VERSION "eCMP INFO-DIV vehicle review 2026-11-03; 125000 bit/s; PSA-RE 67f7581e7622410efdbb29c7eda3b86982b9b450; Apache-2.0"

NS_ :

BS_:

BU_: AAS AMPLI AVP BCM BGP BSG BSI BTA BTEL BTT CDC CMB CRT DIAG_TOOL EDP_C EMF FMUX IC ICSV IDVR IVC_D MATT MDS OVIP PDS_C RAD RBG SDCM VTH WLC

BO_ 0 ICSV_SeatClimateModuleSta_196f6d: 8 ICSV
 SG_ RawByte8 : 63|8@0+ (1,0) [0|255] "raw" Vector__XXX
 SG_ EspDisconnectRequest : 48|1@0+ (1,0) [0|1] ""  AAS,AVP,BTEL,CMB,MDS,OVIP
 SG_ BrakeAssistFaultLampRequest : 49|1@0+ (1,0) [0|1] ""  AAS,AVP,BTEL,CMB,MDS,OVIP
 SG_ StaticSlopeState : 51|2@0+ (1,0) [0|3] ""  AAS,AVP,BTEL,CMB,MDS,OVIP
 SG_ BrakeFunctionNeedForStartStop : 53|2@0+ (1,0) [0|3] ""  AAS,AVP,BTEL,CMB,MDS,OVIP
 SG_ BrakeEcuPowerManagementFault : 54|1@0+ (1,0) [0|1] ""  AAS,AVP,BTEL,CMB,MDS,OVIP
 SG_ EmergencyBrakingSignaliza_517ee3 : 55|1@0+ (1,0) [0|1] ""  AAS,AVP,BTEL,CMB,MDS,OVIP
 SG_ BatteryVoltageUcBrake : 47|8@0+ (0.057,0) [7|18.5] "V"  AAS,AVP,BTEL,CMB,MDS,OVIP
 SG_ RearRightWheelSpinCounter : 30|15@0+ (1,0) [0|32767] ""  AAS,AVP,BTEL,CMB,MDS,OVIP
 SG_ RearRightWheelSpeedSensorFault : 31|1@0+ (1,0) [0|1] ""  AAS,AVP,BTEL,CMB,MDS,OVIP
 SG_ RearLeftWheelSpinCounter : 14|15@0+ (1,0) [0|32767] ""  AAS,AVP,BTEL,CMB,MDS,OVIP
 SG_ RearLeftWheelSpeedSensorFault : 15|1@0+ (1,0) [0|1] ""  AAS,AVP,BTEL,CMB,MDS,OVIP
 SG_ AbsFaultLampRequest : 0|1@0+ (1,0) [0|1] ""  AAS,AVP,BTEL,CMB,MDS,OVIP
 SG_ BrakeFluidLevelAlert : 1|1@0+ (1,0) [0|1] ""  AAS,AVP,BTEL,CMB,MDS,OVIP
 SG_ WornBrakePadsIndicator : 2|1@0+ (1,0) [0|1] ""  AAS,AVP,BTEL,CMB,MDS,OVIP
 SG_ RefInProgress : 3|1@0+ (1,0) [0|1] ""  AAS,AVP,BTEL,CMB,MDS,OVIP
 SG_ AutomaticHazardLightsByUcBrake : 4|1@0+ (1,0) [0|1] ""  AAS,AVP,BTEL,CMB,MDS,OVIP
 SG_ AbsInProgress : 5|1@0+ (1,0) [0|1] ""  AAS,AVP,BTEL,CMB,MDS,OVIP
 SG_ RawBits1_1 : 6|1@0+ (1,0) [0|1] "raw" Vector__XXX
 SG_ RefFaultLamp : 7|1@0+ (1,0) [0|1] ""  AAS,AVP,BTEL,CMB,MDS,OVIP

BO_ 1 BSI_RapidCommand: 1 BSI
 SG_ Unused1 : 6|7@0+ (1,0) [0|127] ""  SDCM
 SG_ UidTableLearnRequestToBsi : 7|1@0+ (1,0) [0|1] ""  SDCM

BO_ 2 BSI_AdditivePumpStatus: 7 BSI
 SG_ AcPrecondSchedule2StartTime : 42|11@0+ (1,0) [0|1440] "min"  BTEL,MDS,OVIP
 SG_ RawBits40_44 : 47|5@0+ (1,0) [0|31] "raw" Vector__XXX
 SG_ AcPrecondSundaySchedule2Active : 32|1@0+ (1,0) [0|1] ""  BTEL,MDS,OVIP
 SG_ AcPrecondSaturdaySchedule2Active : 33|1@0+ (1,0) [0|1] ""  BTEL,MDS,OVIP
 SG_ AcPrecondFridaySchedule2Active : 34|1@0+ (1,0) [0|1] ""  BTEL,MDS,OVIP
 SG_ AcPrecondThursdaySchedule2Active : 35|1@0+ (1,0) [0|1] ""  BTEL,MDS,OVIP
 SG_ AcPrecondWednesdaySchedul_14303b : 36|1@0+ (1,0) [0|1] ""  BTEL,MDS,OVIP
 SG_ AcPrecondTuesdaySchedule2Active : 37|1@0+ (1,0) [0|1] ""  BTEL,MDS,OVIP
 SG_ AcPrecondMondaySchedule2Active : 38|1@0+ (1,0) [0|1] ""  BTEL,MDS,OVIP
 SG_ AcPrecondSchedule2Enabled : 39|1@0+ (1,0) [0|1] ""  BTEL,MDS,OVIP
 SG_ AcPrecondSchedule1StartTime : 18|11@0+ (1,0) [0|1440] "min"  BTEL,MDS,OVIP
 SG_ RawBits16_20 : 23|5@0+ (1,0) [0|31] "raw" Vector__XXX
 SG_ AcPrecondSundaySchedule1Active : 8|1@0+ (1,0) [0|1] ""  BTEL,MDS,OVIP
 SG_ AcPrecondSaturdaySchedule1Active : 9|1@0+ (1,0) [0|1] ""  BTEL,MDS,OVIP
 SG_ AcPrecondFridaySchedule1Active : 10|1@0+ (1,0) [0|1] ""  BTEL,MDS,OVIP
 SG_ AcPrecondThursdaySchedule1Active : 11|1@0+ (1,0) [0|1] ""  BTEL,MDS,OVIP
 SG_ AcPrecondWednesdaySchedul_0079d6 : 12|1@0+ (1,0) [0|1] ""  BTEL,MDS,OVIP
 SG_ AcPrecondTuesdaySchedule1Active : 13|1@0+ (1,0) [0|1] ""  BTEL,MDS,OVIP
 SG_ AcPrecondMondaySchedule1Active : 14|1@0+ (1,0) [0|1] ""  BTEL,MDS,OVIP
 SG_ AcPrecondSchedule1Enabled : 15|1@0+ (1,0) [0|1] ""  BTEL,MDS,OVIP
 SG_ RawBits6_7 : 1|2@0+ (1,0) [0|3] "raw" Vector__XXX
 SG_ AcPrecondAsapModeActive : 2|1@0+ (1,0) [0|1] ""  BTEL,MDS,OVIP
 SG_ AcPrecondStatusFeedback : 6|4@0+ (1,0) [0|15] ""  BTEL,MDS,OVIP
 SG_ AcPrecondStatusAvailability : 7|1@0+ (1,0) [0|1] ""  BTEL,MDS,OVIP

BO_ 24 BSI_AirIntakeMotorCommand3: 5 BSI
 SG_ Unused4 : 39|8@0+ (1,0) [0|255] ""  RAD,MDS,IDVR,BTEL
 SG_ Unused3 : 30|7@0+ (1,0) [0|127] ""  RAD,MDS,IDVR,BTEL
 SG_ Unused2 : 31|1@0+ (1,0) [0|1] ""  RAD,MDS,IDVR,BTEL
 SG_ PedestrianCrashInfo : 16|1@0+ (1,0) [0|1] ""  RAD,MDS,IDVR,BTEL
 SG_ AutomaticEcallTrigger : 18|2@0+ (1,0) [0|3] ""  RAD,MDS,IDVR,BTEL
 SG_ Unused1 : 22|4@0+ (1,0) [0|15] ""  RAD,MDS,IDVR,BTEL
 SG_ CrashUnlockRequest : 23|1@0+ (1,0) [0|1] ""  RAD,MDS,IDVR,BTEL
 SG_ CrashDetectedSinceLastPowerUp : 8|1@0+ (1,0) [0|1] ""  RAD,MDS,IDVR,BTEL
 SG_ RolloverCrash : 9|1@0+ (1,0) [0|1] ""  RAD,MDS,IDVR,BTEL
 SG_ HighSpeedRearCrash : 10|1@0+ (1,0) [0|1] ""  RAD,MDS,IDVR,BTEL
 SG_ AverageSpeedRearCrash : 11|1@0+ (1,0) [0|1] ""  RAD,MDS,IDVR,BTEL
 SG_ LowSpeedRearCrash : 12|1@0+ (1,0) [0|1] ""  RAD,MDS,IDVR,BTEL
 SG_ PossibleRearCrash : 13|1@0+ (1,0) [0|1] ""  RAD,MDS,IDVR,BTEL
 SG_ HighSpeedSideCrash : 14|1@0+ (1,0) [0|1] ""  RAD,MDS,IDVR,BTEL
 SG_ AverageSpeedSideCrash : 15|1@0+ (1,0) [0|1] ""  RAD,MDS,IDVR,BTEL
 SG_ LowSpeedSideCrash : 0|1@0+ (1,0) [0|1] ""  RAD,MDS,IDVR,BTEL
 SG_ PossibleSideCrash : 1|1@0+ (1,0) [0|1] ""  RAD,MDS,IDVR,BTEL
 SG_ HighSpeedFrontalCrash : 2|1@0+ (1,0) [0|1] ""  RAD,MDS,IDVR,BTEL
 SG_ AverageSpeedFrontalCrashN2 : 3|1@0+ (1,0) [0|1] ""  RAD,MDS,IDVR,BTEL
 SG_ AverageSpeedFrontalCrashN1 : 4|1@0+ (1,0) [0|1] ""  RAD,MDS,IDVR,BTEL
 SG_ LowSpeedFrontalCrash : 5|1@0+ (1,0) [0|1] ""  RAD,MDS,IDVR,BTEL
 SG_ PossibleFrontalCrash : 6|1@0+ (1,0) [0|1] ""  RAD,MDS,IDVR,BTEL
 SG_ PassengerAirbagInhibitionStatus : 7|1@0+ (1,0) [0|1] ""  RAD,MDS,IDVR,BTEL

BO_ 28 ICSV_MotionSensorCommandRight: 8 ICSV
 SG_ SpeedLimitZone5Speed : 63|8@0+ (1,0) [0|254] "km/h"  BSI
 SG_ SpeedLimitZone4Speed : 55|8@0+ (1,0) [0|254] "km/h"  BSI
 SG_ SpeedLimitZone3Speed : 47|8@0+ (1,0) [0|254] "km/h"  BSI
 SG_ SpeedLimitZone2Speed : 39|8@0+ (1,0) [0|254] "km/h"  BSI
 SG_ SpeedLimitZone1Speed : 31|8@0+ (1,0) [0|254] "km/h"  BSI
 SG_ SpeedLimitZone5State : 16|1@0+ (1,0) [0|1] ""  BSI
 SG_ SpeedLimitZone4State : 17|1@0+ (1,0) [0|1] ""  BSI
 SG_ SpeedLimitZone3State : 18|1@0+ (1,0) [0|1] ""  BSI
 SG_ SpeedLimitZone2State : 19|1@0+ (1,0) [0|1] ""  BSI
 SG_ SpeedLimitZone1State : 20|1@0+ (1,0) [0|1] ""  BSI
 SG_ Unused2 : 21|1@0+ (1,0) [0|1] ""  BSI
 SG_ SpeedLimitMainState : 22|1@0+ (1,0) [0|1] ""  BSI
 SG_ CruiseMenuInfoAvailability : 23|1@0+ (1,0) [0|1] ""  BSI
 SG_ PreconditioningClockSelection : 3|12@0+ (1,0) [0|1439] "min"  BSI
 SG_ PreconditioningActivationRequest : 4|1@0+ (1,0) [0|1] ""  BSI
 SG_ PreconditioningTypeRequest : 5|1@0+ (1,0) [0|1] ""  BSI
 SG_ PreconditioningDataValidity : 6|1@0+ (1,0) [0|1] ""  BSI
 SG_ Unused1 : 7|1@0+ (1,0) [0|1] ""  BSI

BO_ 29 SDCM_WakeupMus: 1 SDCM
 SG_ Unused1 : 6|7@0+ (1,0) [0|127] ""  BSI
 SG_ HandshakeSdcmToBsi : 7|1@0+ (1,0) [0|1] ""  BSI

BO_ 30 BSI_WakeupSir: 1 BSI
 SG_ Unused1 : 6|7@0+ (1,0) [0|127] ""  SDCM
 SG_ HandshakeBsiToSdcm : 7|1@0+ (1,0) [0|1] ""  SDCM

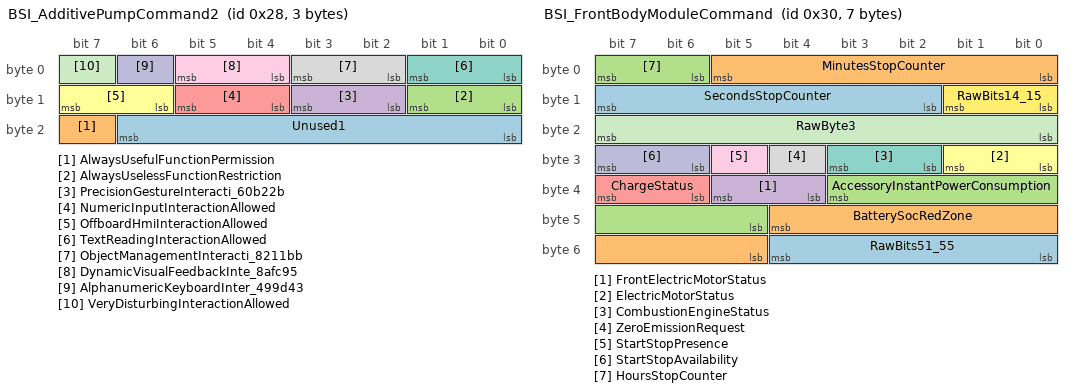
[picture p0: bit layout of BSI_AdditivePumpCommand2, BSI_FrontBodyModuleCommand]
BO_ 40 BSI_AdditivePumpCommand2: 3 BSI
 SG_ Unused1 : 22|7@0+ (1,0) [0|127] ""  BTEL,OVIP,RAD
 SG_ AlwaysUsefulFunctionPermission : 23|1@0+ (1,0) [0|1] ""  BTEL,OVIP,RAD
 SG_ AlwaysUselessFunctionRestriction : 9|2@0+ (1,0) [0|3] ""  BTEL,OVIP,RAD
 SG_ PrecisionGestureInteracti_60b22b : 11|2@0+ (1,0) [0|3] ""  BTEL,OVIP,RAD
 SG_ NumericInputInteractionAllowed : 13|2@0+ (1,0) [0|3] ""  BTEL,OVIP,RAD
 SG_ OffboardHmiInteractionAllowed : 15|2@0+ (1,0) [0|3] ""  BTEL,OVIP,RAD
 SG_ TextReadingInteractionAllowed : 1|2@0+ (1,0) [0|3] ""  BTEL,OVIP,RAD
 SG_ ObjectManagementInteracti_8211bb : 3|2@0+ (1,0) [0|3] ""  BTEL,OVIP,RAD
 SG_ DynamicVisualFeedbackInte_8afc95 : 5|2@0+ (1,0) [0|3] ""  BTEL,OVIP,RAD
 SG_ AlphanumericKeyboardInter_499d43 : 6|1@0+ (1,0) [0|1] ""  BTEL,OVIP,RAD
 SG_ VeryDisturbingInteractionAllowed : 7|1@0+ (1,0) [0|1] ""  BTEL,OVIP,RAD

BO_ 48 BSI_FrontBodyModuleCommand: 7 BSI
 SG_ RawBits51_55 : 52|5@0+ (1,0) [0|31] "raw" Vector__XXX
 SG_ BatterySocRedZone : 44|8@0+ (1,0) [0|100] "%"  BTEL,CMB,EMF,MATT,OVIP,ICSV
 SG_ AccessoryInstantPowerConsumption : 35|7@0+ (1,0) [0|100] "%"  BTEL,CMB,EMF,MATT,OVIP,ICSV
 SG_ FrontElectricMotorStatus : 37|2@0+ (1,0) [0|3] ""  BTEL,CMB,EMF,MATT,OVIP,ICSV
 SG_ ChargeStatus : 39|2@0+ (1,0) [0|3] ""  BTEL,CMB,EMF,MATT,OVIP,ICSV
 SG_ ElectricMotorStatus : 25|2@0+ (1,0) [0|3] ""  BTEL,CMB,EMF,MATT,OVIP,ICSV
 SG_ CombustionEngineStatus : 27|2@0+ (1,0) [0|3] ""  BTEL,CMB,EMF,MATT,OVIP,ICSV
 SG_ ZeroEmissionRequest : 28|1@0+ (1,0) [0|1] ""  BTEL,CMB,EMF,MATT,OVIP,ICSV
 SG_ StartStopPresence : 29|1@0+ (1,0) [0|1] ""  BTEL,CMB,EMF,MATT,OVIP,ICSV
 SG_ StartStopAvailability : 31|2@0+ (1,0) [0|3] ""  BTEL,CMB,EMF,MATT,OVIP,ICSV
 SG_ RawByte3 : 23|8@0+ (1,0) [0|255] "raw" Vector__XXX
 SG_ RawBits14_15 : 9|2@0+ (1,0) [0|3] "raw" Vector__XXX
 SG_ SecondsStopCounter : 15|6@0+ (1,0) [0|59] "s"  BTEL,CMB,EMF,MATT,OVIP,ICSV
 SG_ MinutesStopCounter : 5|6@0+ (1,0) [0|59] "min"  BTEL,CMB,EMF,MATT,OVIP,ICSV
 SG_ HoursStopCounter : 7|2@0+ (1,0) [0|3] "h"  BTEL,CMB,EMF,MATT,OVIP,ICSV

BO_ 54 BSI_RadioCommands: 8 BSI
 SG_ TePosition : 56|1@0+ (1,0) [0|1] ""  SDCM,CRT,ICSV,AAS,CMB,EMF,RAD,VTH,CDC,AMPLI,BTEL,MDS,MATT,FMUX,AVP,RBG,OVIP,IDVR
 SG_ AudioInviolability : 57|1@0+ (1,0) [0|1] ""  SDCM,CRT,ICSV,AAS,CMB,EMF,RAD,VTH,CDC,AMPLI,BTEL,MDS,MATT,FMUX,AVP,RBG,OVIP,IDVR
 SG_ EngineBayAccPowerCommand : 59|2@0+ (1,0) [0|3] ""  SDCM,CRT,ICSV,AAS,CMB,EMF,RAD,VTH,CDC,AMPLI,BTEL,MDS,MATT,FMUX,AVP,RBG,OVIP,IDVR
 SG_ SecureInfo : 63|4@0+ (1,0) [0|15] ""  SDCM,CRT,ICSV,AAS,CMB,EMF,RAD,VTH,CDC,AMPLI,BTEL,MDS,MATT,FMUX,AVP,RBG,OVIP,IDVR
 SG_ RadioOnOffSync : 48|1@0+ (1,0) [0|1] ""  SDCM,CRT,ICSV,AAS,CMB,EMF,RAD,VTH,CDC,AMPLI,BTEL,MDS,MATT,FMUX,AVP,RBG,OVIP,IDVR
 SG_ RadioOnOffToggle : 49|1@0+ (1,0) [0|1] ""  SDCM,CRT,ICSV,AAS,CMB,EMF,RAD,VTH,CDC,AMPLI,BTEL,MDS,MATT,FMUX,AVP,RBG,OVIP,IDVR
 SG_ PreconditioningMenuPresence : 50|1@0+ (1,0) [0|1] ""  SDCM,CRT,ICSV,AAS,CMB,EMF,RAD,VTH,CDC,AMPLI,BTEL,MDS,MATT,FMUX,AVP,RBG,OVIP,IDVR
 SG_ AvrActivationStatus : 51|1@0+ (1,0) [0|1] ""  SDCM,CRT,ICSV,AAS,CMB,EMF,RAD,VTH,CDC,AMPLI,BTEL,MDS,MATT,FMUX,AVP,RBG,OVIP,IDVR
 SG_ CafrValidationCommand : 52|1@0+ (1,0) [0|1] ""  SDCM,CRT,ICSV,AAS,CMB,EMF,RAD,VTH,CDC,AMPLI,BTEL,MDS,MATT,FMUX,AVP,RBG,OVIP,IDVR
 SG_ Unused2 : 53|1@0+ (1,0) [0|1] ""  SDCM,CRT,ICSV,AAS,CMB,EMF,RAD,VTH,CDC,AMPLI,BTEL,MDS,MATT,FMUX,AVP,RBG,OVIP,IDVR
 SG_ SpeedDisplayOffset : 54|1@0+ (1,0) [0|1] ""  SDCM,CRT,ICSV,AAS,CMB,EMF,RAD,VTH,CDC,AMPLI,BTEL,MDS,MATT,FMUX,AVP,RBG,OVIP,IDVR
 SG_ MediaShutdownRequest : 55|1@0+ (1,0) [0|1] ""  SDCM,CRT,ICSV,AAS,CMB,EMF,RAD,VTH,CDC,AMPLI,BTEL,MDS,MATT,FMUX,AVP,RBG,OVIP,IDVR
 SG_ HybridModeUpdated : 40|1@0+ (1,0) [0|1] ""  SDCM,CRT,ICSV,AAS,CMB,EMF,RAD,VTH,CDC,AMPLI,BTEL,MDS,MATT,FMUX,AVP,RBG,OVIP,IDVR
 SG_ HybridMode : 43|3@0+ (1,0) [0|7] ""  SDCM,CRT,ICSV,AAS,CMB,EMF,RAD,VTH,CDC,AMPLI,BTEL,MDS,MATT,FMUX,AVP,RBG,OVIP,IDVR
 SG_ HybridStatusUpdated : 44|1@0+ (1,0) [0|1] ""  SDCM,CRT,ICSV,AAS,CMB,EMF,RAD,VTH,CDC,AMPLI,BTEL,MDS,MATT,FMUX,AVP,RBG,OVIP,IDVR
 SG_ HybridStatus : 47|3@0+ (1,0) [0|7] ""  SDCM,CRT,ICSV,AAS,CMB,EMF,RAD,VTH,CDC,AMPLI,BTEL,MDS,MATT,FMUX,AVP,RBG,OVIP,IDVR
 SG_ PowerManagement : 34|3@0+ (1,0) [0|7] ""  SDCM,CRT,ICSV,AAS,CMB,EMF,RAD,VTH,CDC,AMPLI,BTEL,MDS,MATT,FMUX,AVP,RBG,OVIP,IDVR
 SG_ LogFaults : 35|1@0+ (1,0) [0|1] ""  SDCM,CRT,ICSV,AAS,CMB,EMF,RAD,VTH,CDC,AMPLI,BTEL,MDS,MATT,FMUX,AVP,RBG,OVIP,IDVR
 SG_ DiagToolNetworkAuthorization : 36|1@0+ (1,0) [0|1] ""  SDCM,CRT,ICSV,AAS,CMB,EMF,RAD,VTH,CDC,AMPLI,BTEL,MDS,MATT,FMUX,AVP,RBG,OVIP,IDVR
 SG_ DiagStatus : 37|1@0+ (1,0) [0|1] ""  SDCM,CRT,ICSV,AAS,CMB,EMF,RAD,VTH,CDC,AMPLI,BTEL,MDS,MATT,FMUX,AVP,RBG,OVIP,IDVR
 SG_ ClearFaults : 38|1@0+ (1,0) [0|1] ""  SDCM,CRT,ICSV,AAS,CMB,EMF,RAD,VTH,CDC,AMPLI,BTEL,MDS,MATT,FMUX,AVP,RBG,OVIP,IDVR
 SG_ DynamicPackActivation : 39|1@0+ (1,0) [0|1] ""  SDCM,CRT,ICSV,AAS,CMB,EMF,RAD,VTH,CDC,AMPLI,BTEL,MDS,MATT,FMUX,AVP,RBG,OVIP,IDVR
 SG_ Brightness : 27|4@0+ (1,0) [0|15] ""  SDCM,CRT,ICSV,AAS,CMB,EMF,RAD,VTH,CDC,AMPLI,BTEL,MDS,MATT,FMUX,AVP,RBG,OVIP,IDVR
 SG_ DarkMode : 28|1@0+ (1,0) [0|1] ""  SDCM,CRT,ICSV,AAS,CMB,EMF,RAD,VTH,CDC,AMPLI,BTEL,MDS,MATT,FMUX,AVP,RBG,OVIP,IDVR
 SG_ DaynightStatus : 29|1@0+ (1,0) [0|1] ""  SDCM,CRT,ICSV,AAS,CMB,EMF,RAD,VTH,CDC,AMPLI,BTEL,MDS,MATT,FMUX,AVP,RBG,OVIP,IDVR
 SG_ RheostatType : 30|1@0+ (1,0) [0|1] ""  SDCM,CRT,ICSV,AAS,CMB,EMF,RAD,VTH,CDC,AMPLI,BTEL,MDS,MATT,FMUX,AVP,RBG,OVIP,IDVR
 SG_ Resynchronization : 31|1@0+ (1,0) [0|1] ""  SDCM,CRT,ICSV,AAS,CMB,EMF,RAD,VTH,CDC,AMPLI,BTEL,MDS,MATT,FMUX,AVP,RBG,OVIP,IDVR
 SG_ AmbientLightLevelFmux : 22|7@0+ (1,0) [0|100] "%"  SDCM,CRT,ICSV,AAS,CMB,EMF,RAD,VTH,CDC,AMPLI,BTEL,MDS,MATT,FMUX,AVP,RBG,OVIP,IDVR
 SG_ EcoMode : 23|1@0+ (1,0) [0|1] ""  SDCM,CRT,ICSV,AAS,CMB,EMF,RAD,VTH,CDC,AMPLI,BTEL,MDS,MATT,FMUX,AVP,RBG,OVIP,IDVR
 SG_ Unused1 : 15|8@0+ (1,0) [0|255] ""  SDCM,CRT,ICSV,AAS,CMB,EMF,RAD,VTH,CDC,AMPLI,BTEL,MDS,MATT,FMUX,AVP,RBG,OVIP,IDVR
 SG_ DriverMemoryCount : 3|4@0+ (1,0) [1|14] ""  SDCM,CRT,ICSV,AAS,CMB,EMF,RAD,VTH,CDC,AMPLI,BTEL,MDS,MATT,FMUX,AVP,RBG,OVIP,IDVR
 SG_ DriverMemorySave : 4|1@0+ (1,0) [0|1] ""  SDCM,CRT,ICSV,AAS,CMB,EMF,RAD,VTH,CDC,AMPLI,BTEL,MDS,MATT,FMUX,AVP,RBG,OVIP,IDVR
 SG_ DriverMemory : 5|1@0+ (1,0) [0|1] ""  SDCM,CRT,ICSV,AAS,CMB,EMF,RAD,VTH,CDC,AMPLI,BTEL,MDS,MATT,FMUX,AVP,RBG,OVIP,IDVR
 SG_ VehicleDirection : 7|2@0+ (1,0) [0|3] ""  SDCM,CRT,ICSV,AAS,CMB,EMF,RAD,VTH,CDC,AMPLI,BTEL,MDS,MATT,FMUX,AVP,RBG,OVIP,IDVR

BO_ 65 SDCM_UidTableLearnRequestToSdcm: 1 SDCM
 SG_ Unused1 : 6|7@0+ (1,0) [0|127] ""  BSI
 SG_ UidTableLearnRequestToSdcm : 7|1@0+ (1,0) [0|1] ""  BSI

BO_ 77 SDCM_UncipheredDataSdcmToBsi: 8 SDCM
 SG_ SmartDeviceCommandToBsi : 63|8@0+ (1,0) [0|255] "raw"  BSI
 SG_ Unused1 : 55|8@0+ (1,0) [0|255] ""  BSI
 SG_ Cid5Status : 40|1@0+ (1,0) [0|1] ""  BSI
 SG_ Cid4Status : 41|1@0+ (1,0) [0|1] ""  BSI
 SG_ Cid3Status : 42|1@0+ (1,0) [0|1] ""  BSI
 SG_ Cid2Status : 43|1@0+ (1,0) [0|1] ""  BSI
 SG_ BlacklistingTaskStatus : 45|2@0+ (1,0) [0|3] ""  BSI
 SG_ NfcIdentifiedOutside : 47|2@0+ (1,0) [0|3] ""  BSI
 SG_ Cid1Status : 32|1@0+ (1,0) [0|1] ""  BSI
 SG_ AuthenticatedDeviceNumber : 36|4@0+ (1,0) [0|15] ""  BSI
 SG_ NfcCardNumber : 39|3@0+ (1,0) [0|7] ""  BSI
 SG_ SmartDeviceNumber : 26|3@0+ (1,0) [0|7] ""  BSI
 SG_ HandsfreeCidNumber : 29|3@0+ (1,0) [0|7] ""  BSI
 SG_ SmartDeviceBtAuthenticati_9fe3dd : 31|2@0+ (1,0) [0|3] ""  BSI
 SG_ SmartDeviceNfcAuthenticat_6dabc9 : 17|2@0+ (1,0) [0|3] ""  BSI
 SG_ NfcCardAuthenticationResult : 19|2@0+ (1,0) [0|3] ""  BSI
 SG_ CidAuthenticationResult : 21|2@0+ (1,0) [0|3] ""  BSI
 SG_ CidFoundInLockArea : 23|2@0+ (1,0) [0|3] ""  BSI
 SG_ CidSearchAnswer : 9|2@0+ (1,0) [0|3] ""  BSI
 SG_ CidOutsideSearchStatus : 11|2@0+ (1,0) [0|3] ""  BSI
 SG_ CidFoundInside : 13|2@0+ (1,0) [0|3] ""  BSI
 SG_ CidInsideSearchStatus : 15|2@0+ (1,0) [0|3] ""  BSI
 SG_ HandsfreeClosureButtonAction : 1|2@0+ (1,0) [0|3] ""  BSI
 SG_ HandsfreeClosureButton : 3|2@0+ (1,0) [0|3] ""  BSI
 SG_ HandsfreeAreaTransition : 7|4@0+ (1,0) [0|15] ""  BSI

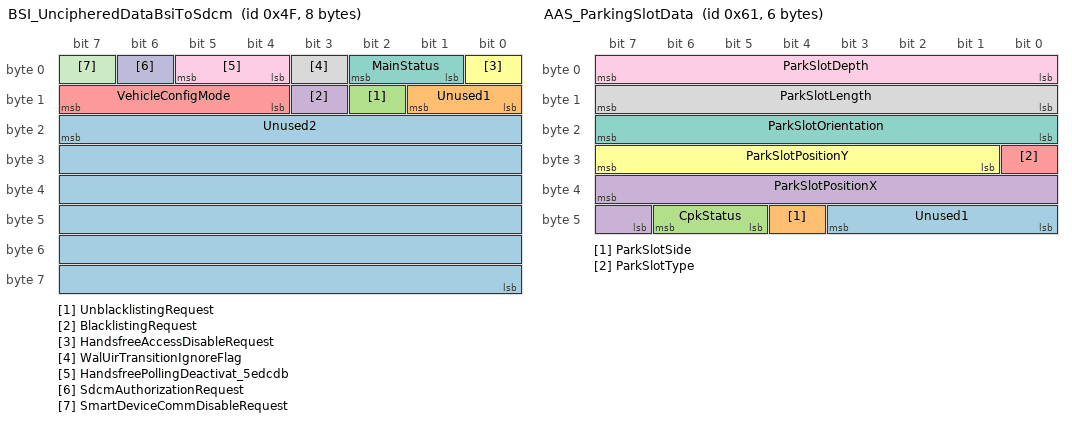
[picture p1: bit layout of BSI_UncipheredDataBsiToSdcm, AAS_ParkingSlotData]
BO_ 79 BSI_UncipheredDataBsiToSdcm: 8 BSI
 SG_ Unused2 : 23|48@0+ (1,0) [0|281474976710655] ""  SDCM
 SG_ Unused1 : 9|2@0+ (1,0) [0|3] ""  SDCM
 SG_ UnblacklistingRequest : 10|1@0+ (1,0) [0|1] ""  SDCM
 SG_ BlacklistingRequest : 11|1@0+ (1,0) [0|1] ""  SDCM
 SG_ VehicleConfigMode : 15|4@0+ (1,0) [0|15] ""  SDCM
 SG_ HandsfreeAccessDisableRequest : 0|1@0+ (1,0) [0|1] ""  SDCM
 SG_ MainStatus : 2|2@0+ (1,0) [0|3] ""  SDCM
 SG_ WalUirTransitionIgnoreFlag : 3|1@0+ (1,0) [0|1] ""  SDCM
 SG_ HandsfreePollingDeactivat_5edcdb : 5|2@0+ (1,0) [0|3] ""  SDCM
 SG_ SdcmAuthorizationRequest : 6|1@0+ (1,0) [0|1] ""  SDCM
 SG_ SmartDeviceCommDisableRequest : 7|1@0+ (1,0) [0|1] ""  SDCM

BO_ 97 AAS_ParkingSlotData: 6 AAS
 SG_ Unused1 : 43|4@0+ (1,0) [0|15] ""  AVP
 SG_ ParkSlotSide : 44|1@0+ (1,0) [0|1] ""  AVP
 SG_ CpkStatus : 46|2@0+ (1,0) [0|3] ""  AVP
 SG_ ParkSlotPositionX : 39|9@0+ (4,-1020) [-1020|1024] "cm"  AVP
 SG_ ParkSlotType : 24|1@0+ (1,0) [0|1] ""  AVP
 SG_ ParkSlotPositionY : 31|7@0+ (4,-252) [-252|252] "cm"  AVP
 SG_ ParkSlotOrientation : 23|8@0+ (1,0) [0|255] "°"  AVP
 SG_ ParkSlotLength : 15|8@0+ (4,0) [0|1020] "cm"  AVP
 SG_ ParkSlotDepth : 7|8@0+ (4,0) [0|1020] "cm"  AVP

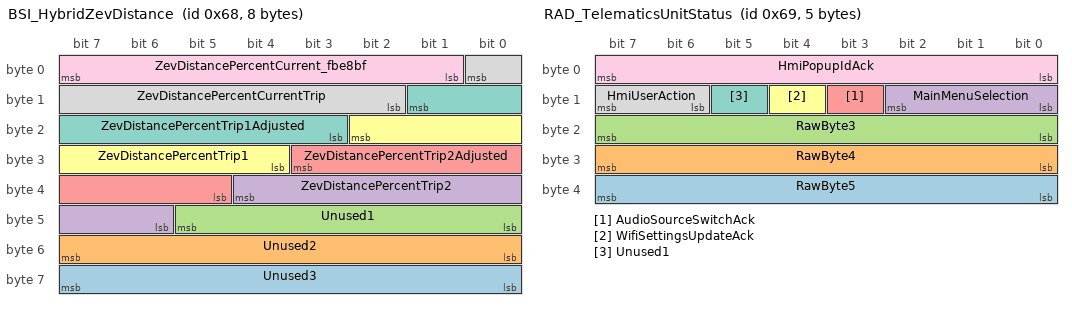
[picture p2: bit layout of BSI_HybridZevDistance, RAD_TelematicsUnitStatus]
BO_ 104 BSI_HybridZevDistance: 8 BSI
 SG_ Unused3 : 63|8@0+ (1,0) [0|255] ""  OVIP,RAD
 SG_ Unused2 : 55|8@0+ (1,0) [0|255] ""  OVIP,RAD
 SG_ Unused1 : 45|6@0+ (1,0) [0|63] ""  OVIP,RAD
 SG_ ZevDistancePercentTrip2 : 36|7@0+ (1,0) [0|100] "%"  OVIP,RAD
 SG_ ZevDistancePercentTrip2Adjusted : 27|7@0+ (1,0) [0|100] "%"  OVIP,RAD
 SG_ ZevDistancePercentTrip1 : 18|7@0+ (1,0) [0|100] "%"  OVIP,RAD
 SG_ ZevDistancePercentTrip1Adjusted : 9|7@0+ (1,0) [0|100] "%"  OVIP,RAD
 SG_ ZevDistancePercentCurrentTrip : 0|7@0+ (1,0) [0|100] "%"  OVIP,RAD
 SG_ ZevDistancePercentCurrent_fbe8bf : 7|7@0+ (1,0) [0|100] "%"  OVIP,RAD

BO_ 105 RAD_TelematicsUnitStatus: 5 RAD
 SG_ RawByte5 : 39|8@0+ (1,0) [0|255] "raw" Vector__XXX
 SG_ RawByte4 : 31|8@0+ (1,0) [0|255] "raw" Vector__XXX
 SG_ RawByte3 : 23|8@0+ (1,0) [0|255] "raw" Vector__XXX
 SG_ MainMenuSelection : 10|3@0+ (1,0) [0|7] ""  MDS
 SG_ AudioSourceSwitchAck : 11|1@0+ (1,0) [0|1] ""  MDS
 SG_ WifiSettingsUpdateAck : 12|1@0+ (1,0) [0|1] ""  MDS
 SG_ Unused1 : 13|1@0+ (1,0) [0|1] ""  MDS
 SG_ HmiUserAction : 15|2@0+ (1,0) [0|3] ""  MDS
 SG_ HmiPopupIdAck : 7|8@0+ (1,0) [0|255] ""  MDS

BO_ 112 SDCM_EncryptedDataDown: 8 SDCM
 SG_ SdcmToBsiCipheredOrder : 7|64@0+ (1,0) [0|18446744073709551615] "raw"  BSI

BO_ 115 BSI_SdcmEncryptedDataUp: 8 BSI
 SG_ CipheredOrderBsiToSdcm : 7|64@0+ (1,0) [0|18446744073709551615] "raw"  SDCM

BO_ 125 SDCM_RandomBUplinkSdcmBsi: 8 SDCM
 SG_ SdcmToBsiCipherSyncB : 7|64@0+ (1,0) [0|18446744073709551615] ""  BSI

BO_ 127 BSI_RandomBDownlinkBsiSdcm: 8 BSI
 SG_ BsiToSdcmCipherSyncB : 7|64@0+ (1,0) [0|18446744073709551615] ""  SDCM

BO_ 141 SDCM_AuthChallengeDown: 8 SDCM
 SG_ SdcmToBsiCipherSync : 7|64@0+ (1,0) [0|18446744073709551615] "raw"  BSI

BO_ 143 BSI_SdcmAuthChallengeUp: 8 BSI
 SG_ BsiToSdcmCipherSync : 7|64@0+ (1,0) [0|18446744073709551615] "raw"  SDCM

BO_ 159 EMF_RadioTextReplyFlowControl: 8 EMF
 SG_ FlowPadding5 m3 : 63|8@0+ (1,0) [0|255] "raw"  RAD
 SG_ FirstData6 m1 : 63|8@0+ (1,0) [0|255] "raw"  RAD
 SG_ UnknownData7 m4 : 63|8@0+ (1,0) [0|255] "raw"  RAD
 SG_ ConsecutiveData7 m2 : 63|8@0+ (1,0) [0|255] "raw"  RAD
 SG_ SingleData7 m0 : 63|8@0+ (1,0) [0|255] "raw"  RAD
 SG_ FlowPadding4 m3 : 55|8@0+ (1,0) [0|255] "raw"  RAD
 SG_ FirstData5 m1 : 55|8@0+ (1,0) [0|255] "raw"  RAD
 SG_ UnknownData6 m4 : 55|8@0+ (1,0) [0|255] "raw"  RAD
 SG_ ConsecutiveData6 m2 : 55|8@0+ (1,0) [0|255] "raw"  RAD
 SG_ SingleData6 m0 : 55|8@0+ (1,0) [0|255] "raw"  RAD
 SG_ FlowPadding3 m3 : 47|8@0+ (1,0) [0|255] "raw"  RAD
 SG_ FirstData4 m1 : 47|8@0+ (1,0) [0|255] "raw"  RAD
 SG_ UnknownData5 m4 : 47|8@0+ (1,0) [0|255] "raw"  RAD
 SG_ ConsecutiveData5 m2 : 47|8@0+ (1,0) [0|255] "raw"  RAD
 SG_ SingleData5 m0 : 47|8@0+ (1,0) [0|255] "raw"  RAD
 SG_ FlowPadding2 m3 : 39|8@0+ (1,0) [0|255] "raw"  RAD
 SG_ FirstData3 m1 : 39|8@0+ (1,0) [0|255] "raw"  RAD
 SG_ UnknownData4 m4 : 39|8@0+ (1,0) [0|255] "raw"  RAD
 SG_ ConsecutiveData4 m2 : 39|8@0+ (1,0) [0|255] "raw"  RAD
 SG_ SingleData4 m0 : 39|8@0+ (1,0) [0|255] "raw"  RAD
 SG_ FlowPadding1 m3 : 31|8@0+ (1,0) [0|255] "raw"  RAD
 SG_ FirstData2 m1 : 31|8@0+ (1,0) [0|255] "raw"  RAD
 SG_ UnknownData3 m4 : 31|8@0+ (1,0) [0|255] "raw"  RAD
 SG_ ConsecutiveData3 m2 : 31|8@0+ (1,0) [0|255] "raw"  RAD
 SG_ SingleData3 m0 : 31|8@0+ (1,0) [0|255] "raw"  RAD
 SG_ FirstData1 m1 : 23|8@0+ (1,0) [0|255] "raw"  RAD
 SG_ UnknownData2 m4 : 23|8@0+ (1,0) [0|255] "raw"  RAD
 SG_ ConsecutiveData2 m2 : 23|8@0+ (1,0) [0|255] "raw"  RAD
 SG_ SingleData2 m0 : 23|8@0+ (1,0) [0|255] "raw"  RAD
 SG_ SeparationTimeRaw m3 : 23|8@0+ (1,0) [0|255] "raw"  RAD
 SG_ UnknownData1 m4 : 15|8@0+ (1,0) [0|255] "raw"  RAD
 SG_ ConsecutiveData1 m2 : 15|8@0+ (1,0) [0|255] "raw"  RAD
 SG_ SingleData1 m0 : 15|8@0+ (1,0) [0|255] "raw"  RAD
 SG_ BlockSize m3 : 15|8@0+ (1,0) [0|255] "raw"  RAD
 SG_ UnknownPciLow m4 : 3|4@0+ (1,0) [0|15] "raw"  RAD
 SG_ FlowStatus m3 : 3|4@0+ (1,0) [0|15] "raw"  RAD
 SG_ ConsecutiveSequence m2 : 3|4@0+ (1,0) [0|15] "raw"  RAD
 SG_ FirstFrameLength m1 : 3|12@0+ (1,0) [0|4095] "raw"  RAD
 SG_ SingleFrameLength m0 : 3|4@0+ (1,0) [0|15] "raw"  RAD
 SG_ IsoTpFrameType M : 7|4@0+ (1,0) [0|15] ""  RAD

BO_ 161 AAS_AutomatedParkingStatus: 8 AAS
 SG_ Unused4 : 56|1@0+ (1,0) [0|1] ""  ICSV,AVP,CMB,BSI,BTEL,OVIP,RAD
 SG_ AcpkVehicleTooFast : 57|1@0+ (1,0) [0|1] ""  ICSV,AVP,CMB,BSI,BTEL,OVIP,RAD
 SG_ AcpkGearboxNeutralStatus : 58|1@0+ (1,0) [0|1] ""  ICSV,AVP,CMB,BSI,BTEL,OVIP,RAD
 SG_ AcpkManeuverSide : 59|1@0+ (1,0) [0|1] ""  ICSV,AVP,CMB,BSI,BTEL,OVIP,RAD
 SG_ AcpkManeuverState : 63|4@0+ (1,0) [0|15] ""  ICSV,AVP,CMB,BSI,BTEL,OVIP,RAD
 SG_ AcpkPreparationProgress : 51|4@0+ (10,0) [0|100] "%"  ICSV,AVP,CMB,BSI,BTEL,OVIP,RAD
 SG_ AcpkPreparationState : 55|4@0+ (1,0) [0|15] ""  ICSV,AVP,CMB,BSI,BTEL,OVIP,RAD
 SG_ AcpkBrakePedalStatus : 40|1@0+ (1,0) [0|1] ""  ICSV,AVP,CMB,BSI,BTEL,OVIP,RAD
 SG_ AcpkManeuverDirection : 42|2@0+ (1,0) [0|3] ""  ICSV,AVP,CMB,BSI,BTEL,OVIP,RAD
 SG_ AcpkManeuverType : 44|2@0+ (1,0) [0|3] ""  ICSV,AVP,CMB,BSI,BTEL,OVIP,RAD
 SG_ FrontLeftCenterObstacleDistance : 47|3@0+ (1,0) [0|7] ""  ICSV,AVP,CMB,BSI,BTEL,OVIP,RAD
 SG_ Unused3 : 32|1@0+ (1,0) [0|1] ""  ICSV,AVP,CMB,BSI,BTEL,OVIP,RAD
 SG_ FrontRightCenterObstacleDistance : 35|3@0+ (1,0) [0|7] ""  ICSV,AVP,CMB,BSI,BTEL,OVIP,RAD
 SG_ RearLeftCenterObstacleDistance : 39|4@0+ (1,0) [0|15] ""  ICSV,AVP,CMB,BSI,BTEL,OVIP,RAD
 SG_ RearRightCenterObstacleDistance : 27|4@0+ (1,0) [0|15] ""  ICSV,AVP,CMB,BSI,BTEL,OVIP,RAD
 SG_ FrontRightLateralObstacle_ef9eb7 : 29|2@0+ (1,0) [0|3] ""  ICSV,AVP,CMB,BSI,BTEL,OVIP,RAD
 SG_ CenterRightLateralObstacl_127351 : 31|2@0+ (1,0) [0|3] ""  ICSV,AVP,CMB,BSI,BTEL,OVIP,RAD
 SG_ RearRightLateralObstacleDistance : 17|2@0+ (1,0) [0|3] ""  ICSV,AVP,CMB,BSI,BTEL,OVIP,RAD
 SG_ FrontLeftLateralObstacleDistance : 19|2@0+ (1,0) [0|3] ""  ICSV,AVP,CMB,BSI,BTEL,OVIP,RAD
 SG_ CenterLeftLateralObstacle_db978a : 21|2@0+ (1,0) [0|3] ""  ICSV,AVP,CMB,BSI,BTEL,OVIP,RAD
 SG_ RearLeftLateralObstacleDistance : 23|2@0+ (1,0) [0|3] ""  ICSV,AVP,CMB,BSI,BTEL,OVIP,RAD
 SG_ SamActivityStatus : 10|3@0+ (1,0) [0|7] ""  ICSV,AVP,CMB,BSI,BTEL,OVIP,RAD
 SG_ SamLedRequest : 12|2@0+ (1,0) [0|3] ""  ICSV,AVP,CMB,BSI,BTEL,OVIP,RAD
 SG_ SamRightObjectPresent : 13|1@0+ (1,0) [0|1] ""  ICSV,AVP,CMB,BSI,BTEL,OVIP,RAD
 SG_ SamLeftObjectPresent : 14|1@0+ (1,0) [0|1] ""  ICSV,AVP,CMB,BSI,BTEL,OVIP,RAD
 SG_ Unused2 : 15|1@0+ (1,0) [0|1] ""  ICSV,AVP,CMB,BSI,BTEL,OVIP,RAD
 SG_ Unused1 : 3|4@0+ (1,0) [0|15] ""  ICSV,AVP,CMB,BSI,BTEL,OVIP,RAD
 SG_ CityParkHmiRequest : 7|4@0+ (1,0) [0|15] ""  ICSV,AVP,CMB,BSI,BTEL,OVIP,RAD

BO_ 162 BSI_SteeringWheelCommands: 6 BSI
 SG_ SteeringWheelVolumeCounter : 47|8@0- (1,0) [-128|127] ""  RAD,EMF,CMB,BTEL,MDS,MATT,FMUX,EDP_C,OVIP
 SG_ VolumeKnobScrollUnderflow : 32|1@0+ (1,0) [0|1] ""  RAD,EMF,CMB,BTEL,MDS,MATT,FMUX,EDP_C,OVIP
 SG_ VolumeKnobScrollOverflow : 33|1@0+ (1,0) [0|1] ""  RAD,EMF,CMB,BTEL,MDS,MATT,FMUX,EDP_C,OVIP
 SG_ Unused2 : 34|1@0+ (1,0) [0|1] ""  RAD,EMF,CMB,BTEL,MDS,MATT,FMUX,EDP_C,OVIP
 SG_ RecyclAirEtVmf : 35|1@0+ (1,0) [0|1] ""  RAD,EMF,CMB,BTEL,MDS,MATT,FMUX,EDP_C,OVIP
 SG_ CmbEscapeButton : 36|1@0+ (1,0) [0|1] ""  RAD,EMF,CMB,BTEL,MDS,MATT,FMUX,EDP_C,OVIP
 SG_ CmbValidationButton : 37|1@0+ (1,0) [0|1] ""  RAD,EMF,CMB,BTEL,MDS,MATT,FMUX,EDP_C,OVIP
 SG_ CmbNavMenuScrollUnderflow : 38|1@0+ (1,0) [0|1] ""  RAD,EMF,CMB,BTEL,MDS,MATT,FMUX,EDP_C,OVIP
 SG_ CmbNavMenuScrollOverflow : 39|1@0+ (1,0) [0|1] ""  RAD,EMF,CMB,BTEL,MDS,MATT,FMUX,EDP_C,OVIP
 SG_ CmbNavMenuCounter : 31|8@0- (1,0) [-128|127] ""  RAD,EMF,CMB,BTEL,MDS,MATT,FMUX,EDP_C,OVIP
 SG_ Unused1 : 22|7@0+ (1,0) [0|127] ""  RAD,EMF,CMB,BTEL,MDS,MATT,FMUX,EDP_C,OVIP
 SG_ SteeringWheelTelephoneCommand : 23|1@0+ (1,0) [0|1] ""  RAD,EMF,CMB,BTEL,MDS,MATT,FMUX,EDP_C,OVIP
 SG_ SteeringWheelVoiceCommand : 8|1@0+ (1,0) [0|1] ""  RAD,EMF,CMB,BTEL,MDS,MATT,FMUX,EDP_C,OVIP
 SG_ SteeringWheelLeftPush : 9|1@0+ (1,0) [0|1] ""  RAD,EMF,CMB,BTEL,MDS,MATT,FMUX,EDP_C,OVIP
 SG_ SteeringWheelModeButton : 10|1@0+ (1,0) [0|1] ""  RAD,EMF,CMB,BTEL,MDS,MATT,FMUX,EDP_C,OVIP
 SG_ SteeringWheelMenuButton : 11|1@0+ (1,0) [0|1] ""  RAD,EMF,CMB,BTEL,MDS,MATT,FMUX,EDP_C,OVIP
 SG_ SteeringWheelEscapeButton : 12|1@0+ (1,0) [0|1] ""  RAD,EMF,CMB,BTEL,MDS,MATT,FMUX,EDP_C,OVIP
 SG_ SteeringWheelValidationButton : 13|1@0+ (1,0) [0|1] ""  RAD,EMF,CMB,BTEL,MDS,MATT,FMUX,EDP_C,OVIP
 SG_ SteeringWheelNavMenuScrol_49cbf8 : 14|1@0+ (1,0) [0|1] ""  RAD,EMF,CMB,BTEL,MDS,MATT,FMUX,EDP_C,OVIP
 SG_ SteeringWheelNavMenuScrol_3fd970 : 15|1@0+ (1,0) [0|1] ""  RAD,EMF,CMB,BTEL,MDS,MATT,FMUX,EDP_C,OVIP
 SG_ SteeringWheelNavMenuScroll : 7|8@0- (1,0) [-128|127] ""  RAD,EMF,CMB,BTEL,MDS,MATT,FMUX,EDP_C,OVIP

BO_ 164 RAD_RadioTextReplyPayload: 8 RAD
 SG_ FlowPadding5 m3 : 63|8@0+ (1,0) [0|255] "raw"  FMUX,EMF
 SG_ FirstData6 m1 : 63|8@0+ (1,0) [0|255] "raw"  FMUX,EMF
 SG_ UnknownData7 m4 : 63|8@0+ (1,0) [0|255] "raw"  FMUX,EMF
 SG_ ConsecutiveData7 m2 : 63|8@0+ (1,0) [0|255] "raw"  FMUX,EMF
 SG_ SingleData7 m0 : 63|8@0+ (1,0) [0|255] "raw"  FMUX,EMF
 SG_ FlowPadding4 m3 : 55|8@0+ (1,0) [0|255] "raw"  FMUX,EMF
 SG_ FirstData5 m1 : 55|8@0+ (1,0) [0|255] "raw"  FMUX,EMF
 SG_ UnknownData6 m4 : 55|8@0+ (1,0) [0|255] "raw"  FMUX,EMF
 SG_ ConsecutiveData6 m2 : 55|8@0+ (1,0) [0|255] "raw"  FMUX,EMF
 SG_ SingleData6 m0 : 55|8@0+ (1,0) [0|255] "raw"  FMUX,EMF
 SG_ FlowPadding3 m3 : 47|8@0+ (1,0) [0|255] "raw"  FMUX,EMF
 SG_ FirstData4 m1 : 47|8@0+ (1,0) [0|255] "raw"  FMUX,EMF
 SG_ UnknownData5 m4 : 47|8@0+ (1,0) [0|255] "raw"  FMUX,EMF
 SG_ ConsecutiveData5 m2 : 47|8@0+ (1,0) [0|255] "raw"  FMUX,EMF
 SG_ SingleData5 m0 : 47|8@0+ (1,0) [0|255] "raw"  FMUX,EMF
 SG_ FlowPadding2 m3 : 39|8@0+ (1,0) [0|255] "raw"  FMUX,EMF
 SG_ FirstData3 m1 : 39|8@0+ (1,0) [0|255] "raw"  FMUX,EMF
 SG_ UnknownData4 m4 : 39|8@0+ (1,0) [0|255] "raw"  FMUX,EMF
 SG_ ConsecutiveData4 m2 : 39|8@0+ (1,0) [0|255] "raw"  FMUX,EMF
 SG_ SingleData4 m0 : 39|8@0+ (1,0) [0|255] "raw"  FMUX,EMF
 SG_ FlowPadding1 m3 : 31|8@0+ (1,0) [0|255] "raw"  FMUX,EMF
 SG_ FirstData2 m1 : 31|8@0+ (1,0) [0|255] "raw"  FMUX,EMF
 SG_ UnknownData3 m4 : 31|8@0+ (1,0) [0|255] "raw"  FMUX,EMF
 SG_ ConsecutiveData3 m2 : 31|8@0+ (1,0) [0|255] "raw"  FMUX,EMF
 SG_ SingleData3 m0 : 31|8@0+ (1,0) [0|255] "raw"  FMUX,EMF
 SG_ FirstData1 m1 : 23|8@0+ (1,0) [0|255] "raw"  FMUX,EMF
 SG_ UnknownData2 m4 : 23|8@0+ (1,0) [0|255] "raw"  FMUX,EMF
 SG_ ConsecutiveData2 m2 : 23|8@0+ (1,0) [0|255] "raw"  FMUX,EMF
 SG_ SingleData2 m0 : 23|8@0+ (1,0) [0|255] "raw"  FMUX,EMF
 SG_ SeparationTimeRaw m3 : 23|8@0+ (1,0) [0|255] "raw"  FMUX,EMF
 SG_ UnknownData1 m4 : 15|8@0+ (1,0) [0|255] "raw"  FMUX,EMF
 SG_ ConsecutiveData1 m2 : 15|8@0+ (1,0) [0|255] "raw"  FMUX,EMF
 SG_ SingleData1 m0 : 15|8@0+ (1,0) [0|255] "raw"  FMUX,EMF
 SG_ BlockSize m3 : 15|8@0+ (1,0) [0|255] "raw"  FMUX,EMF
 SG_ UnknownPciLow m4 : 3|4@0+ (1,0) [0|15] "raw"  FMUX,EMF
 SG_ FlowStatus m3 : 3|4@0+ (1,0) [0|15] "raw"  FMUX,EMF
 SG_ ConsecutiveSequence m2 : 3|4@0+ (1,0) [0|15] "raw"  FMUX,EMF
 SG_ FirstFrameLength m1 : 3|12@0+ (1,0) [0|4095] "raw"  FMUX,EMF
 SG_ SingleFrameLength m0 : 3|4@0+ (1,0) [0|15] "raw"  FMUX,EMF
 SG_ IsoTpFrameType M : 7|4@0+ (1,0) [0|15] ""  FMUX,EMF

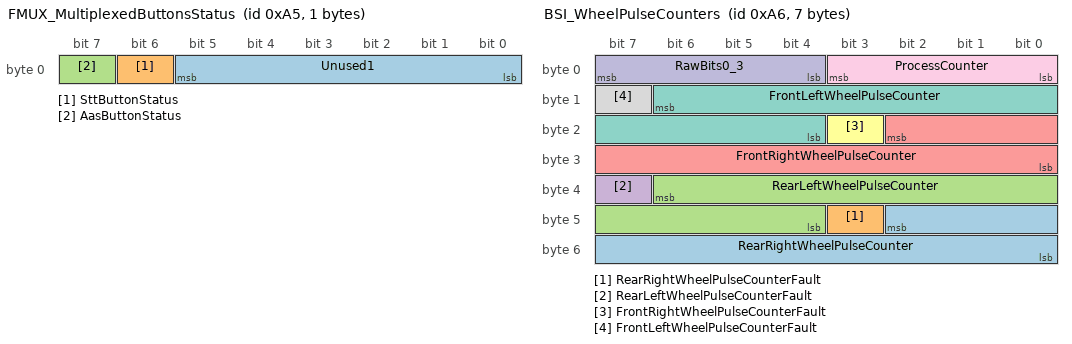
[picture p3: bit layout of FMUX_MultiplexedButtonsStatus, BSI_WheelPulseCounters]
BO_ 165 FMUX_MultiplexedButtonsStatus: 1 FMUX
 SG_ Unused1 : 5|6@0+ (1,0) [0|63] ""  BSI
 SG_ SttButtonStatus : 6|1@0+ (1,0) [0|1] ""  BSI
 SG_ AasButtonStatus : 7|1@0+ (1,0) [0|1] ""  BSI

BO_ 166 BSI_WheelPulseCounters: 7 BSI
 SG_ RearRightWheelPulseCounter : 42|11@0+ (1,0) [0|2047] ""  BTEL
 SG_ RearRightWheelPulseCounterFault : 43|1@0+ (1,0) [0|1] ""  BTEL
 SG_ RearLeftWheelPulseCounter : 38|11@0+ (1,0) [0|2047] ""  BTEL
 SG_ RearLeftWheelPulseCounterFault : 39|1@0+ (1,0) [0|1] ""  BTEL
 SG_ FrontRightWheelPulseCounter : 18|11@0+ (1,0) [0|2047] ""  BTEL
 SG_ FrontRightWheelPulseCounterFault : 19|1@0+ (1,0) [0|1] ""  BTEL
 SG_ FrontLeftWheelPulseCounter : 14|11@0+ (1,0) [0|2047] ""  BTEL
 SG_ FrontLeftWheelPulseCounterFault : 15|1@0+ (1,0) [0|1] ""  BTEL
 SG_ ProcessCounter : 3|4@0+ (1,0) [0|15] ""  BTEL
 SG_ RawBits0_3 : 7|4@0+ (1,0) [0|15] "raw" Vector__XXX

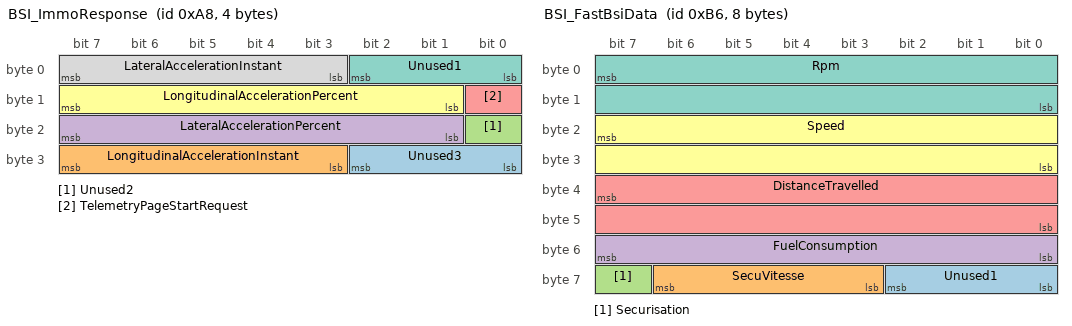
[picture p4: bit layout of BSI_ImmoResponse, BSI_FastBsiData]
BO_ 168 BSI_ImmoResponse: 4 BSI
 SG_ Unused3 : 26|3@0+ (1,0) [0|7] ""  CMB,MATT
 SG_ LongitudinalAccelerationInstant : 31|5@0+ (0.1,0) [0|2] "g"  CMB,MATT
 SG_ Unused2 : 16|1@0+ (1,0) [0|1] ""  CMB,MATT
 SG_ LateralAccelerationPercent : 23|7@0+ (1,0) [0|100] "%"  CMB,MATT
 SG_ TelemetryPageStartRequest : 8|1@0+ (1,0) [0|1] ""  CMB,MATT
 SG_ LongitudinalAccelerationPercent : 15|7@0+ (1,0) [0|100] "%"  CMB,MATT
 SG_ Unused1 : 2|3@0+ (1,0) [0|7] ""  CMB,MATT
 SG_ LateralAccelerationInstant : 7|5@0+ (0.1,0) [0|2] "g"  CMB,MATT

BO_ 169 BTEL_ImmobilizerSeedGearboxBsi: 8 BTEL
 SG_ FlowPadding5 m3 : 63|8@0+ (1,0) [0|255] "raw"  ICSV,CMB
 SG_ FirstData6 m1 : 63|8@0+ (1,0) [0|255] "raw"  ICSV,CMB
 SG_ UnknownData7 m4 : 63|8@0+ (1,0) [0|255] "raw"  ICSV,CMB
 SG_ ConsecutiveData7 m2 : 63|8@0+ (1,0) [0|255] "raw"  ICSV,CMB
 SG_ SingleData7 m0 : 63|8@0+ (1,0) [0|255] "raw"  ICSV,CMB
 SG_ FlowPadding4 m3 : 55|8@0+ (1,0) [0|255] "raw"  ICSV,CMB
 SG_ FirstData5 m1 : 55|8@0+ (1,0) [0|255] "raw"  ICSV,CMB
 SG_ UnknownData6 m4 : 55|8@0+ (1,0) [0|255] "raw"  ICSV,CMB
 SG_ ConsecutiveData6 m2 : 55|8@0+ (1,0) [0|255] "raw"  ICSV,CMB
 SG_ SingleData6 m0 : 55|8@0+ (1,0) [0|255] "raw"  ICSV,CMB
 SG_ FlowPadding3 m3 : 47|8@0+ (1,0) [0|255] "raw"  ICSV,CMB
 SG_ FirstData4 m1 : 47|8@0+ (1,0) [0|255] "raw"  ICSV,CMB
 SG_ UnknownData5 m4 : 47|8@0+ (1,0) [0|255] "raw"  ICSV,CMB
 SG_ ConsecutiveData5 m2 : 47|8@0+ (1,0) [0|255] "raw"  ICSV,CMB
 SG_ SingleData5 m0 : 47|8@0+ (1,0) [0|255] "raw"  ICSV,CMB
 SG_ FlowPadding2 m3 : 39|8@0+ (1,0) [0|255] "raw"  ICSV,CMB
 SG_ FirstData3 m1 : 39|8@0+ (1,0) [0|255] "raw"  ICSV,CMB
 SG_ UnknownData4 m4 : 39|8@0+ (1,0) [0|255] "raw"  ICSV,CMB
 SG_ ConsecutiveData4 m2 : 39|8@0+ (1,0) [0|255] "raw"  ICSV,CMB
 SG_ SingleData4 m0 : 39|8@0+ (1,0) [0|255] "raw"  ICSV,CMB
 SG_ FlowPadding1 m3 : 31|8@0+ (1,0) [0|255] "raw"  ICSV,CMB
 SG_ FirstData2 m1 : 31|8@0+ (1,0) [0|255] "raw"  ICSV,CMB
 SG_ UnknownData3 m4 : 31|8@0+ (1,0) [0|255] "raw"  ICSV,CMB
 SG_ ConsecutiveData3 m2 : 31|8@0+ (1,0) [0|255] "raw"  ICSV,CMB
 SG_ SingleData3 m0 : 31|8@0+ (1,0) [0|255] "raw"  ICSV,CMB
 SG_ FirstData1 m1 : 23|8@0+ (1,0) [0|255] "raw"  ICSV,CMB
 SG_ UnknownData2 m4 : 23|8@0+ (1,0) [0|255] "raw"  ICSV,CMB
 SG_ ConsecutiveData2 m2 : 23|8@0+ (1,0) [0|255] "raw"  ICSV,CMB
 SG_ SingleData2 m0 : 23|8@0+ (1,0) [0|255] "raw"  ICSV,CMB
 SG_ SeparationTimeRaw m3 : 23|8@0+ (1,0) [0|255] "raw"  ICSV,CMB
 SG_ UnknownData1 m4 : 15|8@0+ (1,0) [0|255] "raw"  ICSV,CMB
 SG_ ConsecutiveData1 m2 : 15|8@0+ (1,0) [0|255] "raw"  ICSV,CMB
 SG_ SingleData1 m0 : 15|8@0+ (1,0) [0|255] "raw"  ICSV,CMB
 SG_ BlockSize m3 : 15|8@0+ (1,0) [0|255] "raw"  ICSV,CMB
 SG_ UnknownPciLow m4 : 3|4@0+ (1,0) [0|15] "raw"  ICSV,CMB
 SG_ FlowStatus m3 : 3|4@0+ (1,0) [0|15] "raw"  ICSV,CMB
 SG_ ConsecutiveSequence m2 : 3|4@0+ (1,0) [0|15] "raw"  ICSV,CMB
 SG_ FirstFrameLength m1 : 3|12@0+ (1,0) [0|4095] "raw"  ICSV,CMB
 SG_ SingleFrameLength m0 : 3|4@0+ (1,0) [0|15] "raw"  ICSV,CMB
 SG_ IsoTpFrameType M : 7|4@0+ (1,0) [0|15] ""  ICSV,CMB

BO_ 182 BSI_FastBsiData: 8 BSI
 SG_ Unused1 : 58|3@0+ (1,0) [0|7] ""  BTEL,EMF,RAD,CMB,VTH,AAS,AMPLI,MDS,MATT,AVP,OVIP,IDVR,FMUX
 SG_ SecuVitesse : 62|4@0+ (1,0) [0|15] ""  BTEL,EMF,RAD,CMB,VTH,AAS,AMPLI,MDS,MATT,AVP,OVIP,IDVR,FMUX
 SG_ Securisation : 63|1@0+ (1,0) [0|1] ""  BTEL,EMF,RAD,CMB,VTH,AAS,AMPLI,MDS,MATT,AVP,OVIP,IDVR,FMUX
 SG_ FuelConsumption : 55|8@0+ (80,0) [0|20400] "mm3"  BTEL,EMF,RAD,CMB,VTH,AAS,AMPLI,MDS,MATT,AVP,OVIP,IDVR,FMUX
 SG_ DistanceTravelled : 39|16@0+ (0.1,0) [0|6553.5] "m"  BTEL,EMF,RAD,CMB,VTH,AAS,AMPLI,MDS,MATT,AVP,OVIP,IDVR,FMUX
 SG_ Speed : 23|16@0+ (0.01,0) [0|655.34] "km/h"  BTEL,EMF,RAD,CMB,VTH,AAS,AMPLI,MDS,MATT,AVP,OVIP,IDVR,FMUX
 SG_ Rpm : 7|16@0+ (0.125,0) [0|8191.75] "rpm"  BTEL,EMF,RAD,CMB,VTH,AAS,AMPLI,MDS,MATT,AVP,OVIP,IDVR,FMUX

BO_ 189 SDCM_Status: 5 SDCM
 SG_ RawByte5 : 39|8@0+ (1,0) [0|255] "raw" Vector__XXX
 SG_ Unused1 : 25|2@0+ (1,0) [0|3] ""  BSI
 SG_ SmartDevice5Enabled : 26|1@0+ (1,0) [0|1] ""  BSI
 SG_ SmartDevice4Enabled : 27|1@0+ (1,0) [0|1] ""  BSI
 SG_ SmartDevice3Enabled : 28|1@0+ (1,0) [0|1] ""  BSI
 SG_ SmartDevice2Enabled : 29|1@0+ (1,0) [0|1] ""  BSI
 SG_ SmartDevice1Enabled : 30|1@0+ (1,0) [0|1] ""  BSI
 SG_ SmartDevice5Zone : 17|3@0+ (1,0) [0|7] ""  BSI
 SG_ SmartDevice4Zone : 20|3@0+ (1,0) [0|7] ""  BSI
 SG_ SmartDevice3Zone : 23|3@0+ (1,0) [0|7] ""  BSI
 SG_ SmartDevice2Zone : 10|3@0+ (1,0) [0|7] ""  BSI
 SG_ SmartDevice1Zone : 13|3@0+ (1,0) [0|7] ""  BSI
 SG_ HfaPollingStatus : 14|1@0+ (1,0) [0|1] ""  BSI
 SG_ HfaFeatureStatus : 15|1@0+ (1,0) [0|1] ""  BSI
 SG_ SmartDeviceFeatureStatus : 0|1@0+ (1,0) [0|1] ""  BSI
 SG_ SdcmAuthorizationStatus : 1|1@0+ (1,0) [0|1] ""  BSI
 SG_ WalUirFeatureStatus : 2|1@0+ (1,0) [0|1] ""  BSI
 SG_ CidLowEnergyAlert : 3|1@0+ (1,0) [0|1] ""  BSI
 SG_ HfaPollingType : 7|4@0+ (1,0) [0|15] ""  BSI

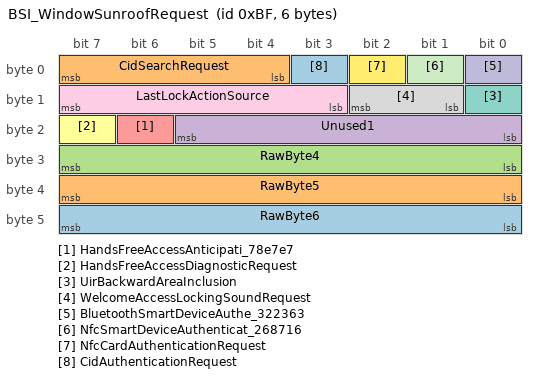
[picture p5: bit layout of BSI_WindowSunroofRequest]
BO_ 191 BSI_WindowSunroofRequest: 6 BSI
 SG_ RawByte6 : 47|8@0+ (1,0) [0|255] "raw" Vector__XXX
 SG_ RawByte5 : 39|8@0+ (1,0) [0|255] "raw" Vector__XXX
 SG_ RawByte4 : 31|8@0+ (1,0) [0|255] "raw" Vector__XXX
 SG_ Unused1 : 21|6@0+ (1,0) [0|63] ""  SDCM
 SG_ HandsFreeAccessAnticipati_78e7e7 : 22|1@0+ (1,0) [0|1] ""  SDCM
 SG_ HandsFreeAccessDiagnosticRequest : 23|1@0+ (1,0) [0|1] ""  SDCM
 SG_ UirBackwardAreaInclusion : 8|1@0+ (1,0) [0|1] ""  SDCM
 SG_ WelcomeAccessLockingSoundRequest : 10|2@0+ (1,0) [0|3] ""  SDCM
 SG_ LastLockActionSource : 15|5@0+ (1,0) [0|31] ""  SDCM
 SG_ BluetoothSmartDeviceAuthe_322363 : 0|1@0+ (1,0) [0|1] ""  SDCM
 SG_ NfcSmartDeviceAuthenticat_268716 : 1|1@0+ (1,0) [0|1] ""  SDCM
 SG_ NfcCardAuthenticationRequest : 2|1@0+ (1,0) [0|1] ""  SDCM
 SG_ CidAuthenticationRequest : 3|1@0+ (1,0) [0|1] ""  SDCM
 SG_ CidSearchRequest : 7|4@0+ (1,0) [0|15] ""  SDCM

BO_ 193 SDCM_ApduTransmit: 8 SDCM
 SG_ FlowPadding5 m3 : 63|8@0+ (1,0) [0|255] "raw"  WLC
 SG_ FirstData6 m1 : 63|8@0+ (1,0) [0|255] "raw"  WLC
 SG_ UnknownData7 m4 : 63|8@0+ (1,0) [0|255] "raw"  WLC
 SG_ ConsecutiveData7 m2 : 63|8@0+ (1,0) [0|255] "raw"  WLC
 SG_ SingleData7 m0 : 63|8@0+ (1,0) [0|255] "raw"  WLC
 SG_ FlowPadding4 m3 : 55|8@0+ (1,0) [0|255] "raw"  WLC
 SG_ FirstData5 m1 : 55|8@0+ (1,0) [0|255] "raw"  WLC
 SG_ UnknownData6 m4 : 55|8@0+ (1,0) [0|255] "raw"  WLC
 SG_ ConsecutiveData6 m2 : 55|8@0+ (1,0) [0|255] "raw"  WLC
 SG_ SingleData6 m0 : 55|8@0+ (1,0) [0|255] "raw"  WLC
 SG_ FlowPadding3 m3 : 47|8@0+ (1,0) [0|255] "raw"  WLC
 SG_ FirstData4 m1 : 47|8@0+ (1,0) [0|255] "raw"  WLC
 SG_ UnknownData5 m4 : 47|8@0+ (1,0) [0|255] "raw"  WLC
 SG_ ConsecutiveData5 m2 : 47|8@0+ (1,0) [0|255] "raw"  WLC
 SG_ SingleData5 m0 : 47|8@0+ (1,0) [0|255] "raw"  WLC
 SG_ FlowPadding2 m3 : 39|8@0+ (1,0) [0|255] "raw"  WLC
 SG_ FirstData3 m1 : 39|8@0+ (1,0) [0|255] "raw"  WLC
 SG_ UnknownData4 m4 : 39|8@0+ (1,0) [0|255] "raw"  WLC
 SG_ ConsecutiveData4 m2 : 39|8@0+ (1,0) [0|255] "raw"  WLC
 SG_ SingleData4 m0 : 39|8@0+ (1,0) [0|255] "raw"  WLC
 SG_ FlowPadding1 m3 : 31|8@0+ (1,0) [0|255] "raw"  WLC
 SG_ FirstData2 m1 : 31|8@0+ (1,0) [0|255] "raw"  WLC
 SG_ UnknownData3 m4 : 31|8@0+ (1,0) [0|255] "raw"  WLC
 SG_ ConsecutiveData3 m2 : 31|8@0+ (1,0) [0|255] "raw"  WLC
 SG_ SingleData3 m0 : 31|8@0+ (1,0) [0|255] "raw"  WLC
 SG_ FirstData1 m1 : 23|8@0+ (1,0) [0|255] "raw"  WLC
 SG_ UnknownData2 m4 : 23|8@0+ (1,0) [0|255] "raw"  WLC
 SG_ ConsecutiveData2 m2 : 23|8@0+ (1,0) [0|255] "raw"  WLC
 SG_ SingleData2 m0 : 23|8@0+ (1,0) [0|255] "raw"  WLC
 SG_ SeparationTimeRaw m3 : 23|8@0+ (1,0) [0|255] "raw"  WLC
 SG_ UnknownData1 m4 : 15|8@0+ (1,0) [0|255] "raw"  WLC
 SG_ ConsecutiveData1 m2 : 15|8@0+ (1,0) [0|255] "raw"  WLC
 SG_ SingleData1 m0 : 15|8@0+ (1,0) [0|255] "raw"  WLC
 SG_ BlockSize m3 : 15|8@0+ (1,0) [0|255] "raw"  WLC
 SG_ UnknownPciLow m4 : 3|4@0+ (1,0) [0|15] "raw"  WLC
 SG_ FlowStatus m3 : 3|4@0+ (1,0) [0|15] "raw"  WLC
 SG_ ConsecutiveSequence m2 : 3|4@0+ (1,0) [0|15] "raw"  WLC
 SG_ FirstFrameLength m1 : 3|12@0+ (1,0) [0|4095] "raw"  WLC
 SG_ SingleFrameLength m0 : 3|4@0+ (1,0) [0|15] "raw"  WLC
 SG_ IsoTpFrameType M : 7|4@0+ (1,0) [0|15] ""  WLC

BO_TX_BU_ 0 : ICSV,BSI;
BO_TX_BU_ 24 : BSI,ICSV;
BO_TX_BU_ 28 : ICSV,BTEL,MATT,EMF,OVIP,CMB;
BO_TX_BU_ 105 : RAD,BTEL,OVIP,EMF;
BO_TX_BU_ 159 : EMF,ICSV;
BO_TX_BU_ 162 : BSI,ICSV;
BO_TX_BU_ 164 : RAD,ICSV;
BO_TX_BU_ 169 : BTEL,OVIP;
BO_TX_BU_ 182 : BSI,ICSV;

CM_ BU_ AAS "PSA-RE alias; physical transmitter identity unverified.";
CM_ BU_ AMPLI "PSA-RE alias; physical transmitter identity unverified.";
CM_ BU_ AVP "PSA-RE alias; physical transmitter identity unverified.";
CM_ BU_ BCM "PSA-RE alias; physical transmitter identity unverified.";
CM_ BU_ BGP "PSA-RE alias; physical transmitter identity unverified.";
CM_ BU_ BSG "PSA-RE alias; physical transmitter identity unverified.";
CM_ BU_ BSI "PSA-RE alias; physical transmitter identity unverified.";
CM_ BU_ BTA "PSA-RE alias; physical transmitter identity unverified.";
CM_ BU_ BTEL "PSA-RE alias; physical transmitter identity unverified.";
CM_ BU_ BTT "PSA-RE alias; physical transmitter identity unverified.";
CM_ BU_ CDC "PSA-RE alias; physical transmitter identity unverified.";
CM_ BU_ CMB "PSA-RE alias; physical transmitter identity unverified.";
CM_ BU_ CRT "PSA-RE alias; physical transmitter identity unverified.";
CM_ BU_ DIAG_TOOL "PSA-RE alias; physical transmitter identity unverified.";
CM_ BU_ EDP_C "PSA-RE alias; physical transmitter identity unverified.";
CM_ BU_ EMF "PSA-RE alias; physical transmitter identity unverified.";
CM_ BU_ FMUX "PSA-RE alias; physical transmitter identity unverified.";
CM_ BU_ IC "Vehicle unit004 instrument cluster; see per-message capture attribution.";
CM_ BU_ ICSV "PSA-RE alias; physical transmitter identity unverified.";
CM_ BU_ IDVR "PSA-RE alias; physical transmitter identity unverified.";
CM_ BU_ IVC_D "PSA-RE alias; physical transmitter identity unverified.";
CM_ BU_ MATT "PSA-RE alias; physical transmitter identity unverified.";
CM_ BU_ MDS "PSA-RE alias; physical transmitter identity unverified.";
CM_ BU_ OVIP "PSA-RE alias; physical transmitter identity unverified.";
CM_ BU_ PDS_C "PSA-RE alias; physical transmitter identity unverified.";
CM_ BU_ RAD "PSA-RE alias; physical transmitter identity unverified.";
CM_ BU_ RBG "PSA-RE alias; physical transmitter identity unverified.";
CM_ BU_ SDCM "PSA-RE alias; physical transmitter identity unverified.";
CM_ BU_ VTH "PSA-RE alias; physical transmitter identity unverified.";
CM_ BU_ WLC "PSA-RE alias; physical transmitter identity unverified.";
CM_ BO_ 0 "DATABASE_CANDIDATE: physical interpretation unverified; capture/layout evidence reported separately. INFO-DIV CAN, 125000 bit/s; CAN ID 0x000. PSA-RE title: SEAT_CLIMATE_MODULE_STATUS_REAR_RIGHT. Brake unit status relayed by the body computer: brake fluid alert, hill-hold request, wheel pulse counters and start&stop brake demand. Source: https://github.com/prototux/PSA-RE/blob/67f7581e7622410efdbb29c7eda3b86982b9b450/buses/AEE2010.ev/LS.INFO-DIV/000.yml. Source sender alternatives: ICSV,BSI; physical TX/gateway forwarding not verified. Unresolved alternative source layouts preserved in source JSON. ";
CM_ SG_ 0 RawByte8 "RAW. PSA-RE bits 8.7-8.0. Unmapped/padding bits, no physical interpretation.";
CM_ SG_ 0 EspDisconnectRequest "DATABASE_CANDIDATE: physical interpretation unverified; capture/layout evidence reported separately. PSA-RE bits 7.0. ESP disconnection status requested by a diagnostic tool";
CM_ SG_ 0 BrakeAssistFaultLampRequest "DATABASE_CANDIDATE: physical interpretation unverified; capture/layout evidence reported separately. PSA-RE bits 7.1. Brake assist fault warning lamp activation request";
CM_ SG_ 0 StaticSlopeState "DATABASE_CANDIDATE: physical interpretation unverified; capture/layout evidence reported separately. PSA-RE bits 7.3-7.2. Static road slope state (uphill/downhill)";
CM_ SG_ 0 BrakeFunctionNeedForStartStop "DATABASE_CANDIDATE: physical interpretation unverified; capture/layout evidence reported separately. PSA-RE bits 7.5-7.4. Brake function requirement for the stop-start (STT) system";
CM_ SG_ 0 BrakeEcuPowerManagementFault "DATABASE_CANDIDATE: physical interpretation unverified; capture/layout evidence reported separately. PSA-RE bits 7.6. Electrical power management fault detected by the brake ECU";
CM_ SG_ 0 EmergencyBrakingSignaliza_517ee3 "DATABASE_CANDIDATE: physical interpretation unverified; capture/layout evidence reported separately. PSA-RE bits 7.7. Indicates whether the emergency braking signal function is implemented in the brake ECU";
CM_ SG_ 0 BatteryVoltageUcBrake "DATABASE_CANDIDATE: physical interpretation unverified; capture/layout evidence reported separately. PSA-RE bits 6.7-6.0. Battery voltage measured by the brake ECU Raw invalid=255; numeric DBC decoders may still scale it: check raw before use.";
CM_ SG_ 0 RearRightWheelSpinCounter "DATABASE_CANDIDATE: physical interpretation unverified; capture/layout evidence reported separately. PSA-RE bits 4.6-5.0. Free-running rear right wheel speed sensor pulse counter";
CM_ SG_ 0 RearRightWheelSpeedSensorFault "DATABASE_CANDIDATE: physical interpretation unverified; capture/layout evidence reported separately. PSA-RE bits 4.7. Rear right wheel-speed pulse counter malfunction";
CM_ SG_ 0 RearLeftWheelSpinCounter "DATABASE_CANDIDATE: physical interpretation unverified; capture/layout evidence reported separately. PSA-RE bits 2.6-3.0. Free-running rear left wheel speed sensor pulse counter";
CM_ SG_ 0 RearLeftWheelSpeedSensorFault "DATABASE_CANDIDATE: physical interpretation unverified; capture/layout evidence reported separately. PSA-RE bits 2.7. Rear left wheel-speed pulse counter malfunction";
CM_ SG_ 0 AbsFaultLampRequest "DATABASE_CANDIDATE: physical interpretation unverified; capture/layout evidence reported separately. PSA-RE bits 1.0. ABS fault warning lamp activation request";
CM_ SG_ 0 BrakeFluidLevelAlert "DATABASE_CANDIDATE: physical interpretation unverified; capture/layout evidence reported separately. PSA-RE bits 1.1. Brake fluid level alert";
CM_ SG_ 0 WornBrakePadsIndicator "DATABASE_CANDIDATE: physical interpretation unverified; capture/layout evidence reported separately. PSA-RE bits 1.2. Brake pad wear indicator";
CM_ SG_ 0 RefInProgress "DATABASE_CANDIDATE: physical interpretation unverified; capture/layout evidence reported separately. PSA-RE bits 1.3. Electronic brake force distribution (REF) regulation in progress";
CM_ SG_ 0 AutomaticHazardLightsByUcBrake "DATABASE_CANDIDATE: physical interpretation unverified; capture/layout evidence reported separately. PSA-RE bits 1.4. Indicates whether the automatic hazard warning lights function is implemented in the brake ECU";
CM_ SG_ 0 AbsInProgress "DATABASE_CANDIDATE: physical interpretation unverified; capture/layout evidence reported separately. PSA-RE bits 1.5. ABS regulation in progress";
CM_ SG_ 0 RawBits1_1 "RAW. PSA-RE bits 1.6-1.6. Unmapped/padding bits, no physical interpretation.";
CM_ SG_ 0 RefFaultLamp "DATABASE_CANDIDATE: physical interpretation unverified; capture/layout evidence reported separately. PSA-RE bits 1.7. Electronic brake force distribution (REF) fault warning lamp activation request";
CM_ BO_ 1 "DATABASE_CANDIDATE: physical interpretation unverified; capture/layout evidence reported separately. INFO-DIV CAN, 125000 bit/s; CAN ID 0x001. PSA-RE title: BSI_RAPID_COMMAND. Request to learn the identifier table sent to the BSI Source: https://github.com/prototux/PSA-RE/blob/67f7581e7622410efdbb29c7eda3b86982b9b450/buses/AEE2010.full/LS.INFO-DIV/001.yml. Source sender alternatives: BSI; physical TX/gateway forwarding not verified. ";
CM_ SG_ 1 Unused1 "DATABASE_CANDIDATE: physical interpretation unverified; capture/layout evidence reported separately. PSA-RE bits 1.6-1.0. ";
CM_ SG_ 1 UidTableLearnRequestToBsi "DATABASE_CANDIDATE: physical interpretation unverified; capture/layout evidence reported separately. PSA-RE bits 1.7. Encrypted request to learn the UID table, sent to the BSI";
CM_ BO_ 2 "DATABASE_CANDIDATE: physical interpretation unverified; capture/layout evidence reported separately. INFO-DIV CAN, 125000 bit/s; CAN ID 0x002. PSA-RE title: ADDITIVE_PUMP_STATUS. Preconditioning (cabin climate scheduling) profile information, defined by the profile message structure. Source: https://github.com/prototux/PSA-RE/blob/67f7581e7622410efdbb29c7eda3b86982b9b450/buses/AEE2010.full/LS.INFO-DIV/002.yml. Source sender alternatives: BSI; physical TX/gateway forwarding not verified. ";
CM_ SG_ 2 AcPrecondSchedule2StartTime "DATABASE_CANDIDATE: physical interpretation unverified; capture/layout evidence reported separately. PSA-RE bits 6.2-7.0. Memorized start time of climate preconditioning schedule 2, in minutes since midnight";
CM_ SG_ 2 RawBits40_44 "RAW. PSA-RE bits 6.7-6.3. Unmapped/padding bits, no physical interpretation.";
CM_ SG_ 2 AcPrecondSundaySchedule2Active "DATABASE_CANDIDATE: physical interpretation unverified; capture/layout evidence reported separately. PSA-RE bits 5.0. Memorized activation status of climate preconditioning schedule 2 for Sunday";
CM_ SG_ 2 AcPrecondSaturdaySchedule2Active "DATABASE_CANDIDATE: physical interpretation unverified; capture/layout evidence reported separately. PSA-RE bits 5.1. Memorized activation status of climate preconditioning schedule 2 for Saturday";
CM_ SG_ 2 AcPrecondFridaySchedule2Active "DATABASE_CANDIDATE: physical interpretation unverified; capture/layout evidence reported separately. PSA-RE bits 5.2. Memorized activation status of climate preconditioning schedule 2 for Friday";
CM_ SG_ 2 AcPrecondThursdaySchedule2Active "DATABASE_CANDIDATE: physical interpretation unverified; capture/layout evidence reported separately. PSA-RE bits 5.3. Memorized activation status of climate preconditioning schedule 2 for Thursday";
CM_ SG_ 2 AcPrecondWednesdaySchedul_14303b "DATABASE_CANDIDATE: physical interpretation unverified; capture/layout evidence reported separately. PSA-RE bits 5.4. Memorized activation status of climate preconditioning schedule 2 for Wednesday";
CM_ SG_ 2 AcPrecondTuesdaySchedule2Active "DATABASE_CANDIDATE: physical interpretation unverified; capture/layout evidence reported separately. PSA-RE bits 5.5. Memorized activation status of climate preconditioning schedule 2 for Tuesday";
CM_ SG_ 2 AcPrecondMondaySchedule2Active "DATABASE_CANDIDATE: physical interpretation unverified; capture/layout evidence reported separately. PSA-RE bits 5.6. Memorized activation status of climate preconditioning schedule 2 for Monday";
CM_ SG_ 2 AcPrecondSchedule2Enabled "DATABASE_CANDIDATE: physical interpretation unverified; capture/layout evidence reported separately. PSA-RE bits 5.7. Memorized global activation status of climate preconditioning schedule 2";
CM_ SG_ 2 AcPrecondSchedule1StartTime "DATABASE_CANDIDATE: physical interpretation unverified; capture/layout evidence reported separately. PSA-RE bits 3.2-4.0. Memorized start time of climate preconditioning schedule 1, in minutes since midnight";
CM_ SG_ 2 RawBits16_20 "RAW. PSA-RE bits 3.7-3.3. Unmapped/padding bits, no physical interpretation.";
CM_ SG_ 2 AcPrecondSundaySchedule1Active "DATABASE_CANDIDATE: physical interpretation unverified; capture/layout evidence reported separately. PSA-RE bits 2.0. Memorized activation status of climate preconditioning schedule 1 for Sunday";
CM_ SG_ 2 AcPrecondSaturdaySchedule1Active "DATABASE_CANDIDATE: physical interpretation unverified; capture/layout evidence reported separately. PSA-RE bits 2.1. Memorized activation status of climate preconditioning schedule 1 for Saturday";
CM_ SG_ 2 AcPrecondFridaySchedule1Active "DATABASE_CANDIDATE: physical interpretation unverified; capture/layout evidence reported separately. PSA-RE bits 2.2. Memorized activation status of climate preconditioning schedule 1 for Friday";
CM_ SG_ 2 AcPrecondThursdaySchedule1Active "DATABASE_CANDIDATE: physical interpretation unverified; capture/layout evidence reported separately. PSA-RE bits 2.3. Memorized activation status of climate preconditioning schedule 1 for Thursday";
CM_ SG_ 2 AcPrecondWednesdaySchedul_0079d6 "DATABASE_CANDIDATE: physical interpretation unverified; capture/layout evidence reported separately. PSA-RE bits 2.4. Memorized activation status of climate preconditioning schedule 1 for Wednesday";
CM_ SG_ 2 AcPrecondTuesdaySchedule1Active "DATABASE_CANDIDATE: physical interpretation unverified; capture/layout evidence reported separately. PSA-RE bits 2.5. Memorized activation status of climate preconditioning schedule 1 for Tuesday";
CM_ SG_ 2 AcPrecondMondaySchedule1Active "DATABASE_CANDIDATE: physical interpretation unverified; capture/layout evidence reported separately. PSA-RE bits 2.6. Memorized activation status of climate preconditioning schedule 1 for Monday";
CM_ SG_ 2 AcPrecondSchedule1Enabled "DATABASE_CANDIDATE: physical interpretation unverified; capture/layout evidence reported separately. PSA-RE bits 2.7. Memorized global activation status of climate preconditioning schedule 1";
CM_ SG_ 2 RawBits6_7 "RAW. PSA-RE bits 1.1-1.0. Unmapped/padding bits, no physical interpretation.";
CM_ SG_ 2 AcPrecondAsapModeActive "DATABASE_CANDIDATE: physical interpretation unverified; capture/layout evidence reported separately. PSA-RE bits 1.2. Memorized activation status of the \"as soon as possible\" climate preconditioning mode";
CM_ SG_ 2 AcPrecondStatusFeedback "DATABASE_CANDIDATE: physical interpretation unverified; capture/layout evidence reported separately. PSA-RE bits 1.6-1.3. Status feedback of the climate preconditioning function";
CM_ SG_ 2 AcPrecondStatusAvailability "DATABASE_CANDIDATE: physical interpretation unverified; capture/layout evidence reported separately. PSA-RE bits 1.7. Availability of the climate preconditioning schedule status information";
CM_ BO_ 24 "DATABASE_CANDIDATE: physical interpretation unverified; capture/layout evidence reported separately. INFO-DIV CAN, 125000 bit/s; CAN ID 0x018. PSA-RE title: AIR_INTAKE_MOTOR_COMMAND_3. Airbag system status: passenger airbag inhibition, rollover and rear impact detection, fired pyrotechnic igniters and crash detected flag. Also used by the body computer as the presence-monitoring frame for the airbag ECU. Source: https://github.com/prototux/PSA-RE/blob/67f7581e7622410efdbb29c7eda3b86982b9b450/buses/AEE2010.full/LS.INFO-DIV/018.yml. Source sender alternatives: BSI,ICSV; physical TX/gateway forwarding not verified. Observed 2936 frames in info_apka.csv,info_buzeni_obc.csv,info_charging.csv,info_standby.csv,info_start_jizda.csv,infocan.csv; DLCs [5]. ";
CM_ SG_ 24 Unused4 "DATABASE_CANDIDATE: physical interpretation unverified; capture/layout evidence reported separately. PSA-RE bits 5.7-5.0. ";
CM_ SG_ 24 Unused3 "DATABASE_CANDIDATE: physical interpretation unverified; capture/layout evidence reported separately. PSA-RE bits 4.6-4.0. ";
CM_ SG_ 24 Unused2 "DATABASE_CANDIDATE: physical interpretation unverified; capture/layout evidence reported separately. PSA-RE bits 4.7. ";
CM_ SG_ 24 PedestrianCrashInfo "DATABASE_CANDIDATE: physical interpretation unverified; capture/layout evidence reported separately. PSA-RE bits 3.0. Pedestrian impact info Upstream default raw=0 (not necessarily valid data).";
CM_ SG_ 24 AutomaticEcallTrigger "DATABASE_CANDIDATE: physical interpretation unverified; capture/layout evidence reported separately. PSA-RE bits 3.2-3.1. Sending an automatic eCall after a detected impact Upstream default raw=1 (not necessarily valid data).";
CM_ SG_ 24 Unused1 "DATABASE_CANDIDATE: physical interpretation unverified; capture/layout evidence reported separately. PSA-RE bits 3.6-3.3. ";
CM_ SG_ 24 CrashUnlockRequest "DATABASE_CANDIDATE: physical interpretation unverified; capture/layout evidence reported separately. PSA-RE bits 3.7. Unlock request during crash Upstream default raw=0 (not necessarily valid data). Unresolved source alternatives: [{\"note\": \"Also observed at bits 4.7\", \"bits\": \"4.7\"}]";
CM_ SG_ 24 CrashDetectedSinceLastPowerUp "DATABASE_CANDIDATE: physical interpretation unverified; capture/layout evidence reported separately. PSA-RE bits 2.0. Crash detected since the last power-up Upstream default raw=0 (not necessarily valid data).";
CM_ SG_ 24 RolloverCrash "DATABASE_CANDIDATE: physical interpretation unverified; capture/layout evidence reported separately. PSA-RE bits 2.1. Rollover crash info Upstream default raw=0 (not necessarily valid data).";
CM_ SG_ 24 HighSpeedRearCrash "DATABASE_CANDIDATE: physical interpretation unverified; capture/layout evidence reported separately. PSA-RE bits 2.2. High speed rear crash info Upstream default raw=0 (not necessarily valid data).";
CM_ SG_ 24 AverageSpeedRearCrash "DATABASE_CANDIDATE: physical interpretation unverified; capture/layout evidence reported separately. PSA-RE bits 2.3. Average speed rear crash info Upstream default raw=0 (not necessarily valid data).";
CM_ SG_ 24 LowSpeedRearCrash "DATABASE_CANDIDATE: physical interpretation unverified; capture/layout evidence reported separately. PSA-RE bits 2.4. Low speed rear crash info Upstream default raw=0 (not necessarily valid data).";
CM_ SG_ 24 PossibleRearCrash "DATABASE_CANDIDATE: physical interpretation unverified; capture/layout evidence reported separately. PSA-RE bits 2.5. Possibility of repairing after rear crash Upstream default raw=0 (not necessarily valid data).";
CM_ SG_ 24 HighSpeedSideCrash "DATABASE_CANDIDATE: physical interpretation unverified; capture/layout evidence reported separately. PSA-RE bits 2.6. High speed side crash info Upstream default raw=0 (not necessarily valid data).";
CM_ SG_ 24 AverageSpeedSideCrash "DATABASE_CANDIDATE: physical interpretation unverified; capture/layout evidence reported separately. PSA-RE bits 2.7. Average speed side crash info Upstream default raw=0 (not necessarily valid data).";
CM_ SG_ 24 LowSpeedSideCrash "DATABASE_CANDIDATE: physical interpretation unverified; capture/layout evidence reported separately. PSA-RE bits 1.0. Low speed side crash info Upstream default raw=0 (not necessarily valid data).";
CM_ SG_ 24 PossibleSideCrash "DATABASE_CANDIDATE: physical interpretation unverified; capture/layout evidence reported separately. PSA-RE bits 1.1. Possibility of repairing after side crash Upstream default raw=0 (not necessarily valid data).";
CM_ SG_ 24 HighSpeedFrontalCrash "DATABASE_CANDIDATE: physical interpretation unverified; capture/layout evidence reported separately. PSA-RE bits 1.2. High speed front crash info Upstream default raw=0 (not necessarily valid data).";
CM_ SG_ 24 AverageSpeedFrontalCrashN2 "DATABASE_CANDIDATE: physical interpretation unverified; capture/layout evidence reported separately. PSA-RE bits 1.3. N2 average speed front crash info Upstream default raw=0 (not necessarily valid data).";
CM_ SG_ 24 AverageSpeedFrontalCrashN1 "DATABASE_CANDIDATE: physical interpretation unverified; capture/layout evidence reported separately. PSA-RE bits 1.4. N1 average speed front crash info Upstream default raw=0 (not necessarily valid data).";
CM_ SG_ 24 LowSpeedFrontalCrash "DATABASE_CANDIDATE: physical interpretation unverified; capture/layout evidence reported separately. PSA-RE bits 1.5. Low speed front crash info Upstream default raw=0 (not necessarily valid data).";
CM_ SG_ 24 PossibleFrontalCrash "DATABASE_CANDIDATE: physical interpretation unverified; capture/layout evidence reported separately. PSA-RE bits 1.6. Possibility of repairing after front crash Upstream default raw=0 (not necessarily valid data).";
CM_ SG_ 24 PassengerAirbagInhibitionStatus "DATABASE_CANDIDATE: physical interpretation unverified; capture/layout evidence reported separately. PSA-RE bits 1.7. Passenger airbag real inhibition state Upstream default raw=0 (not necessarily valid data).";
CM_ BO_ 28 "DATABASE_CANDIDATE: physical interpretation unverified; capture/layout evidence reported separately. INFO-DIV CAN, 125000 bit/s; CAN ID 0x01C. PSA-RE title: MOTION_SENSOR_COMMAND_RIGHT. Preconditioning and cruise control menu commands: button presses, cruise info availability, preconditioning activation and type request. Source: https://github.com/prototux/PSA-RE/blob/67f7581e7622410efdbb29c7eda3b86982b9b450/buses/AEE2010.full/LS.INFO-DIV/01C.yml. Source sender alternatives: ICSV,BTEL,MATT,EMF,OVIP,CMB; physical TX/gateway forwarding not verified. Observed 6 frames in info_apka.csv,info_buzeni_obc.csv,info_charging.csv,infocan.csv; DLCs [8]. ";
CM_ SG_ 28 SpeedLimitZone5Speed "DATABASE_CANDIDATE: physical interpretation unverified; capture/layout evidence reported separately. PSA-RE bits 8.7-8.0. Speed limiter zone 5 speed value Upstream default raw=0 (not necessarily valid data).";
CM_ SG_ 28 SpeedLimitZone4Speed "DATABASE_CANDIDATE: physical interpretation unverified; capture/layout evidence reported separately. PSA-RE bits 7.7-7.0. Speed limiter zone 4 speed value Upstream default raw=0 (not necessarily valid data).";
CM_ SG_ 28 SpeedLimitZone3Speed "DATABASE_CANDIDATE: physical interpretation unverified; capture/layout evidence reported separately. PSA-RE bits 6.7-6.0. Speed limiter zone 3 speed value Upstream default raw=0 (not necessarily valid data).";
CM_ SG_ 28 SpeedLimitZone2Speed "DATABASE_CANDIDATE: physical interpretation unverified; capture/layout evidence reported separately. PSA-RE bits 5.7-5.0. Speed limiter zone 2 speed value Upstream default raw=0 (not necessarily valid data).";
CM_ SG_ 28 SpeedLimitZone1Speed "DATABASE_CANDIDATE: physical interpretation unverified; capture/layout evidence reported separately. PSA-RE bits 4.7-4.0. Speed limiter zone 1 speed value Upstream default raw=0 (not necessarily valid data).";
CM_ SG_ 28 SpeedLimitZone5State "DATABASE_CANDIDATE: physical interpretation unverified; capture/layout evidence reported separately. PSA-RE bits 3.0. Speed limiter zone 5 function state Upstream default raw=0 (not necessarily valid data).";
CM_ SG_ 28 SpeedLimitZone4State "DATABASE_CANDIDATE: physical interpretation unverified; capture/layout evidence reported separately. PSA-RE bits 3.1. Speed limiter zone 4 function state Upstream default raw=0 (not necessarily valid data).";
CM_ SG_ 28 SpeedLimitZone3State "DATABASE_CANDIDATE: physical interpretation unverified; capture/layout evidence reported separately. PSA-RE bits 3.2. Speed limiter zone 3 function state Upstream default raw=0 (not necessarily valid data).";
CM_ SG_ 28 SpeedLimitZone2State "DATABASE_CANDIDATE: physical interpretation unverified; capture/layout evidence reported separately. PSA-RE bits 3.3. Speed limiter zone 2 function state Upstream default raw=0 (not necessarily valid data).";
CM_ SG_ 28 SpeedLimitZone1State "DATABASE_CANDIDATE: physical interpretation unverified; capture/layout evidence reported separately. PSA-RE bits 3.4. Speed limiter zone 1 function state Upstream default raw=0 (not necessarily valid data).";
CM_ SG_ 28 Unused2 "DATABASE_CANDIDATE: physical interpretation unverified; capture/layout evidence reported separately. PSA-RE bits 3.5. ";
CM_ SG_ 28 SpeedLimitMainState "DATABASE_CANDIDATE: physical interpretation unverified; capture/layout evidence reported separately. PSA-RE bits 3.6. Speed limiter main function state Upstream default raw=0 (not necessarily valid data).";
CM_ SG_ 28 CruiseMenuInfoAvailability "DATABASE_CANDIDATE: physical interpretation unverified; capture/layout evidence reported separately. PSA-RE bits 3.7. Cruise control menu information availability Upstream default raw=0 (not necessarily valid data).";
CM_ SG_ 28 PreconditioningClockSelection "DATABASE_CANDIDATE: physical interpretation unverified; capture/layout evidence reported separately. PSA-RE bits 1.3-2.0. Thermal preconditioning clock selection Raw invalid=2047; numeric DBC decoders may still scale it: check raw before use.";
CM_ SG_ 28 PreconditioningActivationRequest "DATABASE_CANDIDATE: physical interpretation unverified; capture/layout evidence reported separately. PSA-RE bits 1.4. Thermal preconditioning activation request";
CM_ SG_ 28 PreconditioningTypeRequest "DATABASE_CANDIDATE: physical interpretation unverified; capture/layout evidence reported separately. PSA-RE bits 1.5. Thermal preconditioning type request (ventilation/preheating)";
CM_ SG_ 28 PreconditioningDataValidity "DATABASE_CANDIDATE: physical interpretation unverified; capture/layout evidence reported separately. PSA-RE bits 1.6. Thermal preconditioning data validity";
CM_ SG_ 28 Unused1 "DATABASE_CANDIDATE: physical interpretation unverified; capture/layout evidence reported separately. PSA-RE bits 1.7. ";
CM_ BO_ 29 "DATABASE_CANDIDATE: physical interpretation unverified; capture/layout evidence reported separately. INFO-DIV CAN, 125000 bit/s; CAN ID 0x01D. PSA-RE title: WAKEUP_MUS. Handshake frame sent by the steering column lock module (SDCM) back to the body computer (BSI) during the pairing sequence. Source: https://github.com/prototux/PSA-RE/blob/67f7581e7622410efdbb29c7eda3b86982b9b450/buses/AEE2010.full/LS.INFO-DIV/01D.yml. Source sender alternatives: SDCM; physical TX/gateway forwarding not verified. Observed 5 frames in info_apka.csv,info_start_jizda.csv,infocan.csv; DLCs [1]. ";
CM_ SG_ 29 Unused1 "DATABASE_CANDIDATE: physical interpretation unverified; capture/layout evidence reported separately. PSA-RE bits 1.6-1.0. ";
CM_ SG_ 29 HandshakeSdcmToBsi "DATABASE_CANDIDATE: physical interpretation unverified; capture/layout evidence reported separately. PSA-RE bits 1.7. Handshake for the communication frame sent by the SDCM to the BSI";
CM_ BO_ 30 "DATABASE_CANDIDATE: physical interpretation unverified; capture/layout evidence reported separately. INFO-DIV CAN, 125000 bit/s; CAN ID 0x01E. PSA-RE title: WAKEUP_SIR. Handshake frame sent by the body computer (BSI) to the steering column lock module (SDCM) during the pairing sequence. Source: https://github.com/prototux/PSA-RE/blob/67f7581e7622410efdbb29c7eda3b86982b9b450/buses/AEE2010.full/LS.INFO-DIV/01E.yml. Source sender alternatives: BSI; physical TX/gateway forwarding not verified. Observed 14 frames in info_standby.csv,info_start_jizda.csv,infocan.csv; DLCs [1]. ";
CM_ SG_ 30 Unused1 "DATABASE_CANDIDATE: physical interpretation unverified; capture/layout evidence reported separately. PSA-RE bits 1.6-1.0. ";
CM_ SG_ 30 HandshakeBsiToSdcm "DATABASE_CANDIDATE: physical interpretation unverified; capture/layout evidence reported separately. PSA-RE bits 1.7. Handshake for the communication frame sent by the BSI to the SDCM";
CM_ BO_ 40 "DATABASE_CANDIDATE: physical interpretation unverified; capture/layout evidence reported separately. INFO-DIV CAN, 125000 bit/s; CAN ID 0x028. PSA-RE title: ADDITIVE_PUMP_COMMAND_2. Allowed levels of driver-vehicle interaction (voice, touch, text, gestures) sent by the BSI to restrict distraction. Source: https://github.com/prototux/PSA-RE/blob/67f7581e7622410efdbb29c7eda3b86982b9b450/buses/AEE2010.full/LS.INFO-DIV/028.yml. Source sender alternatives: BSI; physical TX/gateway forwarding not verified. Observed 586 frames in info_apka.csv,info_buzeni_obc.csv,info_charging.csv,info_standby.csv,info_start_jizda.csv,infocan.csv; DLCs [3]. ";
CM_ SG_ 40 Unused1 "DATABASE_CANDIDATE: physical interpretation unverified; capture/layout evidence reported separately. PSA-RE bits 3.6-3.0. ";
CM_ SG_ 40 AlwaysUsefulFunctionPermission "DATABASE_CANDIDATE: physical interpretation unverified; capture/layout evidence reported separately. PSA-RE bits 3.7. Permission of an always-useful function use case Upstream default raw=0 (not necessarily valid data).";
CM_ SG_ 40 AlwaysUselessFunctionRestriction "DATABASE_CANDIDATE: physical interpretation unverified; capture/layout evidence reported separately. PSA-RE bits 2.1-2.0. Restriction of an always-useless function use case Upstream default raw=0 (not necessarily valid data).";
CM_ SG_ 40 PrecisionGestureInteracti_60b22b "DATABASE_CANDIDATE: physical interpretation unverified; capture/layout evidence reported separately. PSA-RE bits 2.3-2.2. Allowed precision gesture interaction task Upstream default raw=0 (not necessarily valid data).";
CM_ SG_ 40 NumericInputInteractionAllowed "DATABASE_CANDIDATE: physical interpretation unverified; capture/layout evidence reported separately. PSA-RE bits 2.5-2.4. Allowed numerical input interaction task Upstream default raw=0 (not necessarily valid data).";
CM_ SG_ 40 OffboardHmiInteractionAllowed "DATABASE_CANDIDATE: physical interpretation unverified; capture/layout evidence reported separately. PSA-RE bits 2.7-2.6. Allowed offboard HMI interaction task Upstream default raw=0 (not necessarily valid data).";
CM_ SG_ 40 TextReadingInteractionAllowed "DATABASE_CANDIDATE: physical interpretation unverified; capture/layout evidence reported separately. PSA-RE bits 1.1-1.0. Allowed text reading interaction task Upstream default raw=0 (not necessarily valid data).";
CM_ SG_ 40 ObjectManagementInteracti_8211bb "DATABASE_CANDIDATE: physical interpretation unverified; capture/layout evidence reported separately. PSA-RE bits 1.3-1.2. Allowed object managing interaction task Upstream default raw=0 (not necessarily valid data).";
CM_ SG_ 40 DynamicVisualFeedbackInte_8afc95 "DATABASE_CANDIDATE: physical interpretation unverified; capture/layout evidence reported separately. PSA-RE bits 1.5-1.4. Allowed dynamic visual feedback interaction task Upstream default raw=0 (not necessarily valid data).";
CM_ SG_ 40 AlphanumericKeyboardInter_499d43 "DATABASE_CANDIDATE: physical interpretation unverified; capture/layout evidence reported separately. PSA-RE bits 1.6. Allowed keyboard alphanumeric input interaction task Upstream default raw=0 (not necessarily valid data).";
CM_ SG_ 40 VeryDisturbingInteractionAllowed "DATABASE_CANDIDATE: physical interpretation unverified; capture/layout evidence reported separately. PSA-RE bits 1.7. Allowed very disturbing interaction task Upstream default raw=0 (not necessarily valid data).";
CM_ BO_ 48 "DATABASE_CANDIDATE: physical interpretation unverified; capture/layout evidence reported separately. INFO-DIV CAN, 125000 bit/s; CAN ID 0x030. PSA-RE title: FRONT_BODY_MODULE_COMMAND. Hybrid stop&start information: elapsed stop time, zero-emission request, engine/electric-machine state and recharge status. Source: https://github.com/prototux/PSA-RE/blob/67f7581e7622410efdbb29c7eda3b86982b9b450/buses/AEE2010.full/LS.INFO-DIV/030.yml. Source sender alternatives: BSI; physical TX/gateway forwarding not verified. ";
CM_ SG_ 48 RawBits51_55 "RAW. PSA-RE bits 7.4-7.0. Unmapped/padding bits, no physical interpretation.";
CM_ SG_ 48 BatterySocRedZone "DATABASE_CANDIDATE: physical interpretation unverified; capture/layout evidence reported separately. PSA-RE bits 6.4-7.5. Battery state of charge in the red (critical) zone Raw invalid=127; numeric DBC decoders may still scale it: check raw before use.";
CM_ SG_ 48 AccessoryInstantPowerConsumption "DATABASE_CANDIDATE: physical interpretation unverified; capture/layout evidence reported separately. PSA-RE bits 5.3-6.5. Instantaneous electric power consumption of the accessories Raw invalid=63; numeric DBC decoders may still scale it: check raw before use.";
CM_ SG_ 48 FrontElectricMotorStatus "DATABASE_CANDIDATE: physical interpretation unverified; capture/layout evidence reported separately. PSA-RE bits 5.5-5.4. Front electric motor status";
CM_ SG_ 48 ChargeStatus "DATABASE_CANDIDATE: physical interpretation unverified; capture/layout evidence reported separately. PSA-RE bits 5.7-5.6. Current charge/discharge status";
CM_ SG_ 48 ElectricMotorStatus "DATABASE_CANDIDATE: physical interpretation unverified; capture/layout evidence reported separately. PSA-RE bits 4.1-4.0. Electric motor status";
CM_ SG_ 48 CombustionEngineStatus "DATABASE_CANDIDATE: physical interpretation unverified; capture/layout evidence reported separately. PSA-RE bits 4.3-4.2. Combustion engine status";
CM_ SG_ 48 ZeroEmissionRequest "DATABASE_CANDIDATE: physical interpretation unverified; capture/layout evidence reported separately. PSA-RE bits 4.4. Zero-emission request";
CM_ SG_ 48 StartStopPresence "DATABASE_CANDIDATE: physical interpretation unverified; capture/layout evidence reported separately. PSA-RE bits 4.5. Presence of the Stop & Start function";
CM_ SG_ 48 StartStopAvailability "DATABASE_CANDIDATE: physical interpretation unverified; capture/layout evidence reported separately. PSA-RE bits 4.7-4.6. Stop & Start function availability";
CM_ SG_ 48 RawByte3 "RAW. PSA-RE bits 3.7-3.0. Unmapped/padding bits, no physical interpretation.";
CM_ SG_ 48 RawBits14_15 "RAW. PSA-RE bits 2.1-2.0. Unmapped/padding bits, no physical interpretation.";
CM_ SG_ 48 SecondsStopCounter "DATABASE_CANDIDATE: physical interpretation unverified; capture/layout evidence reported separately. PSA-RE bits 2.7-2.2. Seconds at STOP Raw invalid=63; numeric DBC decoders may still scale it: check raw before use.";
CM_ SG_ 48 MinutesStopCounter "DATABASE_CANDIDATE: physical interpretation unverified; capture/layout evidence reported separately. PSA-RE bits 1.5-1.0. Minutes at STOP Raw invalid=63; numeric DBC decoders may still scale it: check raw before use.";
CM_ SG_ 48 HoursStopCounter "DATABASE_CANDIDATE: physical interpretation unverified; capture/layout evidence reported separately. PSA-RE bits 1.7-1.6. Hour at STOP";
CM_ BO_ 54 "DATABASE_CANDIDATE: physical interpretation unverified; capture/layout evidence reported separately. INFO-DIV CAN, 125000 bit/s; CAN ID 0x036. PSA-RE title: RADIO_COMMANDS. Audio remote control commands from the steering column switch unit (under-wheel radio controls, excluding stalk end pushes), relayed by the BSI. Source: https://github.com/prototux/PSA-RE/blob/67f7581e7622410efdbb29c7eda3b86982b9b450/buses/AEE2010.full/LS.INFO-DIV/036.yml. Source sender alternatives: BSI; physical TX/gateway forwarding not verified. Observed 6874 frames in info_apka.csv,info_buzeni_obc.csv,info_charging.csv,info_standby.csv,info_start_jizda.csv,infocan.csv; DLCs [8]. ";
CM_ SG_ 54 TePosition "DATABASE_CANDIDATE: physical interpretation unverified; capture/layout evidence reported separately. PSA-RE bits 8.0. Retractable hardtop position (coupe or convertible) Upstream default raw=0 (not necessarily valid data).";
CM_ SG_ 54 AudioInviolability "DATABASE_CANDIDATE: physical interpretation unverified; capture/layout evidence reported separately. PSA-RE bits 8.1. Audio system inviolability (anti-theft protection) requested Upstream default raw=0 (not necessarily valid data).";
CM_ SG_ 54 EngineBayAccPowerCommand "DATABASE_CANDIDATE: physical interpretation unverified; capture/layout evidence reported separately. PSA-RE bits 8.3-8.2. Accessory power (+APC) control under the engine bonnet Upstream default raw=0 (not necessarily valid data).";
CM_ SG_ 54 SecureInfo "DATABASE_CANDIDATE: physical interpretation unverified; capture/layout evidence reported separately. PSA-RE bits 8.7-8.4. Redundant/secured main electrical system (SEV) state information Upstream default raw=5 (not necessarily valid data).";
CM_ SG_ 54 RadioOnOffSync "DATABASE_CANDIDATE: physical interpretation unverified; capture/layout evidence reported separately. PSA-RE bits 7.0. Radio ON/OFF button synchronization Upstream default raw=1 (not necessarily valid data).";
CM_ SG_ 54 RadioOnOffToggle "DATABASE_CANDIDATE: physical interpretation unverified; capture/layout evidence reported separately. PSA-RE bits 7.1. Radio ON/OFF toggle button Upstream default raw=0 (not necessarily valid data).";
CM_ SG_ 54 PreconditioningMenuPresence "DATABASE_CANDIDATE: physical interpretation unverified; capture/layout evidence reported separately. PSA-RE bits 7.2. Presence of the thermal preconditioning menu Upstream default raw=0 (not necessarily valid data).";
CM_ SG_ 54 AvrActivationStatus "DATABASE_CANDIDATE: physical interpretation unverified; capture/layout evidence reported separately. PSA-RE bits 7.3. Rear-view camera (AVR) activation status Upstream default raw=0 (not necessarily valid data).";
CM_ SG_ 54 CafrValidationCommand "DATABASE_CANDIDATE: physical interpretation unverified; capture/layout evidence reported separately. PSA-RE bits 7.4. CAFR validation command Upstream default raw=0 (not necessarily valid data).";
CM_ SG_ 54 Unused2 "DATABASE_CANDIDATE: physical interpretation unverified; capture/layout evidence reported separately. PSA-RE bits 7.5. ";
CM_ SG_ 54 SpeedDisplayOffset "DATABASE_CANDIDATE: physical interpretation unverified; capture/layout evidence reported separately. PSA-RE bits 7.6. Additional speed offset applied to the speed display Upstream default raw=0 (not necessarily valid data).";
CM_ SG_ 54 MediaShutdownRequest "DATABASE_CANDIDATE: physical interpretation unverified; capture/layout evidence reported separately. PSA-RE bits 7.7. Request to switch off the media system Upstream default raw=0 (not necessarily valid data).";
CM_ SG_ 54 HybridModeUpdated "DATABASE_CANDIDATE: physical interpretation unverified; capture/layout evidence reported separately. PSA-RE bits 6.0. Update flag for the hybrid powertrain mode signal Upstream default raw=0 (not necessarily valid data).";
CM_ SG_ 54 HybridMode "DATABASE_CANDIDATE: physical interpretation unverified; capture/layout evidence reported separately. PSA-RE bits 6.3-6.1. Hybrid powertrain usage mode (4x4, Sport, Hybrid, Zero-emission) Upstream default raw=2 (not necessarily valid data).";
CM_ SG_ 54 HybridStatusUpdated "DATABASE_CANDIDATE: physical interpretation unverified; capture/layout evidence reported separately. PSA-RE bits 6.4. Update flag for the hybrid powertrain status signal Upstream default raw=0 (not necessarily valid data).";
CM_ SG_ 54 HybridStatus "DATABASE_CANDIDATE: physical interpretation unverified; capture/layout evidence reported separately. PSA-RE bits 6.7-6.5. Hybrid powertrain (GMP) status (idle, stopped, in traction, in propulsion) Upstream default raw=0 (not necessarily valid data).";
CM_ SG_ 54 PowerManagement "DATABASE_CANDIDATE: physical interpretation unverified; capture/layout evidence reported separately. PSA-RE bits 5.2-5.0. Network power management phase (sleep, normal, going to sleep, wake-up, COM off) Upstream default raw=3 (not necessarily valid data).";
CM_ SG_ 54 LogFaults "DATABASE_CANDIDATE: physical interpretation unverified; capture/layout evidence reported separately. PSA-RE bits 5.3. Fault storage locking (fault memory logging disabled) Upstream default raw=0 (not necessarily valid data).";
CM_ SG_ 54 DiagToolNetworkAuthorization "DATABASE_CANDIDATE: physical interpretation unverified; capture/layout evidence reported separately. PSA-RE bits 5.4. Internal diagnostic tool authorized to communicate on the networks Upstream default raw=1 (not necessarily valid data).";
CM_ SG_ 54 DiagStatus "DATABASE_CANDIDATE: physical interpretation unverified; capture/layout evidence reported separately. PSA-RE bits 5.5. Multiplexed communication diagnostic status Upstream default raw=0 (not necessarily valid data).";
CM_ SG_ 54 ClearFaults "DATABASE_CANDIDATE: physical interpretation unverified; capture/layout evidence reported separately. PSA-RE bits 5.6. Global fault memory erase request Upstream default raw=0 (not necessarily valid data).";
CM_ SG_ 54 DynamicPackActivation "DATABASE_CANDIDATE: physical interpretation unverified; capture/layout evidence reported separately. PSA-RE bits 5.7. Dynamic driving pack activation request Upstream default raw=0 (not necessarily valid data).";
CM_ SG_ 54 Brightness "DATABASE_CANDIDATE: physical interpretation unverified; capture/layout evidence reported separately. PSA-RE bits 4.3-4.0. Brightness level to apply (0 = minimum, 15 = maximum) Upstream default raw=8 (not necessarily valid data).";
CM_ SG_ 54 DarkMode "DATABASE_CANDIDATE: physical interpretation unverified; capture/layout evidence reported separately. PSA-RE bits 4.4. Instrument cluster brightness in Black Panel (dark) mode Upstream default raw=0 (not necessarily valid data).";
CM_ SG_ 54 DaynightStatus "DATABASE_CANDIDATE: physical interpretation unverified; capture/layout evidence reported separately. PSA-RE bits 4.5. Day/night state Upstream default raw=0 (not necessarily valid data).";
CM_ SG_ 54 RheostatType "DATABASE_CANDIDATE: physical interpretation unverified; capture/layout evidence reported separately. PSA-RE bits 4.6. Rheostat type (manual or automatic) Upstream default raw=0 (not necessarily valid data).";
CM_ SG_ 54 Resynchronization "DATABASE_CANDIDATE: physical interpretation unverified; capture/layout evidence reported separately. PSA-RE bits 4.7. Reference level resynchronization request Upstream default raw=0 (not necessarily valid data).";
CM_ SG_ 54 AmbientLightLevelFmux "DATABASE_CANDIDATE: physical interpretation unverified; capture/layout evidence reported separately. PSA-RE bits 3.6-3.0. Ambient lighting rheostat level (FMUX) Raw invalid=127; numeric DBC decoders may still scale it: check raw before use. Upstream default raw=80 (not necessarily valid data).";
CM_ SG_ 54 EcoMode "DATABASE_CANDIDATE: physical interpretation unverified; capture/layout evidence reported separately. PSA-RE bits 3.7. Eco driving mode status Upstream default raw=0 (not necessarily valid data).";
CM_ SG_ 54 Unused1 "DATABASE_CANDIDATE: physical interpretation unverified; capture/layout evidence reported separately. PSA-RE bits 2.7-2.0. ";
CM_ SG_ 54 DriverMemoryCount "DATABASE_CANDIDATE: physical interpretation unverified; capture/layout evidence reported separately. PSA-RE bits 1.3-1.0. Driver memory slot number to use Upstream default raw=14 (not necessarily valid data).";
CM_ SG_ 54 DriverMemorySave "DATABASE_CANDIDATE: physical interpretation unverified; capture/layout evidence reported separately. PSA-RE bits 1.4. Driver seat position memory save command Upstream default raw=0 (not necessarily valid data).";
CM_ SG_ 54 DriverMemory "DATABASE_CANDIDATE: physical interpretation unverified; capture/layout evidence reported separately. PSA-RE bits 1.5. Driver seat position memory recall command Upstream default raw=0 (not necessarily valid data).";
CM_ SG_ 54 VehicleDirection "DATABASE_CANDIDATE: physical interpretation unverified; capture/layout evidence reported separately. PSA-RE bits 1.7-1.6. Vehicle direction of travel Upstream default raw=0 (not necessarily valid data).";
CM_ BO_ 65 "DATABASE_CANDIDATE: physical interpretation unverified; capture/layout evidence reported separately. INFO-DIV CAN, 125000 bit/s; CAN ID 0x041. PSA-RE title: UID_TABLE_LEARN_REQUEST_TO_SDCM. Request to learn the identifier table sent to the SDCM Source: https://github.com/prototux/PSA-RE/blob/67f7581e7622410efdbb29c7eda3b86982b9b450/buses/AEE2010.full/LS.INFO-DIV/041.yml. Source sender alternatives: SDCM; physical TX/gateway forwarding not verified. ";
CM_ SG_ 65 Unused1 "DATABASE_CANDIDATE: physical interpretation unverified; capture/layout evidence reported separately. PSA-RE bits 1.6-1.0. ";
CM_ SG_ 65 UidTableLearnRequestToSdcm "DATABASE_CANDIDATE: physical interpretation unverified; capture/layout evidence reported separately. PSA-RE bits 1.7. Encrypted request to learn the UID table, sent to the smart device module (SDCM)";
CM_ BO_ 77 "DATABASE_CANDIDATE: physical interpretation unverified; capture/layout evidence reported separately. INFO-DIV CAN, 125000 bit/s; CAN ID 0x04D. PSA-RE title: UNCIPHERED_DATA_SDCM_TO_BSI. Unencrypted hands-free key search and blacklist data sent from the SDCM to the BSI Source: https://github.com/prototux/PSA-RE/blob/67f7581e7622410efdbb29c7eda3b86982b9b450/buses/AEE2010.full/LS.INFO-DIV/04D.yml. Source sender alternatives: SDCM; physical TX/gateway forwarding not verified. Observed 12 frames in info_standby.csv,info_start_jizda.csv,infocan.csv; DLCs [8]. ";
CM_ SG_ 77 SmartDeviceCommandToBsi "DATABASE_CANDIDATE: physical interpretation unverified; capture/layout evidence reported separately. PSA-RE bits 8.7-8.0. Smart device command relayed by the SDCM module to the BSI. Source text/byte field exposed as raw integer; no string decoding. Upstream default raw=0 (not necessarily valid data).";
CM_ SG_ 77 Unused1 "DATABASE_CANDIDATE: physical interpretation unverified; capture/layout evidence reported separately. PSA-RE bits 7.7-7.0. ";
CM_ SG_ 77 Cid5Status "DATABASE_CANDIDATE: physical interpretation unverified; capture/layout evidence reported separately. PSA-RE bits 6.0. Indicates whether hands-free key (CID) number 5 is enabled or blacklisted. Upstream default raw=0 (not necessarily valid data).";
CM_ SG_ 77 Cid4Status "DATABASE_CANDIDATE: physical interpretation unverified; capture/layout evidence reported separately. PSA-RE bits 6.1. Indicates whether hands-free key (CID) number 4 is enabled or blacklisted. Upstream default raw=0 (not necessarily valid data).";
CM_ SG_ 77 Cid3Status "DATABASE_CANDIDATE: physical interpretation unverified; capture/layout evidence reported separately. PSA-RE bits 6.2. Indicates whether hands-free key (CID) number 3 is enabled or blacklisted. Upstream default raw=0 (not necessarily valid data).";
CM_ SG_ 77 Cid2Status "DATABASE_CANDIDATE: physical interpretation unverified; capture/layout evidence reported separately. PSA-RE bits 6.3. Indicates whether hands-free key (CID) number 2 is enabled or blacklisted. Upstream default raw=0 (not necessarily valid data).";
CM_ SG_ 77 BlacklistingTaskStatus "DATABASE_CANDIDATE: physical interpretation unverified; capture/layout evidence reported separately. PSA-RE bits 6.5-6.4. Status indicating that a blacklisting (or unblacklisting) operation is in progress. Upstream default raw=0 (not necessarily valid data).";
CM_ SG_ 77 NfcIdentifiedOutside "DATABASE_CANDIDATE: physical interpretation unverified; capture/layout evidence reported separately. PSA-RE bits 6.7-6.6. Indicates whether an NFC card was identified outside the vehicle, and for how long.";
CM_ SG_ 77 Cid1Status "DATABASE_CANDIDATE: physical interpretation unverified; capture/layout evidence reported separately. PSA-RE bits 5.0. Indicates whether hands-free key (CID) number 1 is enabled or blacklisted. Upstream default raw=0 (not necessarily valid data).";
CM_ SG_ 77 AuthenticatedDeviceNumber "DATABASE_CANDIDATE: physical interpretation unverified; capture/layout evidence reported separately. PSA-RE bits 5.4-5.1. Number of the authenticated device: 1-5 for CID keys, 6-10 for NFC cards, 11-15 for smart devices. Upstream default raw=0 (not necessarily valid data).";
CM_ SG_ 77 NfcCardNumber "DATABASE_CANDIDATE: physical interpretation unverified; capture/layout evidence reported separately. PSA-RE bits 5.7-5.5. NFC card number used for the NFC access command (1-5); 0 if none is associated.";
CM_ SG_ 77 SmartDeviceNumber "DATABASE_CANDIDATE: physical interpretation unverified; capture/layout evidence reported separately. PSA-RE bits 4.2-4.0. Smart device number used for a remote command (Bluetooth or NFC), 1-5; 0 if none is associated.";
CM_ SG_ 77 HandsfreeCidNumber "DATABASE_CANDIDATE: physical interpretation unverified; capture/layout evidence reported separately. PSA-RE bits 4.5-4.3. Hands-free key (CID) number used for the hands-free access command (1-5); 0 if none is associated.";
CM_ SG_ 77 SmartDeviceBtAuthenticati_9fe3dd "DATABASE_CANDIDATE: physical interpretation unverified; capture/layout evidence reported separately. PSA-RE bits 4.7-4.6. Response to a smart device authentication attempt over Bluetooth.";
CM_ SG_ 77 SmartDeviceNfcAuthenticat_6dabc9 "DATABASE_CANDIDATE: physical interpretation unverified; capture/layout evidence reported separately. PSA-RE bits 3.1-3.0. Response to a smart device authentication attempt over NFC.";
CM_ SG_ 77 NfcCardAuthenticationResult "DATABASE_CANDIDATE: physical interpretation unverified; capture/layout evidence reported separately. PSA-RE bits 3.3-3.2. Response to an NFC card authentication attempt.";
CM_ SG_ 77 CidAuthenticationResult "DATABASE_CANDIDATE: physical interpretation unverified; capture/layout evidence reported separately. PSA-RE bits 3.5-3.4. Response to a hands-free key (CID) authentication attempt.";
CM_ SG_ 77 CidFoundInLockArea "DATABASE_CANDIDATE: physical interpretation unverified; capture/layout evidence reported separately. PSA-RE bits 3.7-3.6. Indicates whether at least one hands-free key (CID) was found in the walk-away-locking area. Upstream default raw=0 (not necessarily valid data).";
CM_ SG_ 77 CidSearchAnswer "DATABASE_CANDIDATE: physical interpretation unverified; capture/layout evidence reported separately. PSA-RE bits 2.1-2.0. Indicates whether at least one hands-free key (CID) was found by the requested search. Upstream default raw=0 (not necessarily valid data).";
CM_ SG_ 77 CidOutsideSearchStatus "DATABASE_CANDIDATE: physical interpretation unverified; capture/layout evidence reported separately. PSA-RE bits 2.3-2.2. Status of an outside search for hands-free keys (CID): whether it is running and how it was launched. Upstream default raw=0 (not necessarily valid data).";
CM_ SG_ 77 CidFoundInside "DATABASE_CANDIDATE: physical interpretation unverified; capture/layout evidence reported separately. PSA-RE bits 2.5-2.4. Indicates whether a hands-free key (CID) was found inside the vehicle, updated at the end of an inside search. Upstream default raw=0 (not necessarily valid data).";
CM_ SG_ 77 CidInsideSearchStatus "DATABASE_CANDIDATE: physical interpretation unverified; capture/layout evidence reported separately. PSA-RE bits 2.7-2.6. Status of an inside search for hands-free keys (CID): whether it is running and how it was launched. Upstream default raw=0 (not necessarily valid data).";
CM_ SG_ 77 HandsfreeClosureButtonAction "DATABASE_CANDIDATE: physical interpretation unverified; capture/layout evidence reported separately. PSA-RE bits 1.1-1.0. Indicates the action performed with the hands-free access button. Upstream default raw=0 (not necessarily valid data).";
CM_ SG_ 77 HandsfreeClosureButton "DATABASE_CANDIDATE: physical interpretation unverified; capture/layout evidence reported separately. PSA-RE bits 1.3-1.2. Indicates which hands-free access button was pressed (none if no action detected). Upstream default raw=0 (not necessarily valid data).";
CM_ SG_ 77 HandsfreeAreaTransition "DATABASE_CANDIDATE: physical interpretation unverified; capture/layout evidence reported separately. PSA-RE bits 1.7-1.4. Movement of a paired hands-free key (CID) between detection areas (welcome, unlock, walk-away locking, etc.). Upstream default raw=0 (not necessarily valid data).";
CM_ BO_ 79 "DATABASE_CANDIDATE: physical interpretation unverified; capture/layout evidence reported separately. INFO-DIV CAN, 125000 bit/s; CAN ID 0x04F. PSA-RE title: UNCIPHERED_DATA_BSI_TO_SDCM. Unencrypted configuration and authorisation data sent from the BSI to the SDCM: blacklist requests, hands-free/smart-device activation and vehicle configuration mode Source: https://github.com/prototux/PSA-RE/blob/67f7581e7622410efdbb29c7eda3b86982b9b450/buses/AEE2010.full/LS.INFO-DIV/04F.yml. Source sender alternatives: BSI; physical TX/gateway forwarding not verified. Observed 3 frames in info_start_jizda.csv; DLCs [8]. ";
CM_ SG_ 79 Unused2 "DATABASE_CANDIDATE: physical interpretation unverified; capture/layout evidence reported separately. PSA-RE bits 3.7-8.0. ";
CM_ SG_ 79 Unused1 "DATABASE_CANDIDATE: physical interpretation unverified; capture/layout evidence reported separately. PSA-RE bits 2.1-2.0. ";
CM_ SG_ 79 UnblacklistingRequest "DATABASE_CANDIDATE: physical interpretation unverified; capture/layout evidence reported separately. PSA-RE bits 2.2. Request to restore devices previously blacklisted inside the vehicle (used after an identified unlock request). Upstream default raw=0 (not necessarily valid data).";
CM_ SG_ 79 BlacklistingRequest "DATABASE_CANDIDATE: physical interpretation unverified; capture/layout evidence reported separately. PSA-RE bits 2.3. Request to make devices identified inside the vehicle unavailable (used when locking with devices still inside). Upstream default raw=0 (not necessarily valid data).";
CM_ SG_ 79 VehicleConfigMode "DATABASE_CANDIDATE: physical interpretation unverified; capture/layout evidence reported separately. PSA-RE bits 2.7-2.4. Vehicle configuration mode Upstream default raw=4 (not necessarily valid data).";
CM_ SG_ 79 HandsfreeAccessDisableRequest "DATABASE_CANDIDATE: physical interpretation unverified; capture/layout evidence reported separately. PSA-RE bits 1.0. Request to disallow all hands-free access features (polling, capacitive sensor, etc.); remote control (RKE) still works. Upstream default raw=1 (not necessarily valid data).";
CM_ SG_ 79 MainStatus "DATABASE_CANDIDATE: physical interpretation unverified; capture/layout evidence reported separately. PSA-RE bits 1.2-1.1. Vehicle electrical system main state Upstream default raw=0 (not necessarily valid data).";
CM_ SG_ 79 WalUirTransitionIgnoreFlag "DATABASE_CANDIDATE: physical interpretation unverified; capture/layout evidence reported separately. PSA-RE bits 1.3. Tells the SDCM that walk-away-locking and unlock-in-run transitions are not taken into account to (un)lock the vehicle. Upstream default raw=1 (not necessarily valid data).";
CM_ SG_ 79 HandsfreePollingDeactivat_5edcdb "DATABASE_CANDIDATE: physical interpretation unverified; capture/layout evidence reported separately. PSA-RE bits 1.5-1.4. Request to stop hands-free access polling. Upstream default raw=0 (not necessarily valid data).";
CM_ SG_ 79 SdcmAuthorizationRequest "DATABASE_CANDIDATE: physical interpretation unverified; capture/layout evidence reported separately. PSA-RE bits 1.6. Request to disallow all SDCM (smart device connectivity module) features. Upstream default raw=1 (not necessarily valid data).";
CM_ SG_ 79 SmartDeviceCommDisableRequest "DATABASE_CANDIDATE: physical interpretation unverified; capture/layout evidence reported separately. PSA-RE bits 1.7. Request to disallow communications between the SDCM and any smart device (Bluetooth and NFC); NFC cards and hands-free features still work. Upstream default raw=1 (not necessarily valid data).";
CM_ BO_ 97 "DATABASE_CANDIDATE: physical interpretation unverified; capture/layout evidence reported separately. INFO-DIV CAN, 125000 bit/s; CAN ID 0x061. PSA-RE title: PARKING_SLOT_DATA. Detected parking slot data: depth, length, orientation, position (x/y), side, type and video-overlay status. Source: https://github.com/prototux/PSA-RE/blob/67f7581e7622410efdbb29c7eda3b86982b9b450/buses/AEE2010.full/LS.INFO-DIV/061.yml. Source sender alternatives: AAS; physical TX/gateway forwarding not verified. ";
CM_ SG_ 97 Unused1 "DATABASE_CANDIDATE: physical interpretation unverified; capture/layout evidence reported separately. PSA-RE bits 6.3-6.0. ";
CM_ SG_ 97 ParkSlotSide "DATABASE_CANDIDATE: physical interpretation unverified; capture/layout evidence reported separately. PSA-RE bits 6.4. Side of the selected parking spot Upstream default raw=0 (not necessarily valid data).";
CM_ SG_ 97 CpkStatus "DATABASE_CANDIDATE: physical interpretation unverified; capture/layout evidence reported separately. PSA-RE bits 6.6-6.5. CPK (automatic parking) function status Upstream default raw=0 (not necessarily valid data).";
CM_ SG_ 97 ParkSlotPositionX "DATABASE_CANDIDATE: physical interpretation unverified; capture/layout evidence reported separately. PSA-RE bits 5.7-6.7. X position of the selected parking spot relative to the vehicle's rear axle center Upstream default raw=255 (not necessarily valid data).";
CM_ SG_ 97 ParkSlotType "DATABASE_CANDIDATE: physical interpretation unverified; capture/layout evidence reported separately. PSA-RE bits 4.0. Type of the selected parking spot Upstream default raw=0 (not necessarily valid data).";
CM_ SG_ 97 ParkSlotPositionY "DATABASE_CANDIDATE: physical interpretation unverified; capture/layout evidence reported separately. PSA-RE bits 4.7-4.1. Y position of the selected parking spot relative to the vehicle's central axis Upstream default raw=63 (not necessarily valid data).";
CM_ SG_ 97 ParkSlotOrientation "DATABASE_CANDIDATE: physical interpretation unverified; capture/layout evidence reported separately. PSA-RE bits 3.7-3.0. Orientation of the selected parking spot relative to the vehicle's central axis Upstream default raw=0 (not necessarily valid data).";
CM_ SG_ 97 ParkSlotLength "DATABASE_CANDIDATE: physical interpretation unverified; capture/layout evidence reported separately. PSA-RE bits 2.7-2.0. Length of the selected parking spot Upstream default raw=0 (not necessarily valid data).";
CM_ SG_ 97 ParkSlotDepth "DATABASE_CANDIDATE: physical interpretation unverified; capture/layout evidence reported separately. PSA-RE bits 1.7-1.0. Depth of the selected parking spot Upstream default raw=0 (not necessarily valid data).";
CM_ BO_ 104 "DATABASE_CANDIDATE: physical interpretation unverified; capture/layout evidence reported separately. INFO-DIV CAN, 125000 bit/s; CAN ID 0x068. PSA-RE title: HYBRID_ZEV_DISTANCE. Corrected zero-emission distance and percentage for the current and previous two trips, relayed on the inter-system bus. Source: https://github.com/prototux/PSA-RE/blob/67f7581e7622410efdbb29c7eda3b86982b9b450/buses/AEE2010.full/LS.INFO-DIV/068.yml. Source sender alternatives: BSI; physical TX/gateway forwarding not verified. Observed 579 frames in info_apka.csv,info_buzeni_obc.csv,info_charging.csv,info_standby.csv,info_start_jizda.csv,infocan.csv; DLCs [8]. Unresolved alternative source layouts preserved in source JSON. ";
CM_ SG_ 104 Unused3 "DATABASE_CANDIDATE: physical interpretation unverified; capture/layout evidence reported separately. PSA-RE bits 8.7-8.0. ";
CM_ SG_ 104 Unused2 "DATABASE_CANDIDATE: physical interpretation unverified; capture/layout evidence reported separately. PSA-RE bits 7.7-7.0. ";
CM_ SG_ 104 Unused1 "DATABASE_CANDIDATE: physical interpretation unverified; capture/layout evidence reported separately. PSA-RE bits 6.5-6.0. ";
CM_ SG_ 104 ZevDistancePercentTrip2 "DATABASE_CANDIDATE: physical interpretation unverified; capture/layout evidence reported separately. PSA-RE bits 5.4-6.6. Percentage of distance covered in ZEV mode relative to the total distance of trip 2 Raw invalid=127; numeric DBC decoders may still scale it: check raw before use. Upstream default raw=0 (not necessarily valid data).";
CM_ SG_ 104 ZevDistancePercentTrip2Adjusted "DATABASE_CANDIDATE: physical interpretation unverified; capture/layout evidence reported separately. PSA-RE bits 4.3-5.5. Adjusted percentage of distance covered in ZEV mode for trip 2 Raw invalid=127; numeric DBC decoders may still scale it: check raw before use. Upstream default raw=0 (not necessarily valid data).";
CM_ SG_ 104 ZevDistancePercentTrip1 "DATABASE_CANDIDATE: physical interpretation unverified; capture/layout evidence reported separately. PSA-RE bits 3.2-4.4. Percentage of distance covered in ZEV mode relative to the total distance of trip 1 Raw invalid=127; numeric DBC decoders may still scale it: check raw before use. Upstream default raw=0 (not necessarily valid data).";
CM_ SG_ 104 ZevDistancePercentTrip1Adjusted "DATABASE_CANDIDATE: physical interpretation unverified; capture/layout evidence reported separately. PSA-RE bits 2.1-3.3. Adjusted percentage of distance covered in ZEV mode for trip 1 Raw invalid=127; numeric DBC decoders may still scale it: check raw before use. Upstream default raw=0 (not necessarily valid data).";
CM_ SG_ 104 ZevDistancePercentCurrentTrip "DATABASE_CANDIDATE: physical interpretation unverified; capture/layout evidence reported separately. PSA-RE bits 1.0-2.2. Percentage of distance covered in ZEV mode relative to the total distance of the current trip Raw invalid=127; numeric DBC decoders may still scale it: check raw before use. Upstream default raw=0 (not necessarily valid data).";
CM_ SG_ 104 ZevDistancePercentCurrent_fbe8bf "DATABASE_CANDIDATE: physical interpretation unverified; capture/layout evidence reported separately. PSA-RE bits 1.7-1.1. Adjusted percentage of distance covered in ZEV mode for the current trip Raw invalid=127; numeric DBC decoders may still scale it: check raw before use. Upstream default raw=0 (not necessarily valid data).";
CM_ BO_ 105 "DATABASE_CANDIDATE: physical interpretation unverified; capture/layout evidence reported separately. INFO-DIV CAN, 125000 bit/s; CAN ID 0x069. PSA-RE title: TELEMATICS_UNIT_STATUS. Telematics unit HMI status: audio switch and pop-up acknowledgements, user action, Wi-Fi settings update, main menu selection. Source: https://github.com/prototux/PSA-RE/blob/67f7581e7622410efdbb29c7eda3b86982b9b450/buses/AEE2010.full/LS.INFO-DIV/069.yml. Source sender alternatives: RAD,BTEL,OVIP,EMF; physical TX/gateway forwarding not verified. Observed 587 frames in info_apka.csv,info_buzeni_obc.csv,info_charging.csv,info_standby.csv,info_start_jizda.csv,infocan.csv; DLCs [5]. SOURCE_DLC_MISMATCH: source 2, observed/exported 5. Fitting fields retained; additional bytes raw. ";
CM_ SG_ 105 RawByte5 "RAW. PSA-RE bits 5.7-5.0. Unmapped/padding bits, no physical interpretation.";
CM_ SG_ 105 RawByte4 "RAW. PSA-RE bits 4.7-4.0. Unmapped/padding bits, no physical interpretation.";
CM_ SG_ 105 RawByte3 "RAW. PSA-RE bits 3.7-3.0. Unmapped/padding bits, no physical interpretation.";
CM_ SG_ 105 MainMenuSelection "DATABASE_CANDIDATE: physical interpretation unverified; capture/layout evidence reported separately. PSA-RE bits 2.2-2.0. Menu selected by the user Upstream default raw=7 (not necessarily valid data).";
CM_ SG_ 105 AudioSourceSwitchAck "DATABASE_CANDIDATE: physical interpretation unverified; capture/layout evidence reported separately. PSA-RE bits 2.3. Confirmation of the audio source switch requested by the VCP Upstream default raw=0 (not necessarily valid data).";
CM_ SG_ 105 WifiSettingsUpdateAck "DATABASE_CANDIDATE: physical interpretation unverified; capture/layout evidence reported separately. PSA-RE bits 2.4. Acknowledgement that Wi-Fi settings have been received Upstream default raw=0 (not necessarily valid data).";
CM_ SG_ 105 Unused1 "DATABASE_CANDIDATE: physical interpretation unverified; capture/layout evidence reported separately. PSA-RE bits 2.5. ";
CM_ SG_ 105 HmiUserAction "DATABASE_CANDIDATE: physical interpretation unverified; capture/layout evidence reported separately. PSA-RE bits 2.7-2.6. User action on the display Upstream default raw=0 (not necessarily valid data).";
CM_ SG_ 105 HmiPopupIdAck "DATABASE_CANDIDATE: physical interpretation unverified; capture/layout evidence reported separately. PSA-RE bits 1.7-1.0. Acknowledgement of the pop-up identifier to display Upstream default raw=0 (not necessarily valid data).";
CM_ BO_ 112 "DATABASE_CANDIDATE: physical interpretation unverified; capture/layout evidence reported separately. INFO-DIV CAN, 125000 bit/s; CAN ID 0x070. PSA-RE title: SDCM_ENCRYPTED_DATA_DOWN. Encrypted data sent by the smart door control module (SDCM) to the BSI. Source: https://github.com/prototux/PSA-RE/blob/67f7581e7622410efdbb29c7eda3b86982b9b450/buses/AEE2010.full/LS.INFO-DIV/070.yml. Source sender alternatives: SDCM; physical TX/gateway forwarding not verified. Observed 12 frames in info_standby.csv,info_start_jizda.csv,infocan.csv; DLCs [8]. ";
CM_ SG_ 112 SdcmToBsiCipheredOrder "DATABASE_CANDIDATE: physical interpretation unverified; capture/layout evidence reported separately. PSA-RE bits 1.7-8.0. Ciphered order sent from the SDCM to the BSI Source text/byte field exposed as raw integer; no string decoding.";
CM_ BO_ 115 "DATABASE_CANDIDATE: physical interpretation unverified; capture/layout evidence reported separately. INFO-DIV CAN, 125000 bit/s; CAN ID 0x073. PSA-RE title: SDCM_ENCRYPTED_DATA_UP. Encrypted data sent by the BSI to the smart door control module (SDCM). Source: https://github.com/prototux/PSA-RE/blob/67f7581e7622410efdbb29c7eda3b86982b9b450/buses/AEE2010.full/LS.INFO-DIV/073.yml. Source sender alternatives: BSI; physical TX/gateway forwarding not verified. Observed 3 frames in info_start_jizda.csv; DLCs [8]. ";
CM_ SG_ 115 CipheredOrderBsiToSdcm "DATABASE_CANDIDATE: physical interpretation unverified; capture/layout evidence reported separately. PSA-RE bits 1.7-8.0. Ciphered order sent from the BSI to the SDCM Source text/byte field exposed as raw integer; no string decoding.";
CM_ BO_ 125 "DATABASE_CANDIDATE: physical interpretation unverified; capture/layout evidence reported separately. INFO-DIV CAN, 125000 bit/s; CAN ID 0x07D. PSA-RE title: RANDOM_B_UPLINK_SDCM_BSI. Random authentication value (RAND B) sent from the SDCM to the BSI Source: https://github.com/prototux/PSA-RE/blob/67f7581e7622410efdbb29c7eda3b86982b9b450/buses/AEE2010.full/LS.INFO-DIV/07D.yml. Source sender alternatives: SDCM; physical TX/gateway forwarding not verified. Observed 4 frames in info_apka.csv,infocan.csv; DLCs [8]. ";
CM_ SG_ 125 SdcmToBsiCipherSyncB "DATABASE_CANDIDATE: physical interpretation unverified; capture/layout evidence reported separately. PSA-RE bits 1.7-8.0. Synchronization value for ciphered commands sent from the smart device module (SDCM) to the BSI";
CM_ BO_ 127 "DATABASE_CANDIDATE: physical interpretation unverified; capture/layout evidence reported separately. INFO-DIV CAN, 125000 bit/s; CAN ID 0x07F. PSA-RE title: RANDOM_B_DOWNLINK_BSI_SDCM. Random authentication value (RAND B) sent from the BSI to the SDCM Source: https://github.com/prototux/PSA-RE/blob/67f7581e7622410efdbb29c7eda3b86982b9b450/buses/AEE2010.full/LS.INFO-DIV/07F.yml. Source sender alternatives: BSI; physical TX/gateway forwarding not verified. Observed 4 frames in info_start_jizda.csv,infocan.csv; DLCs [8]. ";
CM_ SG_ 127 BsiToSdcmCipherSyncB "DATABASE_CANDIDATE: physical interpretation unverified; capture/layout evidence reported separately. PSA-RE bits 1.7-8.0. Synchronization value for ciphered commands sent from the BSI to the smart device module (SDCM)";
CM_ BO_ 141 "DATABASE_CANDIDATE: physical interpretation unverified; capture/layout evidence reported separately. INFO-DIV CAN, 125000 bit/s; CAN ID 0x08D. PSA-RE title: SDCM_AUTH_CHALLENGE_DOWN. Authentication random/response value sent from the SDCM to the BSI. Source: https://github.com/prototux/PSA-RE/blob/67f7581e7622410efdbb29c7eda3b86982b9b450/buses/AEE2010.full/LS.INFO-DIV/08D.yml. Source sender alternatives: SDCM; physical TX/gateway forwarding not verified. Observed 4 frames in info_start_jizda.csv,infocan.csv; DLCs [8]. ";
CM_ SG_ 141 SdcmToBsiCipherSync "DATABASE_CANDIDATE: physical interpretation unverified; capture/layout evidence reported separately. PSA-RE bits 1.7-8.0. Synchronization value for ciphered commands sent from the smart device module (SDCM) to the BSI Source text/byte field exposed as raw integer; no string decoding.";
CM_ BO_ 143 "DATABASE_CANDIDATE: physical interpretation unverified; capture/layout evidence reported separately. INFO-DIV CAN, 125000 bit/s; CAN ID 0x08F. PSA-RE title: SDCM_AUTH_CHALLENGE_UP. Authentication random/response value sent from the BSI to the SDCM. Source: https://github.com/prototux/PSA-RE/blob/67f7581e7622410efdbb29c7eda3b86982b9b450/buses/AEE2010.full/LS.INFO-DIV/08F.yml. Source sender alternatives: BSI; physical TX/gateway forwarding not verified. Observed 4 frames in info_apka.csv,infocan.csv; DLCs [8]. ";
CM_ SG_ 143 BsiToSdcmCipherSync "DATABASE_CANDIDATE: physical interpretation unverified; capture/layout evidence reported separately. PSA-RE bits 1.7-8.0. Synchronization value for ciphered commands sent from the BSI to the smart device module (SDCM) Source text/byte field exposed as raw integer; no string decoding.";
CM_ BO_ 159 "DATABASE_CANDIDATE: physical interpretation unverified; capture/layout evidence reported separately. INFO-DIV CAN, 125000 bit/s; CAN ID 0x09F. PSA-RE title: RADIO_TEXT_REPLY_FLOW_CONTROL. ISO-TP flow control frame for the radio text reply multi-frame reply (block size, flow status, separation time). Source: https://github.com/prototux/PSA-RE/blob/67f7581e7622410efdbb29c7eda3b86982b9b450/buses/AEE2010.full/LS.INFO-DIV/09F.yml. Source sender alternatives: EMF,ICSV; physical TX/gateway forwarding not verified. WIRE ISO-TP ONLY: normal addressing candidate, maximum Classical CAN DLC 8; actual DLC may be shorter. Data includes padding. No reassembly, text, DID or application-layer decoding. Original application layouts are preserved in source JSON; do not decode them at wire offsets. ";
CM_ SG_ 159 FlowPadding5 "TRANSPORT_CANDIDATE: normal-addressing ISO-TP. PSA-RE bits 8.7-8.0. ";
CM_ SG_ 159 FirstData6 "TRANSPORT_CANDIDATE: normal-addressing ISO-TP. PSA-RE bits 8.7-8.0. ";
CM_ SG_ 159 UnknownData7 "TRANSPORT_CANDIDATE: normal-addressing ISO-TP. PSA-RE bits 8.7-8.0. ";
CM_ SG_ 159 ConsecutiveData7 "TRANSPORT_CANDIDATE: normal-addressing ISO-TP. PSA-RE bits 8.7-8.0. ";
CM_ SG_ 159 SingleData7 "TRANSPORT_CANDIDATE: normal-addressing ISO-TP. PSA-RE bits 8.7-8.0. ";
CM_ SG_ 159 FlowPadding4 "TRANSPORT_CANDIDATE: normal-addressing ISO-TP. PSA-RE bits 7.7-7.0. ";
CM_ SG_ 159 FirstData5 "TRANSPORT_CANDIDATE: normal-addressing ISO-TP. PSA-RE bits 7.7-7.0. ";
CM_ SG_ 159 UnknownData6 "TRANSPORT_CANDIDATE: normal-addressing ISO-TP. PSA-RE bits 7.7-7.0. ";
CM_ SG_ 159 ConsecutiveData6 "TRANSPORT_CANDIDATE: normal-addressing ISO-TP. PSA-RE bits 7.7-7.0. ";
CM_ SG_ 159 SingleData6 "TRANSPORT_CANDIDATE: normal-addressing ISO-TP. PSA-RE bits 7.7-7.0. ";
CM_ SG_ 159 FlowPadding3 "TRANSPORT_CANDIDATE: normal-addressing ISO-TP. PSA-RE bits 6.7-6.0. ";
CM_ SG_ 159 FirstData4 "TRANSPORT_CANDIDATE: normal-addressing ISO-TP. PSA-RE bits 6.7-6.0. ";
CM_ SG_ 159 UnknownData5 "TRANSPORT_CANDIDATE: normal-addressing ISO-TP. PSA-RE bits 6.7-6.0. ";
CM_ SG_ 159 ConsecutiveData5 "TRANSPORT_CANDIDATE: normal-addressing ISO-TP. PSA-RE bits 6.7-6.0. ";
CM_ SG_ 159 SingleData5 "TRANSPORT_CANDIDATE: normal-addressing ISO-TP. PSA-RE bits 6.7-6.0. ";
CM_ SG_ 159 FlowPadding2 "TRANSPORT_CANDIDATE: normal-addressing ISO-TP. PSA-RE bits 5.7-5.0. ";
CM_ SG_ 159 FirstData3 "TRANSPORT_CANDIDATE: normal-addressing ISO-TP. PSA-RE bits 5.7-5.0. ";
CM_ SG_ 159 UnknownData4 "TRANSPORT_CANDIDATE: normal-addressing ISO-TP. PSA-RE bits 5.7-5.0. ";
CM_ SG_ 159 ConsecutiveData4 "TRANSPORT_CANDIDATE: normal-addressing ISO-TP. PSA-RE bits 5.7-5.0. ";
CM_ SG_ 159 SingleData4 "TRANSPORT_CANDIDATE: normal-addressing ISO-TP. PSA-RE bits 5.7-5.0. ";
CM_ SG_ 159 FlowPadding1 "TRANSPORT_CANDIDATE: normal-addressing ISO-TP. PSA-RE bits 4.7-4.0. ";
CM_ SG_ 159 FirstData2 "TRANSPORT_CANDIDATE: normal-addressing ISO-TP. PSA-RE bits 4.7-4.0. ";
CM_ SG_ 159 UnknownData3 "TRANSPORT_CANDIDATE: normal-addressing ISO-TP. PSA-RE bits 4.7-4.0. ";
CM_ SG_ 159 ConsecutiveData3 "TRANSPORT_CANDIDATE: normal-addressing ISO-TP. PSA-RE bits 4.7-4.0. ";
CM_ SG_ 159 SingleData3 "TRANSPORT_CANDIDATE: normal-addressing ISO-TP. PSA-RE bits 4.7-4.0. ";
CM_ SG_ 159 FirstData1 "TRANSPORT_CANDIDATE: normal-addressing ISO-TP. PSA-RE bits 3.7-3.0. ";
CM_ SG_ 159 UnknownData2 "TRANSPORT_CANDIDATE: normal-addressing ISO-TP. PSA-RE bits 3.7-3.0. ";
CM_ SG_ 159 ConsecutiveData2 "TRANSPORT_CANDIDATE: normal-addressing ISO-TP. PSA-RE bits 3.7-3.0. ";
CM_ SG_ 159 SingleData2 "TRANSPORT_CANDIDATE: normal-addressing ISO-TP. PSA-RE bits 3.7-3.0. ";
CM_ SG_ 159 SeparationTimeRaw "TRANSPORT_CANDIDATE: normal-addressing ISO-TP. PSA-RE bits 3.7-3.0. Raw STmin code; 0xF1..0xF9 are not milliseconds.";
CM_ SG_ 159 UnknownData1 "TRANSPORT_CANDIDATE: normal-addressing ISO-TP. PSA-RE bits 2.7-2.0. ";
CM_ SG_ 159 ConsecutiveData1 "TRANSPORT_CANDIDATE: normal-addressing ISO-TP. PSA-RE bits 2.7-2.0. ";
CM_ SG_ 159 SingleData1 "TRANSPORT_CANDIDATE: normal-addressing ISO-TP. PSA-RE bits 2.7-2.0. ";
CM_ SG_ 159 BlockSize "TRANSPORT_CANDIDATE: normal-addressing ISO-TP. PSA-RE bits 2.7-2.0. ";
CM_ SG_ 159 UnknownPciLow "TRANSPORT_CANDIDATE: normal-addressing ISO-TP. PSA-RE bits 1.3-1.0. ";
CM_ SG_ 159 FlowStatus "TRANSPORT_CANDIDATE: normal-addressing ISO-TP. PSA-RE bits 1.3-1.0. ";
CM_ SG_ 159 ConsecutiveSequence "TRANSPORT_CANDIDATE: normal-addressing ISO-TP. PSA-RE bits 1.3-1.0. ";
CM_ SG_ 159 FirstFrameLength "TRANSPORT_CANDIDATE: normal-addressing ISO-TP. PSA-RE bits 1.3-2.0. 12-bit declared PDU length; not a reassembled value.";
CM_ SG_ 159 SingleFrameLength "TRANSPORT_CANDIDATE: normal-addressing ISO-TP. PSA-RE bits 1.3-1.0. Declared data length; not a validity check.";
CM_ SG_ 159 IsoTpFrameType "TRANSPORT_CANDIDATE: normal-addressing ISO-TP. PSA-RE bits 1.7-1.4. PCI high nibble; normal addressing candidate.";
CM_ BO_ 161 "DATABASE_CANDIDATE: physical interpretation unverified; capture/layout evidence reported separately. INFO-DIV CAN, 125000 bit/s; CAN ID 0x0A1. PSA-RE title: AUTOMATED_PARKING_STATUS. Automated parking (ACPK) status: brake pedal, manoeuvre direction/side/state/type, menu, neutral-gear request, overshoot progress, speed-too-high warning and HMI display request. Source: https://github.com/prototux/PSA-RE/blob/67f7581e7622410efdbb29c7eda3b86982b9b450/buses/AEE2010.full/LS.INFO-DIV/0A1.yml. Source sender alternatives: AAS; physical TX/gateway forwarding not verified. ";
CM_ SG_ 161 Unused4 "DATABASE_CANDIDATE: physical interpretation unverified; capture/layout evidence reported separately. PSA-RE bits 8.0. ";
CM_ SG_ 161 AcpkVehicleTooFast "DATABASE_CANDIDATE: physical interpretation unverified; capture/layout evidence reported separately. PSA-RE bits 8.1. Vehicle speed state during the ACPK manoeuvre, for the HMI Upstream default raw=0 (not necessarily valid data).";
CM_ SG_ 161 AcpkGearboxNeutralStatus "DATABASE_CANDIDATE: physical interpretation unverified; capture/layout evidence reported separately. PSA-RE bits 8.2. Automatic gearbox position state for the ACPK HMI Upstream default raw=0 (not necessarily valid data).";
CM_ SG_ 161 AcpkManeuverSide "DATABASE_CANDIDATE: physical interpretation unverified; capture/layout evidence reported separately. PSA-RE bits 8.3. Side of the ACPK parking manoeuvre for the HMI Upstream default raw=0 (not necessarily valid data).";
CM_ SG_ 161 AcpkManeuverState "DATABASE_CANDIDATE: physical interpretation unverified; capture/layout evidence reported separately. PSA-RE bits 8.7-8.4. ACPK function state during the manoeuvre for the HMI Upstream default raw=0 (not necessarily valid data).";
CM_ SG_ 161 AcpkPreparationProgress "DATABASE_CANDIDATE: physical interpretation unverified; capture/layout evidence reported separately. PSA-RE bits 7.3-7.0. Vehicle position while preparing the ACPK manoeuvre, for the HMI Upstream default raw=0 (not necessarily valid data).";
CM_ SG_ 161 AcpkPreparationState "DATABASE_CANDIDATE: physical interpretation unverified; capture/layout evidence reported separately. PSA-RE bits 7.7-7.4. ACPK function state while preparing the manoeuvre, for the HMI Upstream default raw=0 (not necessarily valid data).";
CM_ SG_ 161 AcpkBrakePedalStatus "DATABASE_CANDIDATE: physical interpretation unverified; capture/layout evidence reported separately. PSA-RE bits 6.0. Brake pedal status for the ACPK HMI Upstream default raw=0 (not necessarily valid data).";
CM_ SG_ 161 AcpkManeuverDirection "DATABASE_CANDIDATE: physical interpretation unverified; capture/layout evidence reported separately. PSA-RE bits 6.2-6.1. Direction of the ACPK manoeuvre for the HMI Upstream default raw=0 (not necessarily valid data).";
CM_ SG_ 161 AcpkManeuverType "DATABASE_CANDIDATE: physical interpretation unverified; capture/layout evidence reported separately. PSA-RE bits 6.4-6.3. Type of ACPK manoeuvre for the HMI Upstream default raw=0 (not necessarily valid data).";
CM_ SG_ 161 FrontLeftCenterObstacleDistance "DATABASE_CANDIDATE: physical interpretation unverified; capture/layout evidence reported separately. PSA-RE bits 6.7-6.5. Distance to the front left-center obstacle (ultrasound park assist) Upstream default raw=7 (not necessarily valid data).";
CM_ SG_ 161 Unused3 "DATABASE_CANDIDATE: physical interpretation unverified; capture/layout evidence reported separately. PSA-RE bits 5.0. ";
CM_ SG_ 161 FrontRightCenterObstacleDistance "DATABASE_CANDIDATE: physical interpretation unverified; capture/layout evidence reported separately. PSA-RE bits 5.3-5.1. Distance to the front right-center obstacle (ultrasound park assist) Upstream default raw=7 (not necessarily valid data).";
CM_ SG_ 161 RearLeftCenterObstacleDistance "DATABASE_CANDIDATE: physical interpretation unverified; capture/layout evidence reported separately. PSA-RE bits 5.7-5.4. Distance to the rear left-center obstacle (ultrasound park assist) Upstream default raw=9 (not necessarily valid data).";
CM_ SG_ 161 RearRightCenterObstacleDistance "DATABASE_CANDIDATE: physical interpretation unverified; capture/layout evidence reported separately. PSA-RE bits 4.3-4.0. Distance to the rear right-center obstacle (ultrasound park assist) Upstream default raw=9 (not necessarily valid data).";
CM_ SG_ 161 FrontRightLateralObstacle_ef9eb7 "DATABASE_CANDIDATE: physical interpretation unverified; capture/layout evidence reported separately. PSA-RE bits 4.5-4.4. Front right lateral obstacle distance (ultrasound park assist display) Upstream default raw=3 (not necessarily valid data).";
CM_ SG_ 161 CenterRightLateralObstacl_127351 "DATABASE_CANDIDATE: physical interpretation unverified; capture/layout evidence reported separately. PSA-RE bits 4.7-4.6. Center right lateral obstacle distance (ultrasound park assist display) Upstream default raw=3 (not necessarily valid data).";
CM_ SG_ 161 RearRightLateralObstacleDistance "DATABASE_CANDIDATE: physical interpretation unverified; capture/layout evidence reported separately. PSA-RE bits 3.1-3.0. Rear right lateral obstacle distance (ultrasound park assist display) Upstream default raw=3 (not necessarily valid data).";
CM_ SG_ 161 FrontLeftLateralObstacleDistance "DATABASE_CANDIDATE: physical interpretation unverified; capture/layout evidence reported separately. PSA-RE bits 3.3-3.2. Front left lateral obstacle distance (ultrasound park assist display) Upstream default raw=3 (not necessarily valid data).";
CM_ SG_ 161 CenterLeftLateralObstacle_db978a "DATABASE_CANDIDATE: physical interpretation unverified; capture/layout evidence reported separately. PSA-RE bits 3.5-3.4. Center left lateral obstacle distance (ultrasound park assist display) Upstream default raw=3 (not necessarily valid data).";
CM_ SG_ 161 RearLeftLateralObstacleDistance "DATABASE_CANDIDATE: physical interpretation unverified; capture/layout evidence reported separately. PSA-RE bits 3.7-3.6. Rear left lateral obstacle distance (ultrasound park assist display) Upstream default raw=3 (not necessarily valid data).";
CM_ SG_ 161 SamActivityStatus "DATABASE_CANDIDATE: physical interpretation unverified; capture/layout evidence reported separately. PSA-RE bits 2.2-2.0. SAM activity status Upstream default raw=0 (not necessarily valid data).";
CM_ SG_ 161 SamLedRequest "DATABASE_CANDIDATE: physical interpretation unverified; capture/layout evidence reported separately. PSA-RE bits 2.4-2.3. SAM LED lighting type request Upstream default raw=0 (not necessarily valid data).";
CM_ SG_ 161 SamRightObjectPresent "DATABASE_CANDIDATE: physical interpretation unverified; capture/layout evidence reported separately. PSA-RE bits 2.5. Object present in the right-hand SAM zone Upstream default raw=0 (not necessarily valid data).";
CM_ SG_ 161 SamLeftObjectPresent "DATABASE_CANDIDATE: physical interpretation unverified; capture/layout evidence reported separately. PSA-RE bits 2.6. Object present in the left-hand SAM zone Upstream default raw=0 (not necessarily valid data).";
CM_ SG_ 161 Unused2 "DATABASE_CANDIDATE: physical interpretation unverified; capture/layout evidence reported separately. PSA-RE bits 2.7. ";
CM_ SG_ 161 Unused1 "DATABASE_CANDIDATE: physical interpretation unverified; capture/layout evidence reported separately. PSA-RE bits 1.3-1.0. ";
CM_ SG_ 161 CityParkHmiRequest "DATABASE_CANDIDATE: physical interpretation unverified; capture/layout evidence reported separately. PSA-RE bits 1.7-1.4. City park HMI request Upstream default raw=0 (not necessarily valid data).";
CM_ BO_ 162 "DATABASE_CANDIDATE: physical interpretation unverified; capture/layout evidence reported separately. INFO-DIV CAN, 125000 bit/s; CAN ID 0x0A2. PSA-RE title: STEERING_WHEEL_COMMANDS. Steering wheel control buttons, used by the radio, CMB, EMF and BTEL. Source: https://github.com/prototux/PSA-RE/blob/67f7581e7622410efdbb29c7eda3b86982b9b450/buses/AEE2010.full/LS.INFO-DIV/0A2.yml. Source sender alternatives: BSI,ICSV; physical TX/gateway forwarding not verified. Observed 5858 frames in info_apka.csv,info_buzeni_obc.csv,info_charging.csv,info_standby.csv,info_start_jizda.csv,infocan.csv; DLCs [6]. ";
CM_ SG_ 162 SteeringWheelVolumeCounter "DATABASE_CANDIDATE: physical interpretation unverified; capture/layout evidence reported separately. PSA-RE bits 6.7-6.0. Steering wheel volume control counter. Upstream default raw=0 (not necessarily valid data).";
CM_ SG_ 162 VolumeKnobScrollUnderflow "DATABASE_CANDIDATE: physical interpretation unverified; capture/layout evidence reported separately. PSA-RE bits 5.0. Low overflow (underflow) of the volume knob Upstream default raw=0 (not necessarily valid data).";
CM_ SG_ 162 VolumeKnobScrollOverflow "DATABASE_CANDIDATE: physical interpretation unverified; capture/layout evidence reported separately. PSA-RE bits 5.1. High overflow of the volume knob Upstream default raw=0 (not necessarily valid data).";
CM_ SG_ 162 Unused2 "DATABASE_CANDIDATE: physical interpretation unverified; capture/layout evidence reported separately. PSA-RE bits 5.2. ";
CM_ SG_ 162 RecyclAirEtVmf "DATABASE_CANDIDATE: physical interpretation unverified; capture/layout evidence reported separately. PSA-RE bits 5.3. Air conditioning air recycling flap command Upstream default raw=0 (not necessarily valid data).";
CM_ SG_ 162 CmbEscapeButton "DATABASE_CANDIDATE: physical interpretation unverified; capture/layout evidence reported separately. PSA-RE bits 5.4. Instrument cluster (CMB) designator escape key. Upstream default raw=0 (not necessarily valid data).";
CM_ SG_ 162 CmbValidationButton "DATABASE_CANDIDATE: physical interpretation unverified; capture/layout evidence reported separately. PSA-RE bits 5.5. Validation button (instrument cluster) Upstream default raw=0 (not necessarily valid data).";
CM_ SG_ 162 CmbNavMenuScrollUnderflow "DATABASE_CANDIDATE: physical interpretation unverified; capture/layout evidence reported separately. PSA-RE bits 5.6. Low overflow (underflow) of the instrument cluster navigation scroll wheel Upstream default raw=0 (not necessarily valid data).";
CM_ SG_ 162 CmbNavMenuScrollOverflow "DATABASE_CANDIDATE: physical interpretation unverified; capture/layout evidence reported separately. PSA-RE bits 5.7. High overflow of the instrument cluster navigation scroll wheel Upstream default raw=0 (not necessarily valid data).";
CM_ SG_ 162 CmbNavMenuCounter "DATABASE_CANDIDATE: physical interpretation unverified; capture/layout evidence reported separately. PSA-RE bits 4.7-4.0. Instrument cluster (CMB) navigation menu scroll counter. Upstream default raw=0 (not necessarily valid data).";
CM_ SG_ 162 Unused1 "DATABASE_CANDIDATE: physical interpretation unverified; capture/layout evidence reported separately. PSA-RE bits 3.6-3.0. ";
CM_ SG_ 162 SteeringWheelTelephoneCommand "DATABASE_CANDIDATE: physical interpretation unverified; capture/layout evidence reported separately. PSA-RE bits 3.7. Access to the hands-free kit (KML) phone directory. Upstream default raw=0 (not necessarily valid data).";
CM_ SG_ 162 SteeringWheelVoiceCommand "DATABASE_CANDIDATE: physical interpretation unverified; capture/layout evidence reported separately. PSA-RE bits 2.0. Voice command button on the steering wheel Upstream default raw=0 (not necessarily valid data).";
CM_ SG_ 162 SteeringWheelLeftPush "DATABASE_CANDIDATE: physical interpretation unverified; capture/layout evidence reported separately. PSA-RE bits 2.1. Left push button Upstream default raw=0 (not necessarily valid data).";
CM_ SG_ 162 SteeringWheelModeButton "DATABASE_CANDIDATE: physical interpretation unverified; capture/layout evidence reported separately. PSA-RE bits 2.2. Mode button (steering wheel remote) Upstream default raw=0 (not necessarily valid data).";
CM_ SG_ 162 SteeringWheelMenuButton "DATABASE_CANDIDATE: physical interpretation unverified; capture/layout evidence reported separately. PSA-RE bits 2.3. Menu button (steering wheel remote) Upstream default raw=0 (not necessarily valid data).";
CM_ SG_ 162 SteeringWheelEscapeButton "DATABASE_CANDIDATE: physical interpretation unverified; capture/layout evidence reported separately. PSA-RE bits 2.4. Steering wheel designator escape key. Upstream default raw=0 (not necessarily valid data).";
CM_ SG_ 162 SteeringWheelValidationButton "DATABASE_CANDIDATE: physical interpretation unverified; capture/layout evidence reported separately. PSA-RE bits 2.5. Validation button (steering wheel remote) Upstream default raw=0 (not necessarily valid data).";
CM_ SG_ 162 SteeringWheelNavMenuScrol_49cbf8 "DATABASE_CANDIDATE: physical interpretation unverified; capture/layout evidence reported separately. PSA-RE bits 2.6. Low overflow (underflow) of the steering wheel navigation scroll wheel Upstream default raw=0 (not necessarily valid data).";
CM_ SG_ 162 SteeringWheelNavMenuScrol_3fd970 "DATABASE_CANDIDATE: physical interpretation unverified; capture/layout evidence reported separately. PSA-RE bits 2.7. High overflow of the steering wheel navigation scroll wheel Upstream default raw=0 (not necessarily valid data).";
CM_ SG_ 162 SteeringWheelNavMenuScroll "DATABASE_CANDIDATE: physical interpretation unverified; capture/layout evidence reported separately. PSA-RE bits 1.7-1.0. Steering wheel navigation menu scroll counter. Upstream default raw=0 (not necessarily valid data).";
CM_ BO_ 164 "DATABASE_CANDIDATE: physical interpretation unverified; capture/layout evidence reported separately. INFO-DIV CAN, 125000 bit/s; CAN ID 0x0A4. PSA-RE title: RADIO_TEXT_REPLY_PAYLOAD. Multi-frame reply payload with text to display (radio or CD source), 2 to 8 bytes. Source: https://github.com/prototux/PSA-RE/blob/67f7581e7622410efdbb29c7eda3b86982b9b450/buses/AEE2010.full/LS.INFO-DIV/0A4.yml. Source sender alternatives: RAD,ICSV; physical TX/gateway forwarding not verified. WIRE ISO-TP ONLY: normal addressing candidate, maximum Classical CAN DLC 8; actual DLC may be shorter. Data includes padding. No reassembly, text, DID or application-layer decoding. Original application layouts are preserved in source JSON; do not decode them at wire offsets. Unresolved alternative source layouts preserved in source JSON. ";
CM_ SG_ 164 FlowPadding5 "TRANSPORT_CANDIDATE: normal-addressing ISO-TP. PSA-RE bits 8.7-8.0. ";
CM_ SG_ 164 FirstData6 "TRANSPORT_CANDIDATE: normal-addressing ISO-TP. PSA-RE bits 8.7-8.0. ";
CM_ SG_ 164 UnknownData7 "TRANSPORT_CANDIDATE: normal-addressing ISO-TP. PSA-RE bits 8.7-8.0. ";
CM_ SG_ 164 ConsecutiveData7 "TRANSPORT_CANDIDATE: normal-addressing ISO-TP. PSA-RE bits 8.7-8.0. ";
CM_ SG_ 164 SingleData7 "TRANSPORT_CANDIDATE: normal-addressing ISO-TP. PSA-RE bits 8.7-8.0. ";
CM_ SG_ 164 FlowPadding4 "TRANSPORT_CANDIDATE: normal-addressing ISO-TP. PSA-RE bits 7.7-7.0. ";
CM_ SG_ 164 FirstData5 "TRANSPORT_CANDIDATE: normal-addressing ISO-TP. PSA-RE bits 7.7-7.0. ";
CM_ SG_ 164 UnknownData6 "TRANSPORT_CANDIDATE: normal-addressing ISO-TP. PSA-RE bits 7.7-7.0. ";
CM_ SG_ 164 ConsecutiveData6 "TRANSPORT_CANDIDATE: normal-addressing ISO-TP. PSA-RE bits 7.7-7.0. ";
CM_ SG_ 164 SingleData6 "TRANSPORT_CANDIDATE: normal-addressing ISO-TP. PSA-RE bits 7.7-7.0. ";
CM_ SG_ 164 FlowPadding3 "TRANSPORT_CANDIDATE: normal-addressing ISO-TP. PSA-RE bits 6.7-6.0. ";
CM_ SG_ 164 FirstData4 "TRANSPORT_CANDIDATE: normal-addressing ISO-TP. PSA-RE bits 6.7-6.0. ";
CM_ SG_ 164 UnknownData5 "TRANSPORT_CANDIDATE: normal-addressing ISO-TP. PSA-RE bits 6.7-6.0. ";
CM_ SG_ 164 ConsecutiveData5 "TRANSPORT_CANDIDATE: normal-addressing ISO-TP. PSA-RE bits 6.7-6.0. ";
CM_ SG_ 164 SingleData5 "TRANSPORT_CANDIDATE: normal-addressing ISO-TP. PSA-RE bits 6.7-6.0. ";
CM_ SG_ 164 FlowPadding2 "TRANSPORT_CANDIDATE: normal-addressing ISO-TP. PSA-RE bits 5.7-5.0. ";
CM_ SG_ 164 FirstData3 "TRANSPORT_CANDIDATE: normal-addressing ISO-TP. PSA-RE bits 5.7-5.0. ";
CM_ SG_ 164 UnknownData4 "TRANSPORT_CANDIDATE: normal-addressing ISO-TP. PSA-RE bits 5.7-5.0. ";
CM_ SG_ 164 ConsecutiveData4 "TRANSPORT_CANDIDATE: normal-addressing ISO-TP. PSA-RE bits 5.7-5.0. ";
CM_ SG_ 164 SingleData4 "TRANSPORT_CANDIDATE: normal-addressing ISO-TP. PSA-RE bits 5.7-5.0. ";
CM_ SG_ 164 FlowPadding1 "TRANSPORT_CANDIDATE: normal-addressing ISO-TP. PSA-RE bits 4.7-4.0. ";
CM_ SG_ 164 FirstData2 "TRANSPORT_CANDIDATE: normal-addressing ISO-TP. PSA-RE bits 4.7-4.0. ";
CM_ SG_ 164 UnknownData3 "TRANSPORT_CANDIDATE: normal-addressing ISO-TP. PSA-RE bits 4.7-4.0. ";
CM_ SG_ 164 ConsecutiveData3 "TRANSPORT_CANDIDATE: normal-addressing ISO-TP. PSA-RE bits 4.7-4.0. ";
CM_ SG_ 164 SingleData3 "TRANSPORT_CANDIDATE: normal-addressing ISO-TP. PSA-RE bits 4.7-4.0. ";
CM_ SG_ 164 FirstData1 "TRANSPORT_CANDIDATE: normal-addressing ISO-TP. PSA-RE bits 3.7-3.0. ";
CM_ SG_ 164 UnknownData2 "TRANSPORT_CANDIDATE: normal-addressing ISO-TP. PSA-RE bits 3.7-3.0. ";
CM_ SG_ 164 ConsecutiveData2 "TRANSPORT_CANDIDATE: normal-addressing ISO-TP. PSA-RE bits 3.7-3.0. ";
CM_ SG_ 164 SingleData2 "TRANSPORT_CANDIDATE: normal-addressing ISO-TP. PSA-RE bits 3.7-3.0. ";
CM_ SG_ 164 SeparationTimeRaw "TRANSPORT_CANDIDATE: normal-addressing ISO-TP. PSA-RE bits 3.7-3.0. Raw STmin code; 0xF1..0xF9 are not milliseconds.";
CM_ SG_ 164 UnknownData1 "TRANSPORT_CANDIDATE: normal-addressing ISO-TP. PSA-RE bits 2.7-2.0. ";
CM_ SG_ 164 ConsecutiveData1 "TRANSPORT_CANDIDATE: normal-addressing ISO-TP. PSA-RE bits 2.7-2.0. ";
CM_ SG_ 164 SingleData1 "TRANSPORT_CANDIDATE: normal-addressing ISO-TP. PSA-RE bits 2.7-2.0. ";
CM_ SG_ 164 BlockSize "TRANSPORT_CANDIDATE: normal-addressing ISO-TP. PSA-RE bits 2.7-2.0. ";
CM_ SG_ 164 UnknownPciLow "TRANSPORT_CANDIDATE: normal-addressing ISO-TP. PSA-RE bits 1.3-1.0. ";
CM_ SG_ 164 FlowStatus "TRANSPORT_CANDIDATE: normal-addressing ISO-TP. PSA-RE bits 1.3-1.0. ";
CM_ SG_ 164 ConsecutiveSequence "TRANSPORT_CANDIDATE: normal-addressing ISO-TP. PSA-RE bits 1.3-1.0. ";
CM_ SG_ 164 FirstFrameLength "TRANSPORT_CANDIDATE: normal-addressing ISO-TP. PSA-RE bits 1.3-2.0. 12-bit declared PDU length; not a reassembled value.";
CM_ SG_ 164 SingleFrameLength "TRANSPORT_CANDIDATE: normal-addressing ISO-TP. PSA-RE bits 1.3-1.0. Declared data length; not a validity check.";
CM_ SG_ 164 IsoTpFrameType "TRANSPORT_CANDIDATE: normal-addressing ISO-TP. PSA-RE bits 1.7-1.4. PCI high nibble; normal addressing candidate.";
CM_ BO_ 165 "DATABASE_CANDIDATE: physical interpretation unverified; capture/layout evidence reported separately. INFO-DIV CAN, 125000 bit/s; CAN ID 0x0A5. PSA-RE title: MULTIPLEXED_BUTTONS_STATUS. Multiplexed push-button status: parking aid and Stop & Start button inputs. Source: https://github.com/prototux/PSA-RE/blob/67f7581e7622410efdbb29c7eda3b86982b9b450/buses/AEE2010.full/LS.INFO-DIV/0A5.yml. Source sender alternatives: FMUX; physical TX/gateway forwarding not verified. ";
CM_ SG_ 165 Unused1 "DATABASE_CANDIDATE: physical interpretation unverified; capture/layout evidence reported separately. PSA-RE bits 1.5-1.0. ";
CM_ SG_ 165 SttButtonStatus "DATABASE_CANDIDATE: physical interpretation unverified; capture/layout evidence reported separately. PSA-RE bits 1.6. Stop & Start push-button input Upstream default raw=0 (not necessarily valid data).";
CM_ SG_ 165 AasButtonStatus "DATABASE_CANDIDATE: physical interpretation unverified; capture/layout evidence reported separately. PSA-RE bits 1.7. Parking sensor (AAS) push-button input Upstream default raw=0 (not necessarily valid data).";
CM_ BO_ 166 "DATABASE_CANDIDATE: physical interpretation unverified; capture/layout evidence reported separately. INFO-DIV CAN, 125000 bit/s; CAN ID 0x0A6. PSA-RE title: WHEEL_PULSE_COUNTERS. Wheel speed pulse counters and their fault status for all four wheels, relayed by the body computer (BSI). Source: https://github.com/prototux/PSA-RE/blob/67f7581e7622410efdbb29c7eda3b86982b9b450/buses/AEE2010.full/LS.INFO-DIV/0A6.yml. Source sender alternatives: BSI; physical TX/gateway forwarding not verified. ";
CM_ SG_ 166 RearRightWheelPulseCounter "DATABASE_CANDIDATE: physical interpretation unverified; capture/layout evidence reported separately. PSA-RE bits 6.2-7.0. Rear right wheel pulse counter (96 pulses/rev)";
CM_ SG_ 166 RearRightWheelPulseCounterFault "DATABASE_CANDIDATE: physical interpretation unverified; capture/layout evidence reported separately. PSA-RE bits 6.3. Rear right wheel pulse counter fault";
CM_ SG_ 166 RearLeftWheelPulseCounter "DATABASE_CANDIDATE: physical interpretation unverified; capture/layout evidence reported separately. PSA-RE bits 5.6-6.4. Rear left wheel pulse counter (96 pulses/rev)";
CM_ SG_ 166 RearLeftWheelPulseCounterFault "DATABASE_CANDIDATE: physical interpretation unverified; capture/layout evidence reported separately. PSA-RE bits 5.7. Rear left wheel pulse counter fault";
CM_ SG_ 166 FrontRightWheelPulseCounter "DATABASE_CANDIDATE: physical interpretation unverified; capture/layout evidence reported separately. PSA-RE bits 3.2-4.0. Front right wheel pulse counter (96 pulses/rev)";
CM_ SG_ 166 FrontRightWheelPulseCounterFault "DATABASE_CANDIDATE: physical interpretation unverified; capture/layout evidence reported separately. PSA-RE bits 3.3. Front right wheel pulse counter fault";
CM_ SG_ 166 FrontLeftWheelPulseCounter "DATABASE_CANDIDATE: physical interpretation unverified; capture/layout evidence reported separately. PSA-RE bits 2.6-3.4. Front left wheel pulse counter (96 pulses/rev)";
CM_ SG_ 166 FrontLeftWheelPulseCounterFault "DATABASE_CANDIDATE: physical interpretation unverified; capture/layout evidence reported separately. PSA-RE bits 2.7. Front left wheel pulse counter fault";
CM_ SG_ 166 ProcessCounter "DATABASE_CANDIDATE: physical interpretation unverified; capture/layout evidence reported separately. PSA-RE bits 1.3-1.0. 4-bit process counter";
CM_ SG_ 166 RawBits0_3 "RAW. PSA-RE bits 1.7-1.4. Unmapped/padding bits, no physical interpretation.";
CM_ BO_ 168 "DATABASE_CANDIDATE: physical interpretation unverified; capture/layout evidence reported separately. INFO-DIV CAN, 125000 bit/s; CAN ID 0x0A8. PSA-RE title: IMMO_RESPONSE. Powertrain dynamic data: instantaneous and percentage lateral and longitudinal acceleration, plus telemetry power display request. Source: https://github.com/prototux/PSA-RE/blob/67f7581e7622410efdbb29c7eda3b86982b9b450/buses/AEE2010.full/LS.INFO-DIV/0A8.yml. Source sender alternatives: BSI; physical TX/gateway forwarding not verified. Observed 2936 frames in info_apka.csv,info_buzeni_obc.csv,info_charging.csv,info_standby.csv,info_start_jizda.csv,infocan.csv; DLCs [4]. SOURCE_DLC_MISMATCH: source 6, observed/exported 4. Fitting fields retained; additional bytes raw. ";
CM_ SG_ 168 Unused3 "DATABASE_CANDIDATE: physical interpretation unverified; capture/layout evidence reported separately. PSA-RE bits 4.2-4.0. ";
CM_ SG_ 168 LongitudinalAccelerationInstant "DATABASE_CANDIDATE: physical interpretation unverified; capture/layout evidence reported separately. PSA-RE bits 4.7-4.3. HMI instantaneous longitudinal acceleration value Upstream default raw=0 (not necessarily valid data).";
CM_ SG_ 168 Unused2 "DATABASE_CANDIDATE: physical interpretation unverified; capture/layout evidence reported separately. PSA-RE bits 3.0. ";
CM_ SG_ 168 LateralAccelerationPercent "DATABASE_CANDIDATE: physical interpretation unverified; capture/layout evidence reported separately. PSA-RE bits 3.7-3.1. Lateral acceleration percentage Raw invalid=127; numeric DBC decoders may still scale it: check raw before use. Upstream default raw=0 (not necessarily valid data).";
CM_ SG_ 168 TelemetryPageStartRequest "DATABASE_CANDIDATE: physical interpretation unverified; capture/layout evidence reported separately. PSA-RE bits 2.0. Telemetry page start request (dynamic mode active) Upstream default raw=0 (not necessarily valid data).";
CM_ SG_ 168 LongitudinalAccelerationPercent "DATABASE_CANDIDATE: physical interpretation unverified; capture/layout evidence reported separately. PSA-RE bits 2.7-2.1. Longitudinal acceleration percentage Raw invalid=127; numeric DBC decoders may still scale it: check raw before use. Upstream default raw=0 (not necessarily valid data). Unresolved source alternatives: [{\"note\": \"Also observed at bits 2.7-2.3\", \"bits\": \"2.7-2.3\"}]";
CM_ SG_ 168 Unused1 "DATABASE_CANDIDATE: physical interpretation unverified; capture/layout evidence reported separately. PSA-RE bits 1.2-1.0. ";
CM_ SG_ 168 LateralAccelerationInstant "DATABASE_CANDIDATE: physical interpretation unverified; capture/layout evidence reported separately. PSA-RE bits 1.7-1.3. HMI instantaneous lateral acceleration value Upstream default raw=0 (not necessarily valid data).";
CM_ BO_ 169 "DATABASE_CANDIDATE: physical interpretation unverified; capture/layout evidence reported separately. INFO-DIV CAN, 125000 bit/s; CAN ID 0x0A9. PSA-RE title: IMMOBILIZER_SEED_GEARBOX_BSI. Multi-frame payload carrying a second set of navigation export data to the display. Source: https://github.com/prototux/PSA-RE/blob/67f7581e7622410efdbb29c7eda3b86982b9b450/buses/AEE2010.full/LS.INFO-DIV/0A9.yml. Source sender alternatives: BTEL,OVIP; physical TX/gateway forwarding not verified. WIRE ISO-TP ONLY: normal addressing candidate, maximum Classical CAN DLC 8; actual DLC may be shorter. Data includes padding. No reassembly, text, DID or application-layer decoding. Original application layouts are preserved in source JSON; do not decode them at wire offsets. Unresolved alternative source layouts preserved in source JSON. ";
CM_ SG_ 169 FlowPadding5 "TRANSPORT_CANDIDATE: normal-addressing ISO-TP. PSA-RE bits 8.7-8.0. ";
CM_ SG_ 169 FirstData6 "TRANSPORT_CANDIDATE: normal-addressing ISO-TP. PSA-RE bits 8.7-8.0. ";
CM_ SG_ 169 UnknownData7 "TRANSPORT_CANDIDATE: normal-addressing ISO-TP. PSA-RE bits 8.7-8.0. ";
CM_ SG_ 169 ConsecutiveData7 "TRANSPORT_CANDIDATE: normal-addressing ISO-TP. PSA-RE bits 8.7-8.0. ";
CM_ SG_ 169 SingleData7 "TRANSPORT_CANDIDATE: normal-addressing ISO-TP. PSA-RE bits 8.7-8.0. ";
CM_ SG_ 169 FlowPadding4 "TRANSPORT_CANDIDATE: normal-addressing ISO-TP. PSA-RE bits 7.7-7.0. ";
CM_ SG_ 169 FirstData5 "TRANSPORT_CANDIDATE: normal-addressing ISO-TP. PSA-RE bits 7.7-7.0. ";
CM_ SG_ 169 UnknownData6 "TRANSPORT_CANDIDATE: normal-addressing ISO-TP. PSA-RE bits 7.7-7.0. ";
CM_ SG_ 169 ConsecutiveData6 "TRANSPORT_CANDIDATE: normal-addressing ISO-TP. PSA-RE bits 7.7-7.0. ";
CM_ SG_ 169 SingleData6 "TRANSPORT_CANDIDATE: normal-addressing ISO-TP. PSA-RE bits 7.7-7.0. ";
CM_ SG_ 169 FlowPadding3 "TRANSPORT_CANDIDATE: normal-addressing ISO-TP. PSA-RE bits 6.7-6.0. ";
CM_ SG_ 169 FirstData4 "TRANSPORT_CANDIDATE: normal-addressing ISO-TP. PSA-RE bits 6.7-6.0. ";
CM_ SG_ 169 UnknownData5 "TRANSPORT_CANDIDATE: normal-addressing ISO-TP. PSA-RE bits 6.7-6.0. ";
CM_ SG_ 169 ConsecutiveData5 "TRANSPORT_CANDIDATE: normal-addressing ISO-TP. PSA-RE bits 6.7-6.0. ";
CM_ SG_ 169 SingleData5 "TRANSPORT_CANDIDATE: normal-addressing ISO-TP. PSA-RE bits 6.7-6.0. ";
CM_ SG_ 169 FlowPadding2 "TRANSPORT_CANDIDATE: normal-addressing ISO-TP. PSA-RE bits 5.7-5.0. ";
CM_ SG_ 169 FirstData3 "TRANSPORT_CANDIDATE: normal-addressing ISO-TP. PSA-RE bits 5.7-5.0. ";
CM_ SG_ 169 UnknownData4 "TRANSPORT_CANDIDATE: normal-addressing ISO-TP. PSA-RE bits 5.7-5.0. ";
CM_ SG_ 169 ConsecutiveData4 "TRANSPORT_CANDIDATE: normal-addressing ISO-TP. PSA-RE bits 5.7-5.0. ";
CM_ SG_ 169 SingleData4 "TRANSPORT_CANDIDATE: normal-addressing ISO-TP. PSA-RE bits 5.7-5.0. ";
CM_ SG_ 169 FlowPadding1 "TRANSPORT_CANDIDATE: normal-addressing ISO-TP. PSA-RE bits 4.7-4.0. ";
CM_ SG_ 169 FirstData2 "TRANSPORT_CANDIDATE: normal-addressing ISO-TP. PSA-RE bits 4.7-4.0. ";
CM_ SG_ 169 UnknownData3 "TRANSPORT_CANDIDATE: normal-addressing ISO-TP. PSA-RE bits 4.7-4.0. ";
CM_ SG_ 169 ConsecutiveData3 "TRANSPORT_CANDIDATE: normal-addressing ISO-TP. PSA-RE bits 4.7-4.0. ";
CM_ SG_ 169 SingleData3 "TRANSPORT_CANDIDATE: normal-addressing ISO-TP. PSA-RE bits 4.7-4.0. ";
CM_ SG_ 169 FirstData1 "TRANSPORT_CANDIDATE: normal-addressing ISO-TP. PSA-RE bits 3.7-3.0. ";
CM_ SG_ 169 UnknownData2 "TRANSPORT_CANDIDATE: normal-addressing ISO-TP. PSA-RE bits 3.7-3.0. ";
CM_ SG_ 169 ConsecutiveData2 "TRANSPORT_CANDIDATE: normal-addressing ISO-TP. PSA-RE bits 3.7-3.0. ";
CM_ SG_ 169 SingleData2 "TRANSPORT_CANDIDATE: normal-addressing ISO-TP. PSA-RE bits 3.7-3.0. ";
CM_ SG_ 169 SeparationTimeRaw "TRANSPORT_CANDIDATE: normal-addressing ISO-TP. PSA-RE bits 3.7-3.0. Raw STmin code; 0xF1..0xF9 are not milliseconds.";
CM_ SG_ 169 UnknownData1 "TRANSPORT_CANDIDATE: normal-addressing ISO-TP. PSA-RE bits 2.7-2.0. ";
CM_ SG_ 169 ConsecutiveData1 "TRANSPORT_CANDIDATE: normal-addressing ISO-TP. PSA-RE bits 2.7-2.0. ";
CM_ SG_ 169 SingleData1 "TRANSPORT_CANDIDATE: normal-addressing ISO-TP. PSA-RE bits 2.7-2.0. ";
CM_ SG_ 169 BlockSize "TRANSPORT_CANDIDATE: normal-addressing ISO-TP. PSA-RE bits 2.7-2.0. ";
CM_ SG_ 169 UnknownPciLow "TRANSPORT_CANDIDATE: normal-addressing ISO-TP. PSA-RE bits 1.3-1.0. ";
CM_ SG_ 169 FlowStatus "TRANSPORT_CANDIDATE: normal-addressing ISO-TP. PSA-RE bits 1.3-1.0. ";
CM_ SG_ 169 ConsecutiveSequence "TRANSPORT_CANDIDATE: normal-addressing ISO-TP. PSA-RE bits 1.3-1.0. ";
CM_ SG_ 169 FirstFrameLength "TRANSPORT_CANDIDATE: normal-addressing ISO-TP. PSA-RE bits 1.3-2.0. 12-bit declared PDU length; not a reassembled value.";
CM_ SG_ 169 SingleFrameLength "TRANSPORT_CANDIDATE: normal-addressing ISO-TP. PSA-RE bits 1.3-1.0. Declared data length; not a validity check.";
CM_ SG_ 169 IsoTpFrameType "TRANSPORT_CANDIDATE: normal-addressing ISO-TP. PSA-RE bits 1.7-1.4. PCI high nibble; normal addressing candidate.";
CM_ BO_ 182 "OWNER_CONFIRMED_FIELDS: Speed; other fields remain candidates. INFO-DIV CAN, 125000 bit/s; CAN ID 0x0B6. PSA-RE title: FAST_BSI_DATA. Fast vehicle data broadcast by the body controller: engine speed, vehicle speed, distance and fuel consumption counters. Source: https://github.com/prototux/PSA-RE/blob/67f7581e7622410efdbb29c7eda3b86982b9b450/buses/AEE2010.full/LS.INFO-DIV/0B6.yml. Source sender alternatives: BSI,ICSV; physical TX/gateway forwarding not verified. Observed 11728 frames in info_apka.csv,info_buzeni_obc.csv,info_charging.csv,info_standby.csv,info_start_jizda.csv,infocan.csv; DLCs [8]. Unresolved alternative source layouts preserved in source JSON. ";
CM_ SG_ 182 Unused1 "DATABASE_CANDIDATE: physical interpretation unverified; capture/layout evidence reported separately. PSA-RE bits 8.2-8.0. ";
CM_ SG_ 182 SecuVitesse "DATABASE_CANDIDATE: physical interpretation unverified; capture/layout evidence reported separately. PSA-RE bits 8.6-8.3. Vehicle speed information security status Upstream default raw=5 (not necessarily valid data).";
CM_ SG_ 182 Securisation "DATABASE_CANDIDATE: physical interpretation unverified; capture/layout evidence reported separately. PSA-RE bits 8.7. Vehicle speed information security status Upstream default raw=0 (not necessarily valid data).";
CM_ SG_ 182 FuelConsumption "DATABASE_CANDIDATE: physical interpretation unverified; capture/layout evidence reported separately. PSA-RE bits 7.7-7.0. Rolling fuel consumption counter, 80 mm3 per bit, wraps at 20400 mm3; no invalid value, frozen when unknown Upstream default raw=0 (not necessarily valid data).";
CM_ SG_ 182 DistanceTravelled "DATABASE_CANDIDATE: physical interpretation unverified; capture/layout evidence reported separately. PSA-RE bits 5.7-6.0. Rolling distance counter, 0.1 m per bit, wraps after 0xFFFF (6553.5 m); no invalid value, frozen when unknown Upstream default raw=0 (not necessarily valid data).";
CM_ SG_ 182 Speed "OWNER_CONFIRMED: owner Opel Corsa-e, 2026-10-31; Owner confirms vehicle speed works on the installed dashboard. Scope: Displayed speed; other FastBsiData fields are unverified.. PSA-RE bits 3.7-4.0. Instantaneous vehicle speed (average of the driven wheels) Raw invalid=65535; numeric DBC decoders may still scale it: check raw before use. Upstream default raw=0 (not necessarily valid data).";
CM_ SG_ 182 Rpm "DATABASE_CANDIDATE: physical interpretation unverified; capture/layout evidence reported separately. PSA-RE bits 1.7-2.0. Engine speed, 0.125 rpm per bit; invalid when all bits set Raw invalid=65535; numeric DBC decoders may still scale it: check raw before use. Upstream default raw=8000 (not necessarily valid data).";
CM_ BO_ 189 "DATABASE_CANDIDATE: physical interpretation unverified; capture/layout evidence reported separately. INFO-DIV CAN, 125000 bit/s; CAN ID 0x0BD. PSA-RE title: SDCM_STATUS. SDCM status: hands-free access polling state, key distance and low-battery alert Source: https://github.com/prototux/PSA-RE/blob/67f7581e7622410efdbb29c7eda3b86982b9b450/buses/AEE2010.full/LS.INFO-DIV/0BD.yml. Source sender alternatives: SDCM; physical TX/gateway forwarding not verified. Observed 598 frames in info_apka.csv,info_buzeni_obc.csv,info_charging.csv,info_standby.csv,info_start_jizda.csv,infocan.csv; DLCs [5]. ";
CM_ SG_ 189 RawByte5 "RAW. PSA-RE bits 5.7-5.0. Unmapped/padding bits, no physical interpretation.";
CM_ SG_ 189 Unused1 "DATABASE_CANDIDATE: physical interpretation unverified; capture/layout evidence reported separately. PSA-RE bits 4.1-4.0. ";
CM_ SG_ 189 SmartDevice5Enabled "DATABASE_CANDIDATE: physical interpretation unverified; capture/layout evidence reported separately. PSA-RE bits 4.2. Status indicating whether smart device (phone key) 5 is authorized (not blacklisted) Upstream default raw=0 (not necessarily valid data).";
CM_ SG_ 189 SmartDevice4Enabled "DATABASE_CANDIDATE: physical interpretation unverified; capture/layout evidence reported separately. PSA-RE bits 4.3. Status indicating whether smart device (phone key) 4 is authorized (not blacklisted) Upstream default raw=0 (not necessarily valid data).";
CM_ SG_ 189 SmartDevice3Enabled "DATABASE_CANDIDATE: physical interpretation unverified; capture/layout evidence reported separately. PSA-RE bits 4.4. Status indicating whether smart device (phone key) 3 is authorized (not blacklisted) Upstream default raw=0 (not necessarily valid data).";
CM_ SG_ 189 SmartDevice2Enabled "DATABASE_CANDIDATE: physical interpretation unverified; capture/layout evidence reported separately. PSA-RE bits 4.5. Status indicating whether smart device (phone key) 2 is authorized (not blacklisted) Upstream default raw=0 (not necessarily valid data).";
CM_ SG_ 189 SmartDevice1Enabled "DATABASE_CANDIDATE: physical interpretation unverified; capture/layout evidence reported separately. PSA-RE bits 4.6. Status indicating whether smart device (phone key) 1 is authorized (not blacklisted) Upstream default raw=0 (not necessarily valid data).";
CM_ SG_ 189 SmartDevice5Zone "DATABASE_CANDIDATE: physical interpretation unverified; capture/layout evidence reported separately. PSA-RE bits 3.1-4.7. Zone in which smart device (phone key) 5 is located Upstream default raw=0 (not necessarily valid data).";
CM_ SG_ 189 SmartDevice4Zone "DATABASE_CANDIDATE: physical interpretation unverified; capture/layout evidence reported separately. PSA-RE bits 3.4-3.2. Zone in which smart device (phone key) 4 is located Upstream default raw=0 (not necessarily valid data).";
CM_ SG_ 189 SmartDevice3Zone "DATABASE_CANDIDATE: physical interpretation unverified; capture/layout evidence reported separately. PSA-RE bits 3.7-3.5. Zone in which smart device (phone key) 3 is located Upstream default raw=0 (not necessarily valid data).";
CM_ SG_ 189 SmartDevice2Zone "DATABASE_CANDIDATE: physical interpretation unverified; capture/layout evidence reported separately. PSA-RE bits 2.2-2.0. Zone in which smart device (phone key) 2 is located Upstream default raw=0 (not necessarily valid data).";
CM_ SG_ 189 SmartDevice1Zone "DATABASE_CANDIDATE: physical interpretation unverified; capture/layout evidence reported separately. PSA-RE bits 2.5-2.3. Zone in which smart device (phone key) 1 is located Upstream default raw=0 (not necessarily valid data).";
CM_ SG_ 189 HfaPollingStatus "DATABASE_CANDIDATE: physical interpretation unverified; capture/layout evidence reported separately. PSA-RE bits 2.6. Current status of the hands-free access (HFA) polling on the smart device module (SDCM)";
CM_ SG_ 189 HfaFeatureStatus "DATABASE_CANDIDATE: physical interpretation unverified; capture/layout evidence reported separately. PSA-RE bits 2.7. Current status of the hands-free access (HFA) feature on the smart device module (SDCM)";
CM_ SG_ 189 SmartDeviceFeatureStatus "DATABASE_CANDIDATE: physical interpretation unverified; capture/layout evidence reported separately. PSA-RE bits 1.0. Current status of the smart device feature on the smart device module (SDCM)";
CM_ SG_ 189 SdcmAuthorizationStatus "DATABASE_CANDIDATE: physical interpretation unverified; capture/layout evidence reported separately. PSA-RE bits 1.1. Current authorization status of the smart device module (SDCM)";
CM_ SG_ 189 WalUirFeatureStatus "DATABASE_CANDIDATE: physical interpretation unverified; capture/layout evidence reported separately. PSA-RE bits 1.2. Current status of the welcome/unlock (WAL/UIR) feature on the smart device module (SDCM)";
CM_ SG_ 189 CidLowEnergyAlert "DATABASE_CANDIDATE: physical interpretation unverified; capture/layout evidence reported separately. PSA-RE bits 1.3. Alert on the energy level (battery) of the last used smart device (CID) Upstream default raw=0 (not necessarily valid data).";
CM_ SG_ 189 HfaPollingType "DATABASE_CANDIDATE: physical interpretation unverified; capture/layout evidence reported separately. PSA-RE bits 1.7-1.4. Type of hands-free access (HFA) polling currently running on the smart device module (SDCM) Upstream default raw=1 (not necessarily valid data).";
CM_ BO_ 191 "DATABASE_CANDIDATE: physical interpretation unverified; capture/layout evidence reported separately. INFO-DIV CAN, 125000 bit/s; CAN ID 0x0BF. PSA-RE title: WINDOW_SUNROOF_REQUEST. Window, sunroof/blind and door position requests and Bluetooth/card authentication requests, sent by the BSI to the smart door control module. Source: https://github.com/prototux/PSA-RE/blob/67f7581e7622410efdbb29c7eda3b86982b9b450/buses/AEE2010.full/LS.INFO-DIV/0BF.yml. Source sender alternatives: BSI; physical TX/gateway forwarding not verified. Observed 2941 frames in info_apka.csv,info_buzeni_obc.csv,info_charging.csv,info_standby.csv,info_start_jizda.csv,infocan.csv; DLCs [6]. ";
CM_ SG_ 191 RawByte6 "RAW. PSA-RE bits 6.7-6.0. Unmapped/padding bits, no physical interpretation.";
CM_ SG_ 191 RawByte5 "RAW. PSA-RE bits 5.7-5.0. Unmapped/padding bits, no physical interpretation.";
CM_ SG_ 191 RawByte4 "RAW. PSA-RE bits 4.7-4.0. Unmapped/padding bits, no physical interpretation.";
CM_ SG_ 191 Unused1 "DATABASE_CANDIDATE: physical interpretation unverified; capture/layout evidence reported separately. PSA-RE bits 3.5-3.0. ";
CM_ SG_ 191 HandsFreeAccessAnticipati_78e7e7 "DATABASE_CANDIDATE: physical interpretation unverified; capture/layout evidence reported separately. PSA-RE bits 3.6. Request to anticipate a hands-free unlocking action Upstream default raw=0 (not necessarily valid data).";
CM_ SG_ 191 HandsFreeAccessDiagnosticRequest "DATABASE_CANDIDATE: physical interpretation unverified; capture/layout evidence reported separately. PSA-RE bits 3.7. Request to run the antenna and ASIC diagnostic Upstream default raw=0 (not necessarily valid data).";
CM_ SG_ 191 UirBackwardAreaInclusion "DATABASE_CANDIDATE: physical interpretation unverified; capture/layout evidence reported separately. PSA-RE bits 2.0. Whether the vehicle's rear area is included in the UIR detection zone Upstream default raw=0 (not necessarily valid data).";
CM_ SG_ 191 WelcomeAccessLockingSoundRequest "DATABASE_CANDIDATE: physical interpretation unverified; capture/layout evidence reported separately. PSA-RE bits 2.2-2.1. Request to play a sound for the welcome/access/locking function Upstream default raw=0 (not necessarily valid data).";
CM_ SG_ 191 LastLockActionSource "DATABASE_CANDIDATE: physical interpretation unverified; capture/layout evidence reported separately. PSA-RE bits 2.7-2.3. Feature used for the last lock/unlock action Upstream default raw=0 (not necessarily valid data).";
CM_ SG_ 191 BluetoothSmartDeviceAuthe_322363 "DATABASE_CANDIDATE: physical interpretation unverified; capture/layout evidence reported separately. PSA-RE bits 1.0. Request for an authenticated smart device via Bluetooth Upstream default raw=0 (not necessarily valid data).";
CM_ SG_ 191 NfcSmartDeviceAuthenticat_268716 "DATABASE_CANDIDATE: physical interpretation unverified; capture/layout evidence reported separately. PSA-RE bits 1.1. Request for an authenticated smart device via NFC Upstream default raw=0 (not necessarily valid data).";
CM_ SG_ 191 NfcCardAuthenticationRequest "DATABASE_CANDIDATE: physical interpretation unverified; capture/layout evidence reported separately. PSA-RE bits 1.2. Request for an authenticated NFC card Upstream default raw=0 (not necessarily valid data).";
CM_ SG_ 191 CidAuthenticationRequest "DATABASE_CANDIDATE: physical interpretation unverified; capture/layout evidence reported separately. PSA-RE bits 1.3. Request for an authenticated CID Upstream default raw=0 (not necessarily valid data).";
CM_ SG_ 191 CidSearchRequest "DATABASE_CANDIDATE: physical interpretation unverified; capture/layout evidence reported separately. PSA-RE bits 1.7-1.4. Indicates whether and where the system should search for a CID around the vehicle Upstream default raw=0 (not necessarily valid data).";
CM_ BO_ 193 "DATABASE_CANDIDATE: physical interpretation unverified; capture/layout evidence reported separately. INFO-DIV CAN, 125000 bit/s; CAN ID 0x0C1. PSA-RE title: SDCM_APDU_TRANSMIT. Navigation data export payload transmitted by the SDCM Source: https://github.com/prototux/PSA-RE/blob/67f7581e7622410efdbb29c7eda3b86982b9b450/buses/AEE2010.full/LS.INFO-DIV/0C1.yml. Source sender alternatives: SDCM; physical TX/gateway forwarding not verified. WIRE ISO-TP ONLY: normal addressing candidate, maximum Classical CAN DLC 8; actual DLC may be shorter. Data includes padding. No reassembly, text, DID or application-layer decoding. Original application layouts are preserved in source JSON; do not decode them at wire offsets. Unresolved alternative source layouts preserved in source JSON. ";
CM_ SG_ 193 FlowPadding5 "TRANSPORT_CANDIDATE: normal-addressing ISO-TP. PSA-RE bits 8.7-8.0. ";
CM_ SG_ 193 FirstData6 "TRANSPORT_CANDIDATE: normal-addressing ISO-TP. PSA-RE bits 8.7-8.0. ";
CM_ SG_ 193 UnknownData7 "TRANSPORT_CANDIDATE: normal-addressing ISO-TP. PSA-RE bits 8.7-8.0. ";
CM_ SG_ 193 ConsecutiveData7 "TRANSPORT_CANDIDATE: normal-addressing ISO-TP. PSA-RE bits 8.7-8.0. ";
CM_ SG_ 193 SingleData7 "TRANSPORT_CANDIDATE: normal-addressing ISO-TP. PSA-RE bits 8.7-8.0. ";
CM_ SG_ 193 FlowPadding4 "TRANSPORT_CANDIDATE: normal-addressing ISO-TP. PSA-RE bits 7.7-7.0. ";
CM_ SG_ 193 FirstData5 "TRANSPORT_CANDIDATE: normal-addressing ISO-TP. PSA-RE bits 7.7-7.0. ";
CM_ SG_ 193 UnknownData6 "TRANSPORT_CANDIDATE: normal-addressing ISO-TP. PSA-RE bits 7.7-7.0. ";
CM_ SG_ 193 ConsecutiveData6 "TRANSPORT_CANDIDATE: normal-addressing ISO-TP. PSA-RE bits 7.7-7.0. ";
CM_ SG_ 193 SingleData6 "TRANSPORT_CANDIDATE: normal-addressing ISO-TP. PSA-RE bits 7.7-7.0. ";
CM_ SG_ 193 FlowPadding3 "TRANSPORT_CANDIDATE: normal-addressing ISO-TP. PSA-RE bits 6.7-6.0. ";
CM_ SG_ 193 FirstData4 "TRANSPORT_CANDIDATE: normal-addressing ISO-TP. PSA-RE bits 6.7-6.0. ";
CM_ SG_ 193 UnknownData5 "TRANSPORT_CANDIDATE: normal-addressing ISO-TP. PSA-RE bits 6.7-6.0. ";
CM_ SG_ 193 ConsecutiveData5 "TRANSPORT_CANDIDATE: normal-addressing ISO-TP. PSA-RE bits 6.7-6.0. ";
CM_ SG_ 193 SingleData5 "TRANSPORT_CANDIDATE: normal-addressing ISO-TP. PSA-RE bits 6.7-6.0. ";
CM_ SG_ 193 FlowPadding2 "TRANSPORT_CANDIDATE: normal-addressing ISO-TP. PSA-RE bits 5.7-5.0. ";
CM_ SG_ 193 FirstData3 "TRANSPORT_CANDIDATE: normal-addressing ISO-TP. PSA-RE bits 5.7-5.0. ";
CM_ SG_ 193 UnknownData4 "TRANSPORT_CANDIDATE: normal-addressing ISO-TP. PSA-RE bits 5.7-5.0. ";
CM_ SG_ 193 ConsecutiveData4 "TRANSPORT_CANDIDATE: normal-addressing ISO-TP. PSA-RE bits 5.7-5.0. ";
CM_ SG_ 193 SingleData4 "TRANSPORT_CANDIDATE: normal-addressing ISO-TP. PSA-RE bits 5.7-5.0. ";
CM_ SG_ 193 FlowPadding1 "TRANSPORT_CANDIDATE: normal-addressing ISO-TP. PSA-RE bits 4.7-4.0. ";
CM_ SG_ 193 FirstData2 "TRANSPORT_CANDIDATE: normal-addressing ISO-TP. PSA-RE bits 4.7-4.0. ";
CM_ SG_ 193 UnknownData3 "TRANSPORT_CANDIDATE: normal-addressing ISO-TP. PSA-RE bits 4.7-4.0. ";
CM_ SG_ 193 ConsecutiveData3 "TRANSPORT_CANDIDATE: normal-addressing ISO-TP. PSA-RE bits 4.7-4.0. ";
CM_ SG_ 193 SingleData3 "TRANSPORT_CANDIDATE: normal-addressing ISO-TP. PSA-RE bits 4.7-4.0. ";
CM_ SG_ 193 FirstData1 "TRANSPORT_CANDIDATE: normal-addressing ISO-TP. PSA-RE bits 3.7-3.0. ";
CM_ SG_ 193 UnknownData2 "TRANSPORT_CANDIDATE: normal-addressing ISO-TP. PSA-RE bits 3.7-3.0. ";
CM_ SG_ 193 ConsecutiveData2 "TRANSPORT_CANDIDATE: normal-addressing ISO-TP. PSA-RE bits 3.7-3.0. ";
CM_ SG_ 193 SingleData2 "TRANSPORT_CANDIDATE: normal-addressing ISO-TP. PSA-RE bits 3.7-3.0. ";
CM_ SG_ 193 SeparationTimeRaw "TRANSPORT_CANDIDATE: normal-addressing ISO-TP. PSA-RE bits 3.7-3.0. Raw STmin code; 0xF1..0xF9 are not milliseconds.";
CM_ SG_ 193 UnknownData1 "TRANSPORT_CANDIDATE: normal-addressing ISO-TP. PSA-RE bits 2.7-2.0. ";
CM_ SG_ 193 ConsecutiveData1 "TRANSPORT_CANDIDATE: normal-addressing ISO-TP. PSA-RE bits 2.7-2.0. ";
CM_ SG_ 193 SingleData1 "TRANSPORT_CANDIDATE: normal-addressing ISO-TP. PSA-RE bits 2.7-2.0. ";
CM_ SG_ 193 BlockSize "TRANSPORT_CANDIDATE: normal-addressing ISO-TP. PSA-RE bits 2.7-2.0. ";
CM_ SG_ 193 UnknownPciLow "TRANSPORT_CANDIDATE: normal-addressing ISO-TP. PSA-RE bits 1.3-1.0. ";
CM_ SG_ 193 FlowStatus "TRANSPORT_CANDIDATE: normal-addressing ISO-TP. PSA-RE bits 1.3-1.0. ";
CM_ SG_ 193 ConsecutiveSequence "TRANSPORT_CANDIDATE: normal-addressing ISO-TP. PSA-RE bits 1.3-1.0. ";
CM_ SG_ 193 FirstFrameLength "TRANSPORT_CANDIDATE: normal-addressing ISO-TP. PSA-RE bits 1.3-2.0. 12-bit declared PDU length; not a reassembled value.";
CM_ SG_ 193 SingleFrameLength "TRANSPORT_CANDIDATE: normal-addressing ISO-TP. PSA-RE bits 1.3-1.0. Declared data length; not a validity check.";
CM_ SG_ 193 IsoTpFrameType "TRANSPORT_CANDIDATE: normal-addressing ISO-TP. PSA-RE bits 1.7-1.4. PCI high nibble; normal addressing candidate.";
BA_DEF_  "BusType" STRING ;
BA_DEF_  "Baudrate" INT 0 1000000;

BA_ "BusType" "CAN";
BA_ "Baudrate" 125000;
VAL_ 0 EspDisconnectRequest 0 "Connected by diagnostic tool" 1 "Disconnected by diagnostic tool" ;
VAL_ 0 BrakeAssistFaultLampRequest 0 "No ignition request" 1 "Fault lamp lighting request" ;
VAL_ 0 StaticSlopeState 0 "Low slope" 1 "Steep uphill slope" 2 "high downhill slope" 3 "Slope undefined" ;
VAL_ 0 BrakeFunctionNeedForStartStop 0 "No need, per brake function" 1 "Stop transition inhibition" 2 "Restart request" 3 "Stop and restart transition inhibited" ;
VAL_ 0 BrakeEcuPowerManagementFault 0 "No fault detected" 1 "Failure detected" ;
VAL_ 0 EmergencyBrakingSignaliza_517ee3 0 "SFU function not present in the brake ECU" 1 "SFU function present in the brake ECU" ;
VAL_ 0 BatteryVoltageUcBrake 255 "Not_available" ;
VAL_ 0 RearRightWheelSpeedSensorFault 0 "No fault on the rear right pulse counter" 1 "Rear right pulse counter fault" ;
VAL_ 0 RearLeftWheelSpeedSensorFault 0 "No fault on RRL pulse counter" 1 "Rear left pulse counter fault" ;
VAL_ 0 AbsFaultLampRequest 0 "Lamp off" 1 "Lamp on" ;
VAL_ 0 BrakeFluidLevelAlert 0 "No alert" 1 "Alert" ;
VAL_ 0 WornBrakePadsIndicator 0 "Brake pads in good condition" 1 "Brake pads worn out" ;
VAL_ 0 RefInProgress 0 "Not in regulation" 1 "In regulation" ;
VAL_ 0 AutomaticHazardLightsByUcBrake 0 "AAFD function not present in the brake ECU" 1 "AAFD function present in the brake ECU" ;
VAL_ 0 AbsInProgress 0 "Not in regulation" 1 "In regulation" ;
VAL_ 0 RefFaultLamp 0 "Lamp off" 1 "Lamp on" ;
VAL_ 1 UidTableLearnRequestToBsi 0 "No request" 1 "Request" ;
VAL_ 2 AcPrecondSundaySchedule2Active 0 "Function off" 1 "Function active" ;
VAL_ 2 AcPrecondSaturdaySchedule2Active 0 "Function off" 1 "Function active" ;
VAL_ 2 AcPrecondFridaySchedule2Active 0 "Function off" 1 "Function active" ;
VAL_ 2 AcPrecondThursdaySchedule2Active 0 "Function off" 1 "Function active" ;
VAL_ 2 AcPrecondWednesdaySchedul_14303b 0 "Function off" 1 "Function active" ;
VAL_ 2 AcPrecondTuesdaySchedule2Active 0 "Function off" 1 "Function active" ;
VAL_ 2 AcPrecondMondaySchedule2Active 0 "Function off" 1 "Function active" ;
VAL_ 2 AcPrecondSchedule2Enabled 0 "Function off" 1 "Function active" ;
VAL_ 2 AcPrecondSundaySchedule1Active 0 "Function off" 1 "Function active" ;
VAL_ 2 AcPrecondSaturdaySchedule1Active 0 "Function off" 1 "Function active" ;
VAL_ 2 AcPrecondFridaySchedule1Active 0 "Function off" 1 "Function active" ;
VAL_ 2 AcPrecondThursdaySchedule1Active 0 "Function off" 1 "Function active" ;
VAL_ 2 AcPrecondWednesdaySchedul_0079d6 0 "Function off" 1 "Function active" ;
VAL_ 2 AcPrecondTuesdaySchedule1Active 0 "Function off" 1 "Function active" ;
VAL_ 2 AcPrecondMondaySchedule1Active 0 "Function off" 1 "Function active" ;
VAL_ 2 AcPrecondSchedule1Enabled 0 "Function off" 1 "Function active" ;
VAL_ 2 AcPrecondAsapModeActive 0 "Inactive" 1 "Active" ;
VAL_ 2 AcPrecondStatusFeedback 0 "Inactive" 1 "Active (immediately)" 2 "Finished" 3 "Default" 4 "Not available: doors open or unlocked" 5 "Not available, low battery SOC" 6 "Not available Low Fuel Level" 7 "Not available, too many unused preconditioning sessions" 8 "Programmed active" ;
VAL_ 2 AcPrecondStatusAvailability 0 "Unavailable" 1 "Available" ;
VAL_ 24 PedestrianCrashInfo 0 "Crash not detected" 1 "Crash detected" ;
VAL_ 24 AutomaticEcallTrigger 0 "Airbag ECU unable to detect a crash" 1 "No request to send an auto eCall" 2 "Request to send an automatic eCall" ;
VAL_ 24 CrashUnlockRequest 0 "No crash" 1 "Crash unlock request" ;
VAL_ 24 CrashDetectedSinceLastPowerUp 0 "Crash not detected" 1 "Crash detected since last contact" ;
VAL_ 24 RolloverCrash 0 "Crash not detected" 1 "Crash detected" ;
VAL_ 24 HighSpeedRearCrash 0 "Crash not detected" 1 "Crash detected" ;
VAL_ 24 AverageSpeedRearCrash 0 "Crash not detected" 1 "Crash detected" ;
VAL_ 24 LowSpeedRearCrash 0 "Crash not detected" 1 "Crash detected" ;
VAL_ 24 PossibleRearCrash 0 "Crash not detected" 1 "Crash detected" ;
VAL_ 24 HighSpeedSideCrash 0 "Crash not detected" 1 "Crash detected" ;
VAL_ 24 AverageSpeedSideCrash 0 "Crash not detected" 1 "Crash detected" ;
VAL_ 24 LowSpeedSideCrash 0 "Crash not detected" 1 "Crash detected" ;
VAL_ 24 PossibleSideCrash 0 "Crash not detected" 1 "Crash detected" ;
VAL_ 24 HighSpeedFrontalCrash 0 "Crash not detected" 1 "Crash detected" ;
VAL_ 24 AverageSpeedFrontalCrashN2 0 "Crash not detected" 1 "Crash detected" ;
VAL_ 24 AverageSpeedFrontalCrashN1 0 "Crash not detected" 1 "Crash detected" ;
VAL_ 24 LowSpeedFrontalCrash 0 "Crash not detected" 1 "Crash detected" ;
VAL_ 24 PossibleFrontalCrash 0 "Crash not detected" 1 "Crash detected" ;
VAL_ 24 PassengerAirbagInhibitionStatus 0 "Pack inhibited" 1 "Pack activated" ;
VAL_ 28 SpeedLimitZone5State 0 "Function off" 1 "Function active" ;
VAL_ 28 SpeedLimitZone4State 0 "Function off" 1 "Function active" ;
VAL_ 28 SpeedLimitZone3State 0 "Function off" 1 "Function active" ;
VAL_ 28 SpeedLimitZone2State 0 "Function off" 1 "Function active" ;
VAL_ 28 SpeedLimitZone1State 0 "Function off" 1 "Function active" ;
VAL_ 28 SpeedLimitMainState 0 "Function off" 1 "Function active" ;
VAL_ 28 CruiseMenuInfoAvailability 0 "Unavailable" 1 "Available" ;
VAL_ 28 PreconditioningClockSelection 2047 "Not_available" ;
VAL_ 28 PreconditioningActivationRequest 0 "Inactive" 1 "Active" ;
VAL_ 28 PreconditioningTypeRequest 0 "Ventilation" 1 "Preheating" ;
VAL_ 28 PreconditioningDataValidity 0 "Information unavailable" 1 "Information available" ;
VAL_ 29 HandshakeSdcmToBsi 0 "NACK" 1 "ACK" ;
VAL_ 30 HandshakeBsiToSdcm 0 "NACK" 1 "ACK" ;
VAL_ 40 AlwaysUsefulFunctionPermission 0 "False" 1 "True" ;
VAL_ 40 AlwaysUselessFunctionRestriction 0 "Restricted attention required" 1 "Restricted bad driving" 2 "FREE" ;
VAL_ 40 PrecisionGestureInteracti_60b22b 0 "Restricted attention required" 1 "Restricted bad driving" 2 "FREE" ;
VAL_ 40 NumericInputInteractionAllowed 0 "Restricted attention required" 1 "Restricted bad driving" 2 "FREE" ;
VAL_ 40 OffboardHmiInteractionAllowed 0 "Restricted attention required" 1 "Restricted bad driving" 2 "FREE" ;
VAL_ 40 TextReadingInteractionAllowed 0 "Restricted attention required" 1 "Restricted bad driving" 2 "FREE" ;
VAL_ 40 ObjectManagementInteracti_8211bb 0 "Restricted attention required" 1 "Restricted bad driving" 2 "FREE" ;
VAL_ 40 DynamicVisualFeedbackInte_8afc95 0 "Restricted attention required" 1 "Restricted bad driving" 2 "FREE" ;
VAL_ 40 AlphanumericKeyboardInter_499d43 0 "False" 1 "True" ;
VAL_ 40 VeryDisturbingInteractionAllowed 0 "False" 1 "True" ;
VAL_ 48 BatterySocRedZone 127 "Not_available" ;
VAL_ 48 AccessoryInstantPowerConsumption 63 "Not_available" ;
VAL_ 48 FrontElectricMotorStatus 0 "Not activated" 1 "Engine" 2 "Resisting" 3 "Generator" ;
VAL_ 48 ChargeStatus 0 "Not activated" 1 "Recharge" 2 "discharge" 3 "Invalid" ;
VAL_ 48 ElectricMotorStatus 0 "Not activated" 1 "Engine" 2 "Resisting" 3 "Invalid" ;
VAL_ 48 CombustionEngineStatus 0 "Not activated" 1 "Engine" 2 "Resisting" 3 "Invalid" ;
VAL_ 48 ZeroEmissionRequest 0 "No request" 1 "Requested" ;
VAL_ 48 StartStopPresence 0 "Absent" 1 "Present" ;
VAL_ 48 StartStopAvailability 0 "Unavailable" 1 "Active" 2 "Deactivated" 3 "Invalid" ;
VAL_ 48 SecondsStopCounter 63 "Not_available" ;
VAL_ 48 MinutesStopCounter 63 "Not_available" ;
VAL_ 54 TePosition 0 "Coupe position" 1 "Cabriolet position" ;
VAL_ 54 AudioInviolability 0 "Tamper-proofing not requested" 1 "Tamper-proof requested" ;
VAL_ 54 EngineBayAccPowerCommand 0 "+APC unchanged" 1 "+APC unchanged" 2 "+APC OFF" 3 "+APC on" ;
VAL_ 54 SecureInfo 0 "Electrical system main state information not valid" 1 "Electrical system main state information not valid" 2 "Electrical system main state information not valid" 3 "Electrical system main state information not valid" 4 "Electrical system main state information not valid" 5 "Electrical system main state information not valid" 6 "Electrical system main state information not valid" 7 "Electrical system main state information not valid" 8 "Electrical system main state information not valid" 9 "Electrical system main state information not valid" 10 "Electrical system main state information valid" 11 "Electrical system main state information not valid" 12 "Electrical system main state information not valid" 13 "Electrical system main state information not valid" 14 "Electrical system main state information not valid" 15 "Electrical system main state information not valid" ;
VAL_ 54 RadioOnOffSync 0 "Push acknowledgement authorized" 1 "Push not taken into account, not authorized" ;
VAL_ 54 RadioOnOffToggle 0 "Switch off" 1 "Pressed" ;
VAL_ 54 PreconditioningMenuPresence 0 "Not present" 1 "Present" ;
VAL_ 54 AvrActivationStatus 0 "Inactive" 1 "Active" ;
VAL_ 54 CafrValidationCommand 0 "Not available" 1 "Available" ;
VAL_ 54 SpeedDisplayOffset 0 "No additional" 1 "Additional offset" ;
VAL_ 54 MediaShutdownRequest 0 "No request" 1 "Requested" ;
VAL_ 54 HybridModeUpdated 0 "Info not refreshed" 1 "Information refreshed" ;
VAL_ 54 HybridMode 0 "4x4" 1 "Sport" 2 "HY" 3 "ZEV" 4 "Comfort" 7 "Invalid" ;
VAL_ 54 HybridStatusUpdated 0 "Info not refreshed" 1 "Information refreshed" ;
VAL_ 54 HybridStatus 0 "Unspecified" 1 "Inactive" 2 "Active while stopped" 3 "Active in traction mode" 4 "Active in propulsion mode" 5 "Active in hybrid mode" ;
VAL_ 54 PowerManagement 0 "Standby" 1 "Normal mode" 2 "Standby mode" 3 "Wake-up" 4 "Communication off" ;
VAL_ 54 LogFaults 0 "Storing authorized" 1 "Storage forbidden" ;
VAL_ 54 DiagToolNetworkAuthorization 0 "Not allowed" 1 "Allowed" ;
VAL_ 54 DiagStatus 0 "not authorization" 1 "Authorization" ;
VAL_ 54 ClearFaults 0 "No request" 1 "Delete request" ;
VAL_ 54 DynamicPackActivation 0 "Normal mode request" 1 "Dynamic mode request" ;
VAL_ 54 DarkMode 0 "Black panel inactive" 1 "Black panel active" ;
VAL_ 54 DaynightStatus 0 "Day state" 1 "Night state" ;
VAL_ 54 RheostatType 0 "Manual" 1 "Automatic" ;
VAL_ 54 Resynchronization 0 "Not requested" 1 "Requested" ;
VAL_ 54 AmbientLightLevelFmux 127 "Not_available" ;
VAL_ 54 EcoMode 0 "No eco mode" 1 "ECO mode requested" ;
VAL_ 54 DriverMemorySave 0 "No storage" 1 "Memorization" ;
VAL_ 54 DriverMemory 0 "No callback" 1 "Recall" ;
VAL_ 54 VehicleDirection 0 "Unspecified" 1 "Toward the front" 2 "Toward the rear" 3 "Invalid" ;
VAL_ 65 UidTableLearnRequestToSdcm 0 "No request" 1 "Request" ;
VAL_ 77 SmartDeviceCommandToBsi 0 "No command" 1 "Unlock all doors" ;
VAL_ 77 Cid5Status 0 "Disabled" 1 "Enabled" ;
VAL_ 77 Cid4Status 0 "Disabled" 1 "Enabled" ;
VAL_ 77 Cid3Status 0 "Disabled" 1 "Enabled" ;
VAL_ 77 Cid2Status 0 "Disabled" 1 "Enabled" ;
VAL_ 77 BlacklistingTaskStatus 0 "Not running" 1 "Blacklisting running" 2 "Unblacklisting running" ;
VAL_ 77 NfcIdentifiedOutside 0 "Absent" 1 "Present" 2 "Present, long" ;
VAL_ 77 Cid1Status 0 "Disabled" 1 "Enabled" ;
VAL_ 77 SmartDeviceBtAuthenticati_9fe3dd 0 "Unauthenticated" 1 "Not running" 2 "Running" 3 "Authenticated" ;
VAL_ 77 SmartDeviceNfcAuthenticat_6dabc9 0 "Unauthenticated" 1 "Not running" 2 "Running" 3 "Authenticated" ;
VAL_ 77 NfcCardAuthenticationResult 0 "Unauthenticated" 1 "Not running" 2 "Running" 3 "Authenticated" ;
VAL_ 77 CidAuthenticationResult 0 "Unauthenticated" 1 "Not running" 2 "Running" 3 "Authenticated" ;
VAL_ 77 CidFoundInLockArea 0 "Undefined" 2 "False" 3 "True" ;
VAL_ 77 CidSearchAnswer 0 "Undefined" 2 "False" 3 "True" ;
VAL_ 77 CidOutsideSearchStatus 0 "Not running" 1 "Running" 2 "Auto running" ;
VAL_ 77 CidFoundInside 0 "Undefined" 2 "False" 3 "True" ;
VAL_ 77 CidInsideSearchStatus 0 "Not running" 1 "Running" 2 "Auto running" ;
VAL_ 77 HandsfreeClosureButtonAction 0 "Released" 1 "Short" 2 "Long" 3 "Maintained" ;
VAL_ 77 HandsfreeClosureButton 0 "None" 1 "PASSENGER" 2 "Driver" 3 "Backward" ;
VAL_ 77 HandsfreeAreaTransition 0 "No transition" 1 "Welcome incoming" 2 "UIR incoming" 3 "WAL incoming" 4 "Walk-away exit" 5 "Disappeared" 6 "WAL timeout" ;
VAL_ 79 UnblacklistingRequest 0 "No request" 1 "Request" ;
VAL_ 79 BlacklistingRequest 0 "No request" 1 "Request" ;
VAL_ 79 VehicleConfigMode 0 "Fitting" 1 "Factory" 2 "Check" 3 "Storage / transport" 4 "Customer (normal)" 5 "Showroom mode" 6 "After-sales" 15 "Invalid" ;
VAL_ 79 HandsfreeAccessDisableRequest 0 "Inactive" 1 "Active" ;
VAL_ 79 MainStatus 0 "Stop" 1 "Ignition on" 2 "DEM (starter)" ;
VAL_ 79 WalUirTransitionIgnoreFlag 0 "Inactive" 1 "Active" ;
VAL_ 79 HandsfreePollingDeactivat_5edcdb 0 "No request" 1 "TIMEOUT" 2 "Permanent" ;
VAL_ 79 SdcmAuthorizationRequest 0 "Disallowed" 1 "Allowed" ;
VAL_ 79 SmartDeviceCommDisableRequest 0 "Inactive" 1 "Active" ;
VAL_ 97 ParkSlotSide 0 "Parking slot search, left" 1 "Parking slot search, right" ;
VAL_ 97 CpkStatus 0 "CPK init" 1 "CPK search" 2 "CPK manoeuvre" 3 "CPK error" ;
VAL_ 97 ParkSlotType 0 "Parallel parking slot" 1 "Cross parking slot" ;
VAL_ 104 ZevDistancePercentTrip2 127 "Not_available" ;
VAL_ 104 ZevDistancePercentTrip2Adjusted 127 "Not_available" ;
VAL_ 104 ZevDistancePercentTrip1 127 "Not_available" ;
VAL_ 104 ZevDistancePercentTrip1Adjusted 127 "Not_available" ;
VAL_ 104 ZevDistancePercentCurrentTrip 127 "Not_available" ;
VAL_ 104 ZevDistancePercentCurrent_fbe8bf 127 "Not_available" ;
VAL_ 105 MainMenuSelection 0 "Wi-Fi settings" 1 "Data roaming" 2 "Privacy settings" 3 "Cancel" 7 "No display" ;
VAL_ 105 AudioSourceSwitchAck 0 "False" 1 "True" ;
VAL_ 105 WifiSettingsUpdateAck 0 "Not updated" 1 "Updated" ;
VAL_ 105 HmiUserAction 0 "No action" 1 "Dismiss" 2 "Yes" ;
VAL_ 105 HmiPopupIdAck 0 "No display" 1 "Incoming advisor call" 2 "Initiated advisor call" 3 "Emergency call initiated" 4 "Connected Advisor call" 5 "Connected emergency call" 6 "Sending vehicle location" 7 "OnStar main menu" 8 "Roaming active" 9 "Roaming ended" ;
VAL_ 159 FlowStatus 0 "ContinueToSend" 1 "Wait" 2 "Overflow" ;
VAL_ 159 IsoTpFrameType 0 "SingleFrame" 1 "FirstFrame" 2 "ConsecutiveFrame" 3 "FlowControl" ;
VAL_ 161 AcpkVehicleTooFast 0 "False" 1 "True" ;
VAL_ 161 AcpkGearboxNeutralStatus 0 "False" 1 "True" ;
VAL_ 161 AcpkManeuverSide 0 "Left" 1 "Right" ;
VAL_ 161 AcpkManeuverState 0 "Ready" 1 "In progress" 2 "Move forward" 3 "MOVE BACKWARD" 4 "Suspended on obstacle" 5 "Suspended on action" 6 "Braking request suspended" 7 "Suspended" 8 "Suspended request, brake released" 9 "Finished" 10 "Finished, retake control" 11 "Aborted" 12 "Aborted fault" 13 "Aborted retake control" 14 "Value not used" 15 "Value not used" ;
VAL_ 161 AcpkPreparationState 0 "No demand" 1 "Entry" 2 "Exit" 3 "Exit not possible" 4 "Search" 5 "Move forward" 6 "Stopped" 7 "Check list" 8 "Ready" 9 "Disclaimer" 10 "Maneuver" 11 "Value not used" 12 "Value not used" 13 "Value not used" 14 "Value not used" 15 "Value not used" ;
VAL_ 161 AcpkBrakePedalStatus 0 "Released" 1 "PRESSED" ;
VAL_ 161 AcpkManeuverDirection 0 "Reverse" 1 "Reverse in progress" 2 "Forward" 3 "Forward in progress" ;
VAL_ 161 AcpkManeuverType 0 "None" 1 "Parallel entry" 2 "Parallel exit" 3 "Perpendicular entry" ;
VAL_ 161 FrontLeftCenterObstacleDistance 0 "Front area 1" 1 "Front zone 2" 2 "Front area 3" 3 "Front area 4" 4 "Front area 5" 5 "Front area 6" 6 "Front area 7" 7 "Front area 8" ;
VAL_ 161 FrontRightCenterObstacleDistance 0 "Front area 1" 1 "Front zone 2" 2 "Front area 3" 3 "Front area 4" 4 "Front area 5" 5 "Front area 6" 6 "Front area 7" 7 "Front area 8" ;
VAL_ 161 RearLeftCenterObstacleDistance 0 "Rear area 1" 1 "Rear area 2" 2 "Rear area 3" 3 "Rear area 4" 4 "Rear zone 5" 5 "Rear area 6" 6 "Rear area 7" 7 "Rear area 8" 8 "Rear area 9" 9 "Rear area 10" ;
VAL_ 161 RearRightCenterObstacleDistance 0 "Rear area 1" 1 "Rear area 2" 2 "Rear area 3" 3 "Rear area 4" 4 "Rear zone 5" 5 "Rear area 6" 6 "Rear area 7" 7 "Rear area 8" 8 "Rear area 9" 9 "Rear area 10" ;
VAL_ 161 FrontRightLateralObstacle_ef9eb7 0 "Zone 1 (very close obstacle)" 1 "Area 2" 2 "Zone 3" 3 "Zone 4 (obstacle far away)" ;
VAL_ 161 CenterRightLateralObstacl_127351 0 "Zone 1 (very close obstacle)" 1 "Area 2" 2 "Zone 3" 3 "Zone 4 (obstacle far away)" ;
VAL_ 161 RearRightLateralObstacleDistance 0 "Zone 1 (very close obstacle)" 1 "Area 2" 2 "Zone 3" 3 "Zone 4 (obstacle far away)" ;
VAL_ 161 FrontLeftLateralObstacleDistance 0 "Zone 1 (very close obstacle)" 1 "Area 2" 2 "Zone 3" 3 "Zone 4 (obstacle far away)" ;
VAL_ 161 CenterLeftLateralObstacle_db978a 0 "Zone 1 (very close obstacle)" 1 "Area 2" 2 "Zone 3" 3 "Zone 4 (obstacle far away)" ;
VAL_ 161 RearLeftLateralObstacleDistance 0 "Zone 1 (very close obstacle)" 1 "Area 2" 2 "Zone 3" 3 "Zone 4 (obstacle far away)" ;
VAL_ 161 SamActivityStatus 0 "Inactive" 1 "Active" 4 "Inhibited" 6 "Invalid" 7 "Failure detected" ;
VAL_ 161 SamLedRequest 0 "Off" 1 "On" 2 "Flashing" 3 "Invalid" ;
VAL_ 161 SamRightObjectPresent 0 "Absent" 1 "Present" ;
VAL_ 161 SamLeftObjectPresent 0 "Absent" 1 "Present" ;
VAL_ 161 CityParkHmiRequest 0 "No request" 1 "Direction choice requested" 2 "Measurement in progress" 3 "Automatic station search in progress" 4 "Move forward request" 5 "Reverse gear engagement request" 6 "Automatic station move in front of" 7 "Automatic station move back" 8 "End of manoeuvre" 9 "Deactivated" ;
VAL_ 162 VolumeKnobScrollUnderflow 0 "Command not activated" 1 "Command activated" ;
VAL_ 162 VolumeKnobScrollOverflow 0 "Command not activated" 1 "Command activated" ;
VAL_ 162 RecyclAirEtVmf 0 "Command not activated" 1 "Command activated" ;
VAL_ 162 CmbEscapeButton 0 "Command not activated" 1 "Command activated" ;
VAL_ 162 CmbValidationButton 0 "Command not activated" 1 "Command activated" ;
VAL_ 162 CmbNavMenuScrollUnderflow 0 "Command not activated" 1 "Command activated" ;
VAL_ 162 CmbNavMenuScrollOverflow 0 "Command not activated" 1 "Command activated" ;
VAL_ 162 SteeringWheelTelephoneCommand 0 "Command not activated" 1 "Command activated" ;
VAL_ 162 SteeringWheelVoiceCommand 0 "Command not activated" 1 "Command activated" ;
VAL_ 162 SteeringWheelLeftPush 0 "Command not activated" 1 "Command activated" ;
VAL_ 162 SteeringWheelModeButton 0 "Command not activated" 1 "Command activated" ;
VAL_ 162 SteeringWheelMenuButton 0 "Command not activated" 1 "Command activated" ;
VAL_ 162 SteeringWheelEscapeButton 0 "Command not activated" 1 "Command activated" ;
VAL_ 162 SteeringWheelValidationButton 0 "Command not activated" 1 "Command activated" ;
VAL_ 162 SteeringWheelNavMenuScrol_49cbf8 0 "Command not activated" 1 "Command activated" ;
VAL_ 162 SteeringWheelNavMenuScrol_3fd970 0 "Command not activated" 1 "Command activated" ;
VAL_ 164 FlowStatus 0 "ContinueToSend" 1 "Wait" 2 "Overflow" ;
VAL_ 164 IsoTpFrameType 0 "SingleFrame" 1 "FirstFrame" 2 "ConsecutiveFrame" 3 "FlowControl" ;
VAL_ 165 SttButtonStatus 0 "Not activated" 1 "Activated" ;
VAL_ 165 AasButtonStatus 0 "Not activated" 1 "Activated" ;
VAL_ 166 RearRightWheelPulseCounterFault 0 "No fault" 1 "Rear-right pulse counter fault" ;
VAL_ 166 RearLeftWheelPulseCounterFault 0 "No fault on the RRL pulse counter" 1 "Fault on the rear left pulse counter" ;
VAL_ 166 FrontRightWheelPulseCounterFault 0 "No fault on front-right pulse counter" 1 "Fault" ;
VAL_ 166 FrontLeftWheelPulseCounterFault 0 "No fault on the FRL pulse counter" 1 "Front left pulse counter fault" ;
VAL_ 168 LateralAccelerationPercent 127 "Not_available" ;
VAL_ 168 TelemetryPageStartRequest 0 "No request" 1 "Requested" ;
VAL_ 168 LongitudinalAccelerationPercent 127 "Not_available" ;
VAL_ 169 FlowStatus 0 "ContinueToSend" 1 "Wait" 2 "Overflow" ;
VAL_ 169 IsoTpFrameType 0 "SingleFrame" 1 "FirstFrame" 2 "ConsecutiveFrame" 3 "FlowControl" ;
VAL_ 182 SecuVitesse 0 "Speed unavailable" 1 "Speed unavailable" 2 "Speed unavailable" 3 "Speed unavailable" 4 "Speed unavailable" 5 "Speed unavailable" 6 "Speed unavailable" 7 "Speed unavailable" 8 "Speed unavailable" 9 "Speed unavailable" 10 "Gear available" 11 "Speed unavailable" 12 "Speed unavailable" 13 "Speed unavailable" 14 "Speed unavailable" 15 "Speed unavailable" ;
VAL_ 182 Securisation 0 "Speed information unavailable" 1 "Speed information available" ;
VAL_ 182 Speed 65535 "Not_available" ;
VAL_ 182 Rpm 65535 "Not_available" ;
VAL_ 189 SmartDevice5Enabled 0 "False" 1 "True" ;
VAL_ 189 SmartDevice4Enabled 0 "False" 1 "True" ;
VAL_ 189 SmartDevice3Enabled 0 "False" 1 "True" ;
VAL_ 189 SmartDevice2Enabled 0 "False" 1 "True" ;
VAL_ 189 SmartDevice1Enabled 0 "False" 1 "True" ;
VAL_ 189 SmartDevice5Zone 0 "Undetermined" 1 "Extended blind spot zone" 2 "BLE short zone" 3 "BLE inner zone" 4 "NFC inner zone" 5 "NFC exter zone" 7 "Unused value (111)" ;
VAL_ 189 SmartDevice4Zone 0 "Undetermined" 1 "Extended blind spot zone" 2 "BLE short zone" 3 "BLE inner zone" 4 "NFC inner zone" 5 "NFC exter zone" 7 "Unused value (111)" ;
VAL_ 189 SmartDevice3Zone 0 "Undetermined" 1 "Extended blind spot zone" 2 "BLE short zone" 3 "BLE inner zone" 4 "NFC inner zone" 5 "NFC exter zone" 7 "Unused value (111)" ;
VAL_ 189 SmartDevice2Zone 0 "Undetermined" 1 "Extended blind spot zone" 2 "BLE short zone" 3 "BLE inner zone" 4 "NFC inner zone" 5 "NFC exter zone" 7 "Unused value (111)" ;
VAL_ 189 SmartDevice1Zone 0 "Undetermined" 1 "Extended blind spot zone" 2 "BLE short zone" 3 "BLE inner zone" 4 "NFC inner zone" 5 "NFC exter zone" 7 "Unused value (111)" ;
VAL_ 189 HfaPollingStatus 0 "Inactive" 1 "Active" ;
VAL_ 189 HfaFeatureStatus 0 "Inactive" 1 "Active" ;
VAL_ 189 SmartDeviceFeatureStatus 0 "Inactive" 1 "Active" ;
VAL_ 189 SdcmAuthorizationStatus 0 "Inactive" 1 "Active" ;
VAL_ 189 WalUirFeatureStatus 0 "Inactive" 1 "Active" ;
VAL_ 189 CidLowEnergyAlert 0 "No alert" 1 "Alert" ;
VAL_ 189 HfaPollingType 1 "STOPPED" 2 "WEL" 3 "UIR" 4 "WAL" 5 "Post lock pending" ;
VAL_ 191 HandsFreeAccessAnticipati_78e7e7 0 "No request" 1 "Request" ;
VAL_ 191 HandsFreeAccessDiagnosticRequest 0 "No request" 1 "Request" ;
VAL_ 191 UirBackwardAreaInclusion 0 "Without backward area" 1 "With backward area" ;
VAL_ 191 WelcomeAccessLockingSoundRequest 0 "No sound" 1 "Sound 1" 2 "Sound 2" ;
VAL_ 191 LastLockActionSource 0 "Undefined" 1 "Remote key fob" 2 "Key" 3 "Automatic relocking" 4 "ADML" 5 "Remote" 8 "Automatic driving" 9 "Ignition on" 10 "Cabin button" 11 "menuperso" 12 "Door opening" 13 "Crash" 14 "Factory" ;
VAL_ 191 BluetoothSmartDeviceAuthe_322363 0 "No request" 1 "Request" ;
VAL_ 191 NfcSmartDeviceAuthenticat_268716 0 "No request" 1 "Request" ;
VAL_ 191 NfcCardAuthenticationRequest 0 "No request" 1 "Request" ;
VAL_ 191 CidAuthenticationRequest 0 "No request" 1 "Request" ;
VAL_ 191 CidSearchRequest 0 "None" 1 "Outside driver identification lock area" 2 "Outside identification, lock area, passenger" 3 "Outside ident lock area trunk" 4 "Outside identifier locking, anywhere in the area" 5 "Outside identified lock area, trunk special" 6 "Inside loc anywhere" ;
VAL_ 193 FlowStatus 0 "ContinueToSend" 1 "Wait" 2 "Overflow" ;
VAL_ 193 IsoTpFrameType 0 "SingleFrame" 1 "FirstFrame" 2 "ConsecutiveFrame" 3 "FlowControl" ;

SG_MUL_VAL_ 159 SingleFrameLength IsoTpFrameType 0-0;
SG_MUL_VAL_ 159 FirstFrameLength IsoTpFrameType 1-1;
SG_MUL_VAL_ 159 ConsecutiveSequence IsoTpFrameType 2-2;
SG_MUL_VAL_ 159 FlowStatus IsoTpFrameType 3-3;
SG_MUL_VAL_ 159 UnknownPciLow IsoTpFrameType 4-15;
SG_MUL_VAL_ 159 BlockSize IsoTpFrameType 3-3;
SG_MUL_VAL_ 159 SingleData1 IsoTpFrameType 0-0;
SG_MUL_VAL_ 159 ConsecutiveData1 IsoTpFrameType 2-2;
SG_MUL_VAL_ 159 UnknownData1 IsoTpFrameType 4-15;
SG_MUL_VAL_ 159 SeparationTimeRaw IsoTpFrameType 3-3;
SG_MUL_VAL_ 159 SingleData2 IsoTpFrameType 0-0;
SG_MUL_VAL_ 159 ConsecutiveData2 IsoTpFrameType 2-2;
SG_MUL_VAL_ 159 UnknownData2 IsoTpFrameType 4-15;
SG_MUL_VAL_ 159 FirstData1 IsoTpFrameType 1-1;
SG_MUL_VAL_ 159 SingleData3 IsoTpFrameType 0-0;
SG_MUL_VAL_ 159 ConsecutiveData3 IsoTpFrameType 2-2;
SG_MUL_VAL_ 159 UnknownData3 IsoTpFrameType 4-15;
SG_MUL_VAL_ 159 FirstData2 IsoTpFrameType 1-1;
SG_MUL_VAL_ 159 FlowPadding1 IsoTpFrameType 3-3;
SG_MUL_VAL_ 159 SingleData4 IsoTpFrameType 0-0;
SG_MUL_VAL_ 159 ConsecutiveData4 IsoTpFrameType 2-2;
SG_MUL_VAL_ 159 UnknownData4 IsoTpFrameType 4-15;
SG_MUL_VAL_ 159 FirstData3 IsoTpFrameType 1-1;
SG_MUL_VAL_ 159 FlowPadding2 IsoTpFrameType 3-3;
SG_MUL_VAL_ 159 SingleData5 IsoTpFrameType 0-0;
SG_MUL_VAL_ 159 ConsecutiveData5 IsoTpFrameType 2-2;
SG_MUL_VAL_ 159 UnknownData5 IsoTpFrameType 4-15;
SG_MUL_VAL_ 159 FirstData4 IsoTpFrameType 1-1;
SG_MUL_VAL_ 159 FlowPadding3 IsoTpFrameType 3-3;
SG_MUL_VAL_ 159 SingleData6 IsoTpFrameType 0-0;
SG_MUL_VAL_ 159 ConsecutiveData6 IsoTpFrameType 2-2;
SG_MUL_VAL_ 159 UnknownData6 IsoTpFrameType 4-15;
SG_MUL_VAL_ 159 FirstData5 IsoTpFrameType 1-1;
SG_MUL_VAL_ 159 FlowPadding4 IsoTpFrameType 3-3;
SG_MUL_VAL_ 159 SingleData7 IsoTpFrameType 0-0;
SG_MUL_VAL_ 159 ConsecutiveData7 IsoTpFrameType 2-2;
SG_MUL_VAL_ 159 UnknownData7 IsoTpFrameType 4-15;
SG_MUL_VAL_ 159 FirstData6 IsoTpFrameType 1-1;
SG_MUL_VAL_ 159 FlowPadding5 IsoTpFrameType 3-3;
SG_MUL_VAL_ 164 SingleFrameLength IsoTpFrameType 0-0;
SG_MUL_VAL_ 164 FirstFrameLength IsoTpFrameType 1-1;
SG_MUL_VAL_ 164 ConsecutiveSequence IsoTpFrameType 2-2;
SG_MUL_VAL_ 164 FlowStatus IsoTpFrameType 3-3;
SG_MUL_VAL_ 164 UnknownPciLow IsoTpFrameType 4-15;
SG_MUL_VAL_ 164 BlockSize IsoTpFrameType 3-3;
SG_MUL_VAL_ 164 SingleData1 IsoTpFrameType 0-0;
SG_MUL_VAL_ 164 ConsecutiveData1 IsoTpFrameType 2-2;
SG_MUL_VAL_ 164 UnknownData1 IsoTpFrameType 4-15;
SG_MUL_VAL_ 164 SeparationTimeRaw IsoTpFrameType 3-3;
SG_MUL_VAL_ 164 SingleData2 IsoTpFrameType 0-0;
SG_MUL_VAL_ 164 ConsecutiveData2 IsoTpFrameType 2-2;
SG_MUL_VAL_ 164 UnknownData2 IsoTpFrameType 4-15;
SG_MUL_VAL_ 164 FirstData1 IsoTpFrameType 1-1;
SG_MUL_VAL_ 164 SingleData3 IsoTpFrameType 0-0;
SG_MUL_VAL_ 164 ConsecutiveData3 IsoTpFrameType 2-2;
SG_MUL_VAL_ 164 UnknownData3 IsoTpFrameType 4-15;
SG_MUL_VAL_ 164 FirstData2 IsoTpFrameType 1-1;
SG_MUL_VAL_ 164 FlowPadding1 IsoTpFrameType 3-3;
SG_MUL_VAL_ 164 SingleData4 IsoTpFrameType 0-0;
SG_MUL_VAL_ 164 ConsecutiveData4 IsoTpFrameType 2-2;
SG_MUL_VAL_ 164 UnknownData4 IsoTpFrameType 4-15;
SG_MUL_VAL_ 164 FirstData3 IsoTpFrameType 1-1;
SG_MUL_VAL_ 164 FlowPadding2 IsoTpFrameType 3-3;
SG_MUL_VAL_ 164 SingleData5 IsoTpFrameType 0-0;
SG_MUL_VAL_ 164 ConsecutiveData5 IsoTpFrameType 2-2;
SG_MUL_VAL_ 164 UnknownData5 IsoTpFrameType 4-15;
SG_MUL_VAL_ 164 FirstData4 IsoTpFrameType 1-1;
SG_MUL_VAL_ 164 FlowPadding3 IsoTpFrameType 3-3;
SG_MUL_VAL_ 164 SingleData6 IsoTpFrameType 0-0;
SG_MUL_VAL_ 164 ConsecutiveData6 IsoTpFrameType 2-2;
SG_MUL_VAL_ 164 UnknownData6 IsoTpFrameType 4-15;
SG_MUL_VAL_ 164 FirstData5 IsoTpFrameType 1-1;
SG_MUL_VAL_ 164 FlowPadding4 IsoTpFrameType 3-3;
SG_MUL_VAL_ 164 SingleData7 IsoTpFrameType 0-0;
SG_MUL_VAL_ 164 ConsecutiveData7 IsoTpFrameType 2-2;
SG_MUL_VAL_ 164 UnknownData7 IsoTpFrameType 4-15;
SG_MUL_VAL_ 164 FirstData6 IsoTpFrameType 1-1;
SG_MUL_VAL_ 164 FlowPadding5 IsoTpFrameType 3-3;
SG_MUL_VAL_ 169 SingleFrameLength IsoTpFrameType 0-0;
SG_MUL_VAL_ 169 FirstFrameLength IsoTpFrameType 1-1;
SG_MUL_VAL_ 169 ConsecutiveSequence IsoTpFrameType 2-2;
SG_MUL_VAL_ 169 FlowStatus IsoTpFrameType 3-3;
SG_MUL_VAL_ 169 UnknownPciLow IsoTpFrameType 4-15;
SG_MUL_VAL_ 169 BlockSize IsoTpFrameType 3-3;
SG_MUL_VAL_ 169 SingleData1 IsoTpFrameType 0-0;
SG_MUL_VAL_ 169 ConsecutiveData1 IsoTpFrameType 2-2;
SG_MUL_VAL_ 169 UnknownData1 IsoTpFrameType 4-15;
SG_MUL_VAL_ 169 SeparationTimeRaw IsoTpFrameType 3-3;
SG_MUL_VAL_ 169 SingleData2 IsoTpFrameType 0-0;
SG_MUL_VAL_ 169 ConsecutiveData2 IsoTpFrameType 2-2;
SG_MUL_VAL_ 169 UnknownData2 IsoTpFrameType 4-15;
SG_MUL_VAL_ 169 FirstData1 IsoTpFrameType 1-1;
SG_MUL_VAL_ 169 SingleData3 IsoTpFrameType 0-0;
SG_MUL_VAL_ 169 ConsecutiveData3 IsoTpFrameType 2-2;
SG_MUL_VAL_ 169 UnknownData3 IsoTpFrameType 4-15;
SG_MUL_VAL_ 169 FirstData2 IsoTpFrameType 1-1;
SG_MUL_VAL_ 169 FlowPadding1 IsoTpFrameType 3-3;
SG_MUL_VAL_ 169 SingleData4 IsoTpFrameType 0-0;
SG_MUL_VAL_ 169 ConsecutiveData4 IsoTpFrameType 2-2;
SG_MUL_VAL_ 169 UnknownData4 IsoTpFrameType 4-15;
SG_MUL_VAL_ 169 FirstData3 IsoTpFrameType 1-1;
SG_MUL_VAL_ 169 FlowPadding2 IsoTpFrameType 3-3;
SG_MUL_VAL_ 169 SingleData5 IsoTpFrameType 0-0;
SG_MUL_VAL_ 169 ConsecutiveData5 IsoTpFrameType 2-2;
SG_MUL_VAL_ 169 UnknownData5 IsoTpFrameType 4-15;
SG_MUL_VAL_ 169 FirstData4 IsoTpFrameType 1-1;
SG_MUL_VAL_ 169 FlowPadding3 IsoTpFrameType 3-3;
SG_MUL_VAL_ 169 SingleData6 IsoTpFrameType 0-0;
SG_MUL_VAL_ 169 ConsecutiveData6 IsoTpFrameType 2-2;
SG_MUL_VAL_ 169 UnknownData6 IsoTpFrameType 4-15;
SG_MUL_VAL_ 169 FirstData5 IsoTpFrameType 1-1;
SG_MUL_VAL_ 169 FlowPadding4 IsoTpFrameType 3-3;
SG_MUL_VAL_ 169 SingleData7 IsoTpFrameType 0-0;
SG_MUL_VAL_ 169 ConsecutiveData7 IsoTpFrameType 2-2;
SG_MUL_VAL_ 169 UnknownData7 IsoTpFrameType 4-15;
SG_MUL_VAL_ 169 FirstData6 IsoTpFrameType 1-1;
SG_MUL_VAL_ 169 FlowPadding5 IsoTpFrameType 3-3;
SG_MUL_VAL_ 193 SingleFrameLength IsoTpFrameType 0-0;
SG_MUL_VAL_ 193 FirstFrameLength IsoTpFrameType 1-1;
SG_MUL_VAL_ 193 ConsecutiveSequence IsoTpFrameType 2-2;
SG_MUL_VAL_ 193 FlowStatus IsoTpFrameType 3-3;
SG_MUL_VAL_ 193 UnknownPciLow IsoTpFrameType 4-15;
SG_MUL_VAL_ 193 BlockSize IsoTpFrameType 3-3;
SG_MUL_VAL_ 193 SingleData1 IsoTpFrameType 0-0;
SG_MUL_VAL_ 193 ConsecutiveData1 IsoTpFrameType 2-2;
SG_MUL_VAL_ 193 UnknownData1 IsoTpFrameType 4-15;
SG_MUL_VAL_ 193 SeparationTimeRaw IsoTpFrameType 3-3;
SG_MUL_VAL_ 193 SingleData2 IsoTpFrameType 0-0;
SG_MUL_VAL_ 193 ConsecutiveData2 IsoTpFrameType 2-2;
SG_MUL_VAL_ 193 UnknownData2 IsoTpFrameType 4-15;
SG_MUL_VAL_ 193 FirstData1 IsoTpFrameType 1-1;
SG_MUL_VAL_ 193 SingleData3 IsoTpFrameType 0-0;
SG_MUL_VAL_ 193 ConsecutiveData3 IsoTpFrameType 2-2;
SG_MUL_VAL_ 193 UnknownData3 IsoTpFrameType 4-15;
SG_MUL_VAL_ 193 FirstData2 IsoTpFrameType 1-1;
SG_MUL_VAL_ 193 FlowPadding1 IsoTpFrameType 3-3;
SG_MUL_VAL_ 193 SingleData4 IsoTpFrameType 0-0;
SG_MUL_VAL_ 193 ConsecutiveData4 IsoTpFrameType 2-2;
SG_MUL_VAL_ 193 UnknownData4 IsoTpFrameType 4-15;
SG_MUL_VAL_ 193 FirstData3 IsoTpFrameType 1-1;
SG_MUL_VAL_ 193 FlowPadding2 IsoTpFrameType 3-3;
SG_MUL_VAL_ 193 SingleData5 IsoTpFrameType 0-0;
SG_MUL_VAL_ 193 ConsecutiveData5 IsoTpFrameType 2-2;
SG_MUL_VAL_ 193 UnknownData5 IsoTpFrameType 4-15;
SG_MUL_VAL_ 193 FirstData4 IsoTpFrameType 1-1;
SG_MUL_VAL_ 193 FlowPadding3 IsoTpFrameType 3-3;
SG_MUL_VAL_ 193 SingleData6 IsoTpFrameType 0-0;
SG_MUL_VAL_ 193 ConsecutiveData6 IsoTpFrameType 2-2;
SG_MUL_VAL_ 193 UnknownData6 IsoTpFrameType 4-15;
SG_MUL_VAL_ 193 FirstData5 IsoTpFrameType 1-1;
SG_MUL_VAL_ 193 FlowPadding4 IsoTpFrameType 3-3;
SG_MUL_VAL_ 193 SingleData7 IsoTpFrameType 0-0;
SG_MUL_VAL_ 193 ConsecutiveData7 IsoTpFrameType 2-2;
SG_MUL_VAL_ 193 UnknownData7 IsoTpFrameType 4-15;
SG_MUL_VAL_ 193 FirstData6 IsoTpFrameType 1-1;
SG_MUL_VAL_ 193 FlowPadding5 IsoTpFrameType 3-3;
